VERSION "Version"

NS_ :

BS_:

BU_: ADC FLR FRR Tester

BO_ 791 FRR_Obj_22: 32 FRR
 SG_ SGU22_Msg_CheckSum : 7|8@0+ (1,0) [0|255] ""  ADC
 SG_ SGU22_Msg_AliveCounter : 11|4@0+ (1,0) [0|14] ""  ADC
 SG_ SGU22_BlockCounter : 15|4@0+ (1,0) [0|15] ""  ADC
 SG_ SGU22_Object_ID : 23|8@0+ (1,0) [0|255] ""  ADC
 SG_ SGU22_Object_wExist : 28|5@0+ (0.03125,0) [0|0.96875] ""  ADC
 SG_ SGU22_Object_Type : 31|3@0+ (1,0) [0|7] ""  ADC
 SG_ SGU22_Object_Motion_Pattern : 34|3@0+ (1,0) [0|7] ""  ADC
 SG_ SGU22_Object_wObstacle : 39|5@0+ (0.03125,0) [0|0.96875] ""  ADC
 SG_ SGU22_Object_dx : 43|12@0+ (0.0625,-128) [-128|127.9375] "m"  ADC
 SG_ SGU22_Object_dy : 59|12@0+ (0.125,-128) [-128|127.875] "m"  ADC
 SG_ SGU22_Object_DistLong_rms : 79|16@0+ (0.001953125,0) [0|127.998046875] "m"  ADC
 SG_ SGU22_Obj_DistLat_rms : 95|16@0+ (0.001953125,0) [0|127.998046875] "m"  ADC
 SG_ SGU22_Object_vx : 107|12@0+ (0.0625,-128) [-128|127.9375] "m/s"  ADC
 SG_ SGU22_Object_vy : 123|12@0+ (0.0625,-128) [-128|127.9375] "m/s"  ADC
 SG_ SGU22_Obj_VrelLong_rms : 143|16@0+ (0.001953125,0) [0|127.998046875] "m/s"  ADC
 SG_ SGU22_Obj_Vrelat_rms : 159|16@0+ (0.001953125,0) [0|127.998046875] "m/s"  ADC
 SG_ SGU22_Object_ax : 170|11@0+ (0.03125,-16) [-16|15.96875] "m/s^2"  ADC
 SG_ SGU22_Object_ay : 191|11@0+ (0.03125,-16) [-16|15.96875] "m/s^2"  ADC
 SG_ SGU22_Object_DetStatus : 173|3@0+ (1,0) [0|7] ""  ADC
 SG_ SGU22_LifeCycles_OBJ : 196|8@0+ (1,0) [0|255] ""  ADC
 SG_ SGU22_ObjRCS_22 : 204|10@0+ (0.125,-50) [-50|70] "dBm2"  ADC
 SG_ SGU22_Object_dx_Rear : 209|12@0+ (0.0625,-128) [-128|127.9375] "m"  ADC
 SG_ SGU22_Object_dy_Rear : 229|12@0+ (0.125,-128) [-128|127.875] "m"  ADC

BO_ 792 FRR_Obj_23: 32 FRR
 SG_ SGU23_Msg_CheckSum : 7|8@0+ (1,0) [0|255] ""  ADC
 SG_ SGU23_Msg_AliveCounter : 11|4@0+ (1,0) [0|14] ""  ADC
 SG_ SGU23_BlockCounter : 15|4@0+ (1,0) [0|15] ""  ADC
 SG_ SGU23_Object_ID : 23|8@0+ (1,0) [0|255] ""  ADC
 SG_ SGU23_Object_wExist : 28|5@0+ (0.03125,0) [0|0.96875] ""  ADC
 SG_ SGU23_Object_Type : 31|3@0+ (1,0) [0|7] ""  ADC
 SG_ SGU23_Object_Motion_Pattern : 34|3@0+ (1,0) [0|7] ""  ADC
 SG_ SGU23_Object_wObstacle : 39|5@0+ (0.03125,0) [0|0.96875] ""  ADC
 SG_ SGU23_Object_dx : 43|12@0+ (0.0625,-128) [-128|127.9375] "m"  ADC
 SG_ SGU23_Object_dy : 59|12@0+ (0.125,-128) [-128|127.875] "m"  ADC
 SG_ SGU23_Object_DistLong_rms : 79|16@0+ (0.001953125,0) [0|127.998046875] "m"  ADC
 SG_ SGU23_Obj_DistLat_rms : 95|16@0+ (0.001953125,0) [0|127.998046875] "m"  ADC
 SG_ SGU23_Object_vx : 107|12@0+ (0.0625,-128) [-128|127.9375] "m/s"  ADC
 SG_ SGU23_Object_vy : 123|12@0+ (0.0625,-128) [-128|127.9375] "m/s"  ADC
 SG_ SGU23_Obj_VrelLong_rms : 143|16@0+ (0.001953125,0) [0|127.998046875] "m/s"  ADC
 SG_ SGU23_Obj_Vrelat_rms : 159|16@0+ (0.001953125,0) [0|127.998046875] "m/s"  ADC
 SG_ SGU23_Object_ax : 170|11@0+ (0.03125,-16) [-16|15.96875] "m/s^2"  ADC
 SG_ SGU23_Object_ay : 191|11@0+ (0.03125,-16) [-16|15.96875] "m/s^2"  ADC
 SG_ SGU23_Object_DetStatus : 173|3@0+ (1,0) [0|7] ""  ADC
 SG_ SGU23_LifeCycles_OBJ : 196|8@0+ (1,0) [0|255] ""  ADC
 SG_ SGU23_ObjRCS_23 : 204|10@0+ (0.125,-50) [-50|70] "dBm2"  ADC
 SG_ SGU23_Object_dx_Rear : 209|12@0+ (0.0625,-128) [-128|127.9375] "m"  ADC
 SG_ SGU23_Object_dy_Rear : 229|12@0+ (0.125,-128) [-128|127.875] "m"  ADC

BO_ 793 FRR_Obj_24: 32 FRR
 SG_ SGU24_Msg_CheckSum : 7|8@0+ (1,0) [0|255] ""  ADC
 SG_ SGU24_Msg_AliveCounter : 11|4@0+ (1,0) [0|14] ""  ADC
 SG_ SGU24_BlockCounter : 15|4@0+ (1,0) [0|15] ""  ADC
 SG_ SGU24_Object_ID : 23|8@0+ (1,0) [0|255] ""  ADC
 SG_ SGU24_Object_wExist : 28|5@0+ (0.03125,0) [0|0.96875] ""  ADC
 SG_ SGU24_Object_Type : 31|3@0+ (1,0) [0|7] ""  ADC
 SG_ SGU24_Object_Motion_Pattern : 34|3@0+ (1,0) [0|7] ""  ADC
 SG_ SGU24_Object_wObstacle : 39|5@0+ (0.03125,0) [0|0.96875] ""  ADC
 SG_ SGU24_Object_dx : 43|12@0+ (0.0625,-128) [-128|127.9375] "m"  ADC
 SG_ SGU24_Object_dy : 59|12@0+ (0.125,-128) [-128|127.875] "m"  ADC
 SG_ SGU24_Object_DistLong_rms : 79|16@0+ (0.001953125,0) [0|127.998046875] "m"  ADC
 SG_ SGU24_Obj_DistLat_rms : 95|16@0+ (0.001953125,0) [0|127.998046875] "m"  ADC
 SG_ SGU24_Object_vx : 107|12@0+ (0.0625,-128) [-128|127.9375] "m/s"  ADC
 SG_ SGU24_Object_vy : 123|12@0+ (0.0625,-128) [-128|127.9375] "m/s"  ADC
 SG_ SGU24_Obj_VrelLong_rms : 143|16@0+ (0.001953125,0) [0|127.998046875] "m/s"  ADC
 SG_ SGU24_Obj_Vrelat_rms : 159|16@0+ (0.001953125,0) [0|127.998046875] "m/s"  ADC
 SG_ SGU24_Object_ax : 170|11@0+ (0.03125,-16) [-16|15.96875] "m/s^2"  ADC
 SG_ SGU24_Object_ay : 191|11@0+ (0.03125,-16) [-16|15.96875] "m/s^2"  ADC
 SG_ SGU24_Object_DetStatus : 173|3@0+ (1,0) [0|7] ""  ADC
 SG_ SGU24_LifeCycles_OBJ : 196|8@0+ (1,0) [0|255] ""  ADC
 SG_ SGU24_ObjRCS_24 : 204|10@0+ (0.125,-50) [-50|70] "dBm2"  ADC
 SG_ SGU24_Object_dx_Rear : 209|12@0+ (0.0625,-128) [-128|127.9375] "m"  ADC
 SG_ SGU24_Object_dy_Rear : 229|12@0+ (0.125,-128) [-128|127.875] "m"  ADC

BO_ 794 FRR_Obj_25: 32 FRR
 SG_ SGU25_Msg_CheckSum : 7|8@0+ (1,0) [0|255] ""  ADC
 SG_ SGU25_Msg_AliveCounter : 11|4@0+ (1,0) [0|14] ""  ADC
 SG_ SGU25_BlockCounter : 15|4@0+ (1,0) [0|15] ""  ADC
 SG_ SGU25_Object_ID : 23|8@0+ (1,0) [0|255] ""  ADC
 SG_ SGU25_Object_wExist : 28|5@0+ (0.03125,0) [0|0.96875] ""  ADC
 SG_ SGU25_Object_Type : 31|3@0+ (1,0) [0|7] ""  ADC
 SG_ SGU25_Object_Motion_Pattern : 34|3@0+ (1,0) [0|7] ""  ADC
 SG_ SGU25_Object_wObstacle : 39|5@0+ (0.03125,0) [0|0.96875] ""  ADC
 SG_ SGU25_Object_dx : 43|12@0+ (0.0625,-128) [-128|127.9375] "m"  ADC
 SG_ SGU25_Object_dy : 59|12@0+ (0.125,-128) [-128|127.875] "m"  ADC
 SG_ SGU25_Object_DistLong_rms : 79|16@0+ (0.001953125,0) [0|127.998046875] "m"  ADC
 SG_ SGU25_Obj_DistLat_rms : 95|16@0+ (0.001953125,0) [0|127.998046875] "m"  ADC
 SG_ SGU25_Object_vx : 107|12@0+ (0.0625,-128) [-128|127.9375] "m/s"  ADC
 SG_ SGU25_Object_vy : 123|12@0+ (0.0625,-128) [-128|127.9375] "m/s"  ADC
 SG_ SGU25_Obj_VrelLong_rms : 143|16@0+ (0.001953125,0) [0|127.998046875] "m/s"  ADC
 SG_ SGU25_Obj_Vrelat_rms : 159|16@0+ (0.001953125,0) [0|127.998046875] "m/s"  ADC
 SG_ SGU25_Object_ax : 170|11@0+ (0.03125,-16) [-16|15.96875] "m/s^2"  ADC
 SG_ SGU25_Object_ay : 191|11@0+ (0.03125,-16) [-16|15.96875] "m/s^2"  ADC
 SG_ SGU25_Object_DetStatus : 173|3@0+ (1,0) [0|7] ""  ADC
 SG_ SGU25_LifeCycles_OBJ : 196|8@0+ (1,0) [0|255] ""  ADC
 SG_ SGU25_ObjRCS_25 : 204|10@0+ (0.125,-50) [-50|70] "dBm2"  ADC
 SG_ SGU25_Object_dx_Rear : 209|12@0+ (0.0625,-128) [-128|127.9375] "m"  ADC
 SG_ SGU25_Object_dy_Rear : 229|12@0+ (0.125,-128) [-128|127.875] "m"  ADC

BO_ 795 FRR_Obj_26: 32 FRR
 SG_ SGU26_Msg_CheckSum : 7|8@0+ (1,0) [0|255] ""  ADC
 SG_ SGU26_Msg_AliveCounter : 11|4@0+ (1,0) [0|14] ""  ADC
 SG_ SGU26_BlockCounter : 15|4@0+ (1,0) [0|15] ""  ADC
 SG_ SGU26_Object_ID : 23|8@0+ (1,0) [0|255] ""  ADC
 SG_ SGU26_Object_wExist : 28|5@0+ (0.03125,0) [0|0.96875] ""  ADC
 SG_ SGU26_Object_Type : 31|3@0+ (1,0) [0|7] ""  ADC
 SG_ SGU26_Object_Motion_Pattern : 34|3@0+ (1,0) [0|7] ""  ADC
 SG_ SGU26_Object_wObstacle : 39|5@0+ (0.03125,0) [0|0.96875] ""  ADC
 SG_ SGU26_Object_dx : 43|12@0+ (0.0625,-128) [-128|127.9375] "m"  ADC
 SG_ SGU26_Object_dy : 59|12@0+ (0.125,-128) [-128|127.875] "m"  ADC
 SG_ SGU26_Object_DistLong_rms : 79|16@0+ (0.001953125,0) [0|127.998046875] "m"  ADC
 SG_ SGU26_Obj_DistLat_rms : 95|16@0+ (0.001953125,0) [0|127.998046875] "m"  ADC
 SG_ SGU26_Object_vx : 107|12@0+ (0.0625,-128) [-128|127.9375] "m/s"  ADC
 SG_ SGU26_Object_vy : 123|12@0+ (0.0625,-128) [-128|127.9375] "m/s"  ADC
 SG_ SGU26_Obj_VrelLong_rms : 143|16@0+ (0.001953125,0) [0|127.998046875] "m/s"  ADC
 SG_ SGU26_Obj_Vrelat_rms : 159|16@0+ (0.001953125,0) [0|127.998046875] "m/s"  ADC
 SG_ SGU26_Object_ax : 170|11@0+ (0.03125,-16) [-16|15.96875] "m/s^2"  ADC
 SG_ SGU26_Object_ay : 191|11@0+ (0.03125,-16) [-16|15.96875] "m/s^2"  ADC
 SG_ SGU26_Object_DetStatus : 173|3@0+ (1,0) [0|7] ""  ADC
 SG_ SGU26_LifeCycles_OBJ : 196|8@0+ (1,0) [0|255] ""  ADC
 SG_ SGU26_ObjRCS_26 : 204|10@0+ (0.125,-50) [-50|70] "dBm2"  ADC
 SG_ SGU26_Object_dx_Rear : 209|12@0+ (0.0625,-128) [-128|127.9375] "m"  ADC
 SG_ SGU26_Object_dy_Rear : 229|12@0+ (0.125,-128) [-128|127.875] "m"  ADC

BO_ 796 FRR_Obj_27: 32 FRR
 SG_ SGU27_Msg_CheckSum : 7|8@0+ (1,0) [0|255] ""  ADC
 SG_ SGU27_Msg_AliveCounter : 11|4@0+ (1,0) [0|14] ""  ADC
 SG_ SGU27_BlockCounter : 15|4@0+ (1,0) [0|15] ""  ADC
 SG_ SGU27_Object_ID : 23|8@0+ (1,0) [0|255] ""  ADC
 SG_ SGU27_Object_wExist : 28|5@0+ (0.03125,0) [0|0.96875] ""  ADC
 SG_ SGU27_Object_Type : 31|3@0+ (1,0) [0|7] ""  ADC
 SG_ SGU27_Object_Motion_Pattern : 34|3@0+ (1,0) [0|7] ""  ADC
 SG_ SGU27_Object_wObstacle : 39|5@0+ (0.03125,0) [0|0.96875] ""  ADC
 SG_ SGU27_Object_dx : 43|12@0+ (0.0625,-128) [-128|127.9375] "m"  ADC
 SG_ SGU27_Object_dy : 59|12@0+ (0.125,-128) [-128|127.875] "m"  ADC
 SG_ SGU27_Object_DistLong_rms : 79|16@0+ (0.001953125,0) [0|127.998046875] "m"  ADC
 SG_ SGU27_Obj_DistLat_rms : 95|16@0+ (0.001953125,0) [0|127.998046875] "m"  ADC
 SG_ SGU27_Object_vx : 107|12@0+ (0.0625,-128) [-128|127.9375] "m/s"  ADC
 SG_ SGU27_Object_vy : 123|12@0+ (0.0625,-128) [-128|127.9375] "m/s"  ADC
 SG_ SGU27_Obj_VrelLong_rms : 143|16@0+ (0.001953125,0) [0|127.998046875] "m/s"  ADC
 SG_ SGU27_Obj_Vrelat_rms : 159|16@0+ (0.001953125,0) [0|127.998046875] "m/s"  ADC
 SG_ SGU27_Object_ax : 170|11@0+ (0.03125,-16) [-16|15.96875] "m/s^2"  ADC
 SG_ SGU27_Object_ay : 191|11@0+ (0.03125,-16) [-16|15.96875] "m/s^2"  ADC
 SG_ SGU27_Object_DetStatus : 173|3@0+ (1,0) [0|7] ""  ADC
 SG_ SGU27_LifeCycles_OBJ : 196|8@0+ (1,0) [0|255] ""  ADC
 SG_ SGU27_ObjRCS_27 : 204|10@0+ (0.125,-50) [-50|70] "dBm2"  ADC
 SG_ SGU27_Object_dx_Rear : 209|12@0+ (0.0625,-128) [-128|127.9375] "m"  ADC
 SG_ SGU27_Object_dy_Rear : 229|12@0+ (0.125,-128) [-128|127.875] "m"  ADC

BO_ 797 FRR_Obj_28: 32 FRR
 SG_ SGU28_Msg_CheckSum : 7|8@0+ (1,0) [0|255] ""  ADC
 SG_ SGU28_Msg_AliveCounter : 11|4@0+ (1,0) [0|14] ""  ADC
 SG_ SGU28_BlockCounter : 15|4@0+ (1,0) [0|15] ""  ADC
 SG_ SGU28_Object_ID : 23|8@0+ (1,0) [0|255] ""  ADC
 SG_ SGU28_Object_wExist : 28|5@0+ (0.03125,0) [0|0.96875] ""  ADC
 SG_ SGU28_Object_Type : 31|3@0+ (1,0) [0|7] ""  ADC
 SG_ SGU28_Object_Motion_Pattern : 34|3@0+ (1,0) [0|7] ""  ADC
 SG_ SGU28_Object_wObstacle : 39|5@0+ (0.03125,0) [0|0.96875] ""  ADC
 SG_ SGU28_Object_dx : 43|12@0+ (0.0625,-128) [-128|127.9375] "m"  ADC
 SG_ SGU28_Object_dy : 59|12@0+ (0.125,-128) [-128|127.875] "m"  ADC
 SG_ SGU28_Object_DistLong_rms : 79|16@0+ (0.001953125,0) [0|127.998046875] "m"  ADC
 SG_ SGU28_Obj_DistLat_rms : 95|16@0+ (0.001953125,0) [0|127.998046875] "m"  ADC
 SG_ SGU28_Object_vx : 107|12@0+ (0.0625,-128) [-128|127.9375] "m/s"  ADC
 SG_ SGU28_Object_vy : 123|12@0+ (0.0625,-128) [-128|127.9375] "m/s"  ADC
 SG_ SGU28_Obj_VrelLong_rms : 143|16@0+ (0.001953125,0) [0|127.998046875] "m/s"  ADC
 SG_ SGU28_Obj_Vrelat_rms : 159|16@0+ (0.001953125,0) [0|127.998046875] "m/s"  ADC
 SG_ SGU28_Object_ax : 170|11@0+ (0.03125,-16) [-16|15.96875] "m/s^2"  ADC
 SG_ SGU28_Object_ay : 191|11@0+ (0.03125,-16) [-16|15.96875] "m/s^2"  ADC
 SG_ SGU28_Object_DetStatus : 173|3@0+ (1,0) [0|7] ""  ADC
 SG_ SGU28_LifeCycles_OBJ : 196|8@0+ (1,0) [0|255] ""  ADC
 SG_ SGU28_ObjRCS_28 : 204|10@0+ (0.125,-50) [-50|70] "dBm2"  ADC
 SG_ SGU28_Object_dx_Rear : 209|12@0+ (0.0625,-128) [-128|127.9375] "m"  ADC
 SG_ SGU28_Object_dy_Rear : 229|12@0+ (0.125,-128) [-128|127.875] "m"  ADC

BO_ 798 FRR_Obj_29: 32 FRR
 SG_ SGU29_Msg_CheckSum : 7|8@0+ (1,0) [0|255] ""  ADC
 SG_ SGU29_Msg_AliveCounter : 11|4@0+ (1,0) [0|14] ""  ADC
 SG_ SGU29_BlockCounter : 15|4@0+ (1,0) [0|15] ""  ADC
 SG_ SGU29_Object_ID : 23|8@0+ (1,0) [0|255] ""  ADC
 SG_ SGU29_Object_wExist : 28|5@0+ (0.03125,0) [0|0.96875] ""  ADC
 SG_ SGU29_Object_Type : 31|3@0+ (1,0) [0|7] ""  ADC
 SG_ SGU29_Object_Motion_Pattern : 34|3@0+ (1,0) [0|7] ""  ADC
 SG_ SGU29_Object_wObstacle : 39|5@0+ (0.03125,0) [0|0.96875] ""  ADC
 SG_ SGU29_Object_dx : 43|12@0+ (0.0625,-128) [-128|127.9375] "m"  ADC
 SG_ SGU29_Object_dy : 59|12@0+ (0.125,-128) [-128|127.875] "m"  ADC
 SG_ SGU29_Object_DistLong_rms : 79|16@0+ (0.001953125,0) [0|127.998046875] "m"  ADC
 SG_ SGU29_Obj_DistLat_rms : 95|16@0+ (0.001953125,0) [0|127.998046875] "m"  ADC
 SG_ SGU29_Object_vx : 107|12@0+ (0.0625,-128) [-128|127.9375] "m/s"  ADC
 SG_ SGU29_Object_vy : 123|12@0+ (0.0625,-128) [-128|127.9375] "m/s"  ADC
 SG_ SGU29_Obj_VrelLong_rms : 143|16@0+ (0.001953125,0) [0|127.998046875] "m/s"  ADC
 SG_ SGU29_Obj_Vrelat_rms : 159|16@0+ (0.001953125,0) [0|127.998046875] "m/s"  ADC
 SG_ SGU29_Object_ax : 170|11@0+ (0.03125,-16) [-16|15.96875] "m/s^2"  ADC
 SG_ SGU29_Object_ay : 191|11@0+ (0.03125,-16) [-16|15.96875] "m/s^2"  ADC
 SG_ SGU29_Object_DetStatus : 173|3@0+ (1,0) [0|7] ""  ADC
 SG_ SGU29_LifeCycles_OBJ : 196|8@0+ (1,0) [0|255] ""  ADC
 SG_ SGU29_ObjRCS_29 : 204|10@0+ (0.125,-50) [-50|70] "dBm2"  ADC
 SG_ SGU29_Object_dx_Rear : 209|12@0+ (0.0625,-128) [-128|127.9375] "m"  ADC
 SG_ SGU29_Object_dy_Rear : 229|12@0+ (0.125,-128) [-128|127.875] "m"  ADC

BO_ 799 FRR_Obj_30: 32 FRR
 SG_ SGU30_Msg_CheckSum : 7|8@0+ (1,0) [0|255] ""  ADC
 SG_ SGU30_Msg_AliveCounter : 11|4@0+ (1,0) [0|14] ""  ADC
 SG_ SGU30_BlockCounter : 15|4@0+ (1,0) [0|15] ""  ADC
 SG_ SGU30_Object_ID : 23|8@0+ (1,0) [0|255] ""  ADC
 SG_ SGU30_Object_wExist : 28|5@0+ (0.03125,0) [0|0.96875] ""  ADC
 SG_ SGU30_Object_Type : 31|3@0+ (1,0) [0|7] ""  ADC
 SG_ SGU30_Object_Motion_Pattern : 34|3@0+ (1,0) [0|7] ""  ADC
 SG_ SGU30_Object_wObstacle : 39|5@0+ (0.03125,0) [0|0.96875] ""  ADC
 SG_ SGU30_Object_dx : 43|12@0+ (0.0625,-128) [-128|127.9375] "m"  ADC
 SG_ SGU30_Object_dy : 59|12@0+ (0.125,-128) [-128|127.875] "m"  ADC
 SG_ SGU30_Object_DistLong_rms : 79|16@0+ (0.001953125,0) [0|127.998046875] "m"  ADC
 SG_ SGU30_Obj_DistLat_rms : 95|16@0+ (0.001953125,0) [0|127.998046875] "m"  ADC
 SG_ SGU30_Object_vx : 107|12@0+ (0.0625,-128) [-128|127.9375] "m/s"  ADC
 SG_ SGU30_Object_vy : 123|12@0+ (0.0625,-128) [-128|127.9375] "m/s"  ADC
 SG_ SGU30_Obj_VrelLong_rms : 143|16@0+ (0.001953125,0) [0|127.998046875] "m/s"  ADC
 SG_ SGU30_Obj_Vrelat_rms : 159|16@0+ (0.001953125,0) [0|127.998046875] "m/s"  ADC
 SG_ SGU30_Object_ax : 170|11@0+ (0.03125,-16) [-16|15.96875] "m/s^2"  ADC
 SG_ SGU30_Object_ay : 191|11@0+ (0.03125,-16) [-16|15.96875] "m/s^2"  ADC
 SG_ SGU30_Object_DetStatus : 173|3@0+ (1,0) [0|7] ""  ADC
 SG_ SGU30_LifeCycles_OBJ : 196|8@0+ (1,0) [0|255] ""  ADC
 SG_ SGU30_ObjRCS_30 : 204|10@0+ (0.125,-50) [-50|70] "dBm2"  ADC
 SG_ SGU30_Object_dx_Rear : 209|12@0+ (0.0625,-128) [-128|127.9375] "m"  ADC
 SG_ SGU30_Object_dy_Rear : 229|12@0+ (0.125,-128) [-128|127.875] "m"  ADC

BO_ 800 FRR_Obj_31: 32 FRR
 SG_ SGU31_Msg_CheckSum : 7|8@0+ (1,0) [0|255] ""  ADC
 SG_ SGU31_Msg_AliveCounter : 11|4@0+ (1,0) [0|14] ""  ADC
 SG_ SGU31_BlockCounter : 15|4@0+ (1,0) [0|15] ""  ADC
 SG_ SGU31_Object_ID : 23|8@0+ (1,0) [0|255] ""  ADC
 SG_ SGU31_Object_wExist : 28|5@0+ (0.03125,0) [0|0.96875] ""  ADC
 SG_ SGU31_Object_Type : 31|3@0+ (1,0) [0|7] ""  ADC
 SG_ SGU31_Object_Motion_Pattern : 34|3@0+ (1,0) [0|7] ""  ADC
 SG_ SGU31_Object_wObstacle : 39|5@0+ (0.03125,0) [0|0.96875] ""  ADC
 SG_ SGU31_Object_dx : 43|12@0+ (0.0625,-128) [-128|127.9375] "m"  ADC
 SG_ SGU31_Object_dy : 59|12@0+ (0.125,-128) [-128|127.875] "m"  ADC
 SG_ SGU31_Object_DistLong_rms : 79|16@0+ (0.001953125,0) [0|127.998046875] "m"  ADC
 SG_ SGU31_Obj_DistLat_rms : 95|16@0+ (0.001953125,0) [0|127.998046875] "m"  ADC
 SG_ SGU31_Object_vx : 107|12@0+ (0.0625,-128) [-128|127.9375] "m/s"  ADC
 SG_ SGU31_Object_vy : 123|12@0+ (0.0625,-128) [-128|127.9375] "m/s"  ADC
 SG_ SGU31_Obj_VrelLong_rms : 143|16@0+ (0.001953125,0) [0|127.998046875] "m/s"  ADC
 SG_ SGU31_Obj_Vrelat_rms : 159|16@0+ (0.001953125,0) [0|127.998046875] "m/s"  ADC
 SG_ SGU31_Object_ax : 170|11@0+ (0.03125,-16) [-16|15.96875] "m/s^2"  ADC
 SG_ SGU31_Object_ay : 191|11@0+ (0.03125,-16) [-16|15.96875] "m/s^2"  ADC
 SG_ SGU31_Object_DetStatus : 173|3@0+ (1,0) [0|7] ""  ADC
 SG_ SGU31_LifeCycles_OBJ : 196|8@0+ (1,0) [0|255] ""  ADC
 SG_ SGU31_ObjRCS_31 : 204|10@0+ (0.125,-50) [-50|70] "dBm2"  ADC
 SG_ SGU31_Object_dx_Rear : 209|12@0+ (0.0625,-128) [-128|127.9375] "m"  ADC
 SG_ SGU31_Object_dy_Rear : 229|12@0+ (0.125,-128) [-128|127.875] "m"  ADC

BO_ 801 FRR_Obj_32: 32 FRR
 SG_ SGU32_Msg_CheckSum : 7|8@0+ (1,0) [0|255] ""  ADC
 SG_ SGU32_Msg_AliveCounter : 11|4@0+ (1,0) [0|14] ""  ADC
 SG_ SGU32_BlockCounter : 15|4@0+ (1,0) [0|15] ""  ADC
 SG_ SGU32_Object_ID : 23|8@0+ (1,0) [0|255] ""  ADC
 SG_ SGU32_Object_wExist : 28|5@0+ (0.03125,0) [0|0.96875] ""  ADC
 SG_ SGU32_Object_Type : 31|3@0+ (1,0) [0|7] ""  ADC
 SG_ SGU32_Object_Motion_Pattern : 34|3@0+ (1,0) [0|7] ""  ADC
 SG_ SGU32_Object_wObstacle : 39|5@0+ (0.03125,0) [0|0.96875] ""  ADC
 SG_ SGU32_Object_dx : 43|12@0+ (0.0625,-128) [-128|127.9375] "m"  ADC
 SG_ SGU32_Object_dy : 59|12@0+ (0.125,-128) [-128|127.875] "m"  ADC
 SG_ SGU32_Object_DistLong_rms : 79|16@0+ (0.001953125,0) [0|127.998046875] "m"  ADC
 SG_ SGU32_Obj_DistLat_rms : 95|16@0+ (0.001953125,0) [0|127.998046875] "m"  ADC
 SG_ SGU32_Object_vx : 107|12@0+ (0.0625,-128) [-128|127.9375] "m/s"  ADC
 SG_ SGU32_Object_vy : 123|12@0+ (0.0625,-128) [-128|127.9375] "m/s"  ADC
 SG_ SGU32_Obj_VrelLong_rms : 143|16@0+ (0.001953125,0) [0|127.998046875] "m/s"  ADC
 SG_ SGU32_Obj_Vrelat_rms : 159|16@0+ (0.001953125,0) [0|127.998046875] "m/s"  ADC
 SG_ SGU32_Object_ax : 170|11@0+ (0.03125,-16) [-16|15.96875] "m/s^2"  ADC
 SG_ SGU32_Object_ay : 191|11@0+ (0.03125,-16) [-16|15.96875] "m/s^2"  ADC
 SG_ SGU32_Object_DetStatus : 173|3@0+ (1,0) [0|7] ""  ADC
 SG_ SGU32_LifeCycles_OBJ : 196|8@0+ (1,0) [0|255] ""  ADC
 SG_ SGU32_ObjRCS_32 : 204|10@0+ (0.125,-50) [-50|70] "dBm2"  ADC
 SG_ SGU32_Object_dx_Rear : 209|12@0+ (0.0625,-128) [-128|127.9375] "m"  ADC
 SG_ SGU32_Object_dy_Rear : 229|12@0+ (0.125,-128) [-128|127.875] "m"  ADC

BO_ 802 FRR_RadarInfo: 32 FRR
 SG_ FRR_RadarInfor_Checksum : 7|8@0+ (1,0) [0|255] ""  ADC
 SG_ FRR_RadarInfor_AliveCounter : 11|4@0+ (1,0) [0|14] ""  ADC
 SG_ mountAngleIndicator_az : 31|9@0+ (0.05,-12.8) [-12.8|12.75] "degree"  ADC
 SG_ mountAngleCurrent_az : 38|9@0+ (0.05,-12.8) [-12.8|12.75] "degree"  ADC
 SG_ mountAngleIndicator_el : 45|9@0+ (0.05,-12.8) [-12.8|12.75] "degree"  ADC
 SG_ mountAngleCurrent_el : 52|9@0+ (0.05,-12.8) [-12.8|12.75] "degree"  ADC
 SG_ malStablePosAz : 59|9@0+ (0.05,-12.8) [-12.8|12.75] "degree"  ADC
 SG_ malStablePosEl : 66|9@0+ (0.05,-12.8) [-12.8|12.75] "degree"  ADC
 SG_ AngleEMEIndicatorAz : 73|9@0+ (0.05,-12.8) [-12.8|12.75] "degree"  ADC
 SG_ AngleEMEIndicatorEl : 95|9@0+ (0.05,-12.8) [-12.8|12.75] "degree"  ADC
 SG_ FilteredPhiSpread : 102|11@0+ (0.1,-102.4) [-102.4|102.3] "m"  ADC
 SG_ highSpreadIndicator_el : 107|9@0+ (0.05,-12.8) [-12.8|12.75] "degree"  ADC
 SG_ highSpreadIndicator_az : 114|9@0+ (0.05,-12.8) [-12.8|12.75] "degree"  ADC
 SG_ elOutOfSpecCause : 129|2@0+ (1,0) [0|3] ""  ADC
 SG_ azOutOfSpecCause : 131|2@0+ (1,0) [0|3] ""  ADC
 SG_ Fault_MAL_HOR_ABS_EVENT : 132|1@0+ (1,0) [0|1] ""  ADC
 SG_ Fault_MAL_HOR_REL_EVENT : 133|1@0+ (1,0) [0|1] ""  ADC
 SG_ Fault_MAL_VER_ABS_EVENT : 134|1@0+ (1,0) [0|1] ""  ADC
 SG_ Fault_MAL_VER_REL_EVENT : 135|1@0+ (1,0) [0|1] ""  ADC
 SG_ azOutOfProfileCause : 143|8@0+ (1,0) [0|255] ""  ADC
 SG_ elOutOfProfileCause : 151|8@0+ (1,0) [0|255] ""  ADC
 SG_ FRR_SW_Baseline : 155|4@0+ (1,0) [0|15] ""  ADC
 SG_ FRR_SW_ReleaseType : 159|4@0+ (1,0) [0|15] ""  ADC
 SG_ FRR_SW_MajorVersion : 163|4@0+ (1,0) [0|15] ""  ADC
 SG_ FRR_SW_MinorVersion : 167|4@0+ (1,0) [0|15] ""  ADC
 SG_ FRR_SDA_CalibrationSts : 175|8@0+ (1,0) [0|255] ""  ADC
 SG_ FRR_EOL_CalibrationSts : 183|8@0+ (1,0) [0|255] ""  ADC
 SG_ FRR_Blindness_FaultSts : 192|1@0+ (1,0) [0|1] ""  ADC
 SG_ FRR_ModulationSts : 193|1@0+ (1,0) [0|1] ""  ADC
 SG_ FRR_Misalignment_FaultSts : 194|1@0+ (1,0) [0|1] ""  ADC
 SG_ FRR_Radar_FaultSts : 207|8@0+ (1,0) [0|31] ""  ADC
 SG_ FRR_DTC_VBAT_HIGH : 208|1@0+ (1,0) [0|1] ""  ADC
 SG_ FRR_DTC_VBAT_LOW : 209|1@0+ (1,0) [0|1] ""  ADC
 SG_ FRR_DTC_HARDWARE_FAILURE : 210|1@0+ (1,0) [0|1] ""  ADC
 SG_ FRR_DTC_RADAR_OVER_TEMPERATURE : 211|1@0+ (1,0) [0|1] ""  ADC
 SG_ FRR_DTC_CORNER_RADAR_BLIND : 212|1@0+ (1,0) [0|1] ""  ADC
 SG_ FRR_DTC_CORNER_RADAR_MISALIGNED : 213|1@0+ (1,0) [0|1] ""  ADC
 SG_ FRR_DTC_DACORE_OOS : 214|1@0+ (1,0) [0|1] ""  ADC
 SG_ FRR_DTC_DSP_FAILURE : 215|1@0+ (1,0) [0|1] ""  ADC
 SG_ FRR_DTC_VARIANT_SELECTION_NOT_DONE : 216|1@0+ (1,0) [0|1] ""  ADC
 SG_ FRR_DTC_RADAR_SIDE_MISMATCH : 217|1@0+ (1,0) [0|1] ""  ADC
 SG_ FRR_DTC_ALIGNMENT_NOT_DONE : 218|1@0+ (1,0) [0|1] ""  ADC
 SG_ FRR_DTC_PUBLIC_CAN_BUSOFF : 219|1@0+ (1,0) [0|1] ""  ADC
 SG_ FRR_DTC_LOST_COMM_EPS : 222|1@0+ (1,0) [0|1] ""  ADC
 SG_ FRR_DTC_INVALID_DATA_EPS : 223|1@0+ (1,0) [0|1] ""  ADC
 SG_ FRR_DTC_LOST_COMM_BCS : 224|1@0+ (1,0) [0|1] ""  ADC
 SG_ FRR_DTC_INVALID_DATA_BCS : 225|1@0+ (1,0) [0|1] ""  ADC
 SG_ FRR_DTC_LOST_COMM_SOC : 230|1@0+ (1,0) [0|1] ""  ADC
 SG_ FRR_DTC_INVALID_DATA_SOC : 231|1@0+ (1,0) [0|1] ""  ADC
 SG_ FRR_DTC_SOC_Time_SYNC_FAIL : 232|1@0+ (1,0) [0|1] ""  ADC

BO_ 1147 FLR_DiagCode: 64 FLR
 SG_ FLR_Diag_Response : 7|512@0+ (1,0) [0|0] "" ADC

BO_ 1148 FRR_DiagCode: 64 FRR
 SG_ FRR_Diag_Response : 7|512@0+ (1,0) [0|0] "" ADC

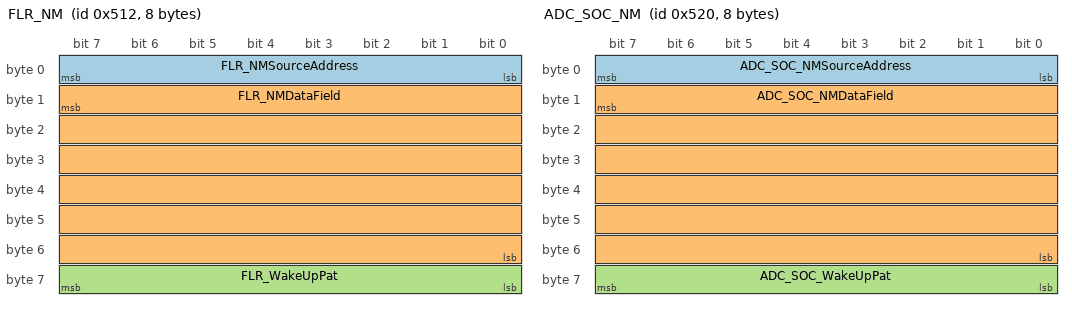
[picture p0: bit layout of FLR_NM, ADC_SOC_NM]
BO_ 1298 FLR_NM: 8 FLR
 SG_ FLR_NMSourceAddress : 7|8@0+ (1,0) [0|255] ""  ADC
 SG_ FLR_NMDataField : 15|48@0+ (1,0) [0|65535] ""  ADC
 SG_ FLR_WakeUpPat : 63|8@0+ (1,0) [0|255] ""  ADC

BO_ 1312 ADC_SOC_NM: 8 ADC
 SG_ ADC_SOC_NMSourceAddress : 7|8@0+ (1,0) [0|255] ""  FLR,FRR
 SG_ ADC_SOC_NMDataField : 15|48@0+ (1,0) [0|65535] ""  FLR,FRR
 SG_ ADC_SOC_WakeUpPat : 63|8@0+ (1,0) [0|255] ""  FLR,FRR

BO_ 1810 FLR_Phys_Diag_Rx: 64 ADC
 SG_ FLR_Diag_Request : 7|512@0+ (1,0) [0|0] "" Vector__XXX

BO_ 1811 FRR_Phys_Diag_Rx: 64 ADC
 SG_ FRR_Diag_Request : 7|512@0+ (1,0) [0|0] "" Vector__XXX

BO_ 1938 FLR_Diag_Tx: 64 FLR
 SG_ FLR_Diag_Response : 7|512@0+ (1,0) [0|18446744073709551615] "" ADC

BO_ 1939 FRR_Diag_Tx: 64 FRR
 SG_ FRR_Diag_Response : 7|512@0+ (1,0) [0|18446744073709551615] "" ADC

BO_ 2015 Func_Diag_Rx: 64 ADC
 SG_ Func_Diag_Request : 7|512@0+ (1,0) [0|0] "" Vector__XXX

BA_DEF_ BO_  "CANFD_BRS" ENUM  "0","1";
BA_DEF_ BO_  "GenMsgCycleTime" INT 0 0;
BA_DEF_ BO_  "GenMsgCycleTimeFast" INT 0 0;
BA_DEF_ BO_  "GenMsgSendType" ENUM  "Periodic","Event","IfActive","POE","PA","FixedPeriodic","Event","EnabledPeriodic","NotUsed","NotUsed","EventPeriodic","NotUsed","NotUsed","NoMsgSendType";
BA_DEF_ BO_  "VFrameFormat" ENUM  "StandardCAN","ExtendedCAN","reserved","reserved","reserved","reserved","reserved","reserved","reserved","reserved","reserved","reserved","reserved","reserved","StandardCAN_FD","ExtendedCAN_FD";
BA_DEF_ SG_  "EventCommandSignal" ENUM  "No","Yes";
BA_DEF_ SG_  "GatewayedSignals" ENUM  "No","Yes";
BA_DEF_ SG_  "GenSigInactiveValue" HEX 0 0;
BA_DEF_ SG_  "GenSigInvalidValue" HEX 0 0;
BA_DEF_ SG_  "GenSigSendType" ENUM  "Trigger","Passive","Cyclic","OnWrite","OnWriteWithRepetition","OnChange","OnChangeWithRepetition","IfActive","IfActiveWithRepetition","NoSigSendType";
BA_DEF_ SG_  "GenSigStartValue" HEX 0 0;
BA_DEF_ SG_  "GenSigTimeoutValue" HEX 0 0;
BA_DEF_ SG_  "Remark" STRING ;
BA_DEF_ BO_  "GenMsgILSupport" ENUM  "No","Yes";
BA_DEF_ BO_  "MsgType" ENUM  "Normal","NM","Diag","vector_leerstring";
BA_DEF_ BO_  "NmAsrMessage" ENUM  "No","Yes";
BA_DEF_ SG_  "IsCrcSignal" ENUM  "No","Yes";
BA_DEF_ SG_  "SystemSignalLongSymbol" STRING ;

BA_DEF_DEF_  "GenMsgILSupport" "Yes";
BA_DEF_DEF_  "IsCrcSignal" "No";
BA_DEF_DEF_  "MsgType" "";
BA_DEF_DEF_  "NmAsrMessage" "No";
BA_DEF_DEF_  "SystemSignalLongSymbol" "";
BA_ "CANFD_BRS" BO_ 791 1;
BA_ "CANFD_BRS" BO_ 792 1;
BA_ "CANFD_BRS" BO_ 793 1;
BA_ "CANFD_BRS" BO_ 794 1;
BA_ "CANFD_BRS" BO_ 795 1;
BA_ "CANFD_BRS" BO_ 796 1;
BA_ "CANFD_BRS" BO_ 797 1;
BA_ "CANFD_BRS" BO_ 798 1;
BA_ "CANFD_BRS" BO_ 799 1;
BA_ "CANFD_BRS" BO_ 800 1;
BA_ "CANFD_BRS" BO_ 801 1;
BA_ "CANFD_BRS" BO_ 802 1;
BA_ "CANFD_BRS" BO_ 1147 1;
BA_ "CANFD_BRS" BO_ 1148 1;
BA_ "CANFD_BRS" BO_ 1298 1;
BA_ "CANFD_BRS" BO_ 1312 1;
BA_ "CANFD_BRS" BO_ 1810 1;
BA_ "CANFD_BRS" BO_ 1811 1;
BA_ "CANFD_BRS" BO_ 1938 1;
BA_ "CANFD_BRS" BO_ 1939 1;
BA_ "CANFD_BRS" BO_ 2015 1;
BA_ "GenMsgCycleTime" BO_ 791 0;
BA_ "GenMsgCycleTime" BO_ 792 0;
BA_ "GenMsgCycleTime" BO_ 793 0;
BA_ "GenMsgCycleTime" BO_ 794 0;
BA_ "GenMsgCycleTime" BO_ 795 0;
BA_ "GenMsgCycleTime" BO_ 796 0;
BA_ "GenMsgCycleTime" BO_ 797 0;
BA_ "GenMsgCycleTime" BO_ 798 0;
BA_ "GenMsgCycleTime" BO_ 799 0;
BA_ "GenMsgCycleTime" BO_ 800 0;
BA_ "GenMsgCycleTime" BO_ 801 0;
BA_ "GenMsgCycleTime" BO_ 802 50;
BA_ "GenMsgCycleTime" BO_ 1147 0;
BA_ "GenMsgCycleTime" BO_ 1148 0;
BA_ "GenMsgCycleTime" BO_ 1298 200;
BA_ "GenMsgCycleTime" BO_ 1312 200;
BA_ "GenMsgCycleTime" BO_ 1810 0;
BA_ "GenMsgCycleTime" BO_ 1811 0;
BA_ "GenMsgCycleTime" BO_ 1938 0;
BA_ "GenMsgCycleTime" BO_ 1939 0;
BA_ "GenMsgCycleTime" BO_ 2015 0;
BA_ "GenMsgCycleTimeFast" BO_ 791 0;
BA_ "GenMsgCycleTimeFast" BO_ 792 0;
BA_ "GenMsgCycleTimeFast" BO_ 793 0;
BA_ "GenMsgCycleTimeFast" BO_ 794 0;
BA_ "GenMsgCycleTimeFast" BO_ 795 0;
BA_ "GenMsgCycleTimeFast" BO_ 796 0;
BA_ "GenMsgCycleTimeFast" BO_ 797 0;
BA_ "GenMsgCycleTimeFast" BO_ 798 0;
BA_ "GenMsgCycleTimeFast" BO_ 799 0;
BA_ "GenMsgCycleTimeFast" BO_ 800 0;
BA_ "GenMsgCycleTimeFast" BO_ 801 0;
BA_ "GenMsgCycleTimeFast" BO_ 802 0;
BA_ "GenMsgCycleTimeFast" BO_ 1147 0;
BA_ "GenMsgCycleTimeFast" BO_ 1148 0;
BA_ "GenMsgCycleTimeFast" BO_ 1298 0;
BA_ "GenMsgCycleTimeFast" BO_ 1312 0;
BA_ "GenMsgCycleTimeFast" BO_ 1810 0;
BA_ "GenMsgCycleTimeFast" BO_ 1811 0;
BA_ "GenMsgCycleTimeFast" BO_ 1938 0;
BA_ "GenMsgCycleTimeFast" BO_ 1939 0;
BA_ "GenMsgCycleTimeFast" BO_ 2015 0;
BA_ "GenMsgSendType" BO_ 791 1;
BA_ "GenMsgSendType" BO_ 792 1;
BA_ "GenMsgSendType" BO_ 793 1;
BA_ "GenMsgSendType" BO_ 794 1;
BA_ "GenMsgSendType" BO_ 795 1;
BA_ "GenMsgSendType" BO_ 796 1;
BA_ "GenMsgSendType" BO_ 797 1;
BA_ "GenMsgSendType" BO_ 798 1;
BA_ "GenMsgSendType" BO_ 799 1;
BA_ "GenMsgSendType" BO_ 800 1;
BA_ "GenMsgSendType" BO_ 801 1;
BA_ "GenMsgSendType" BO_ 802 0;
BA_ "GenMsgSendType" BO_ 1147 1;
BA_ "GenMsgSendType" BO_ 1148 1;
BA_ "GenMsgSendType" BO_ 1298 0;
BA_ "GenMsgSendType" BO_ 1312 0;
BA_ "GenMsgSendType" BO_ 1810 0;
BA_ "GenMsgSendType" BO_ 1811 0;
BA_ "GenMsgSendType" BO_ 1938 0;
BA_ "GenMsgSendType" BO_ 1939 0;
BA_ "GenMsgSendType" BO_ 2015 0;
BA_ "VFrameFormat" BO_ 791 14;
BA_ "VFrameFormat" BO_ 792 14;
BA_ "VFrameFormat" BO_ 793 14;
BA_ "VFrameFormat" BO_ 794 14;
BA_ "VFrameFormat" BO_ 795 14;
BA_ "VFrameFormat" BO_ 796 14;
BA_ "VFrameFormat" BO_ 797 14;
BA_ "VFrameFormat" BO_ 798 14;
BA_ "VFrameFormat" BO_ 799 14;
BA_ "VFrameFormat" BO_ 800 14;
BA_ "VFrameFormat" BO_ 801 14;
BA_ "VFrameFormat" BO_ 802 14;
BA_ "VFrameFormat" BO_ 1147 14;
BA_ "VFrameFormat" BO_ 1148 14;
BA_ "VFrameFormat" BO_ 1298 14;
BA_ "VFrameFormat" BO_ 1312 14;
BA_ "VFrameFormat" BO_ 1810 14;
BA_ "VFrameFormat" BO_ 1811 14;
BA_ "VFrameFormat" BO_ 1938 14;
BA_ "VFrameFormat" BO_ 1939 14;
BA_ "VFrameFormat" BO_ 2015 14;
BA_ "EventCommandSignal" SG_ 791 SGU22_BlockCounter 0;
BA_ "GatewayedSignals" SG_ 791 SGU22_BlockCounter 0;
BA_ "GenSigInactiveValue" SG_ 791 SGU22_BlockCounter 0;
BA_ "GenSigInvalidValue" SG_ 791 SGU22_BlockCounter 0;
BA_ "GenSigSendType" SG_ 791 SGU22_BlockCounter 1;
BA_ "GenSigStartValue" SG_ 791 SGU22_BlockCounter 0;
BA_ "GenSigTimeoutValue" SG_ 791 SGU22_BlockCounter 0;
BA_ "Remark" SG_ 791 SGU22_BlockCounter "";
BA_ "EventCommandSignal" SG_ 791 SGU22_LifeCycles_OBJ 0;
BA_ "GatewayedSignals" SG_ 791 SGU22_LifeCycles_OBJ 0;
BA_ "GenSigInactiveValue" SG_ 791 SGU22_LifeCycles_OBJ 0;
BA_ "GenSigInvalidValue" SG_ 791 SGU22_LifeCycles_OBJ 0;
BA_ "GenSigSendType" SG_ 791 SGU22_LifeCycles_OBJ 1;
BA_ "GenSigStartValue" SG_ 791 SGU22_LifeCycles_OBJ 0;
BA_ "GenSigTimeoutValue" SG_ 791 SGU22_LifeCycles_OBJ 0;
BA_ "Remark" SG_ 791 SGU22_LifeCycles_OBJ "";
BA_ "EventCommandSignal" SG_ 791 SGU22_Msg_AliveCounter 0;
BA_ "GatewayedSignals" SG_ 791 SGU22_Msg_AliveCounter 0;
BA_ "GenSigInactiveValue" SG_ 791 SGU22_Msg_AliveCounter 0;
BA_ "GenSigInvalidValue" SG_ 791 SGU22_Msg_AliveCounter 0;
BA_ "GenSigSendType" SG_ 791 SGU22_Msg_AliveCounter 1;
BA_ "GenSigStartValue" SG_ 791 SGU22_Msg_AliveCounter 0;
BA_ "GenSigTimeoutValue" SG_ 791 SGU22_Msg_AliveCounter 0;
BA_ "Remark" SG_ 791 SGU22_Msg_AliveCounter "";
BA_ "EventCommandSignal" SG_ 791 SGU22_Msg_CheckSum 0;
BA_ "GatewayedSignals" SG_ 791 SGU22_Msg_CheckSum 0;
BA_ "GenSigInactiveValue" SG_ 791 SGU22_Msg_CheckSum 0;
BA_ "GenSigInvalidValue" SG_ 791 SGU22_Msg_CheckSum 0;
BA_ "GenSigSendType" SG_ 791 SGU22_Msg_CheckSum 1;
BA_ "GenSigStartValue" SG_ 791 SGU22_Msg_CheckSum 0;
BA_ "GenSigTimeoutValue" SG_ 791 SGU22_Msg_CheckSum 0;
BA_ "Remark" SG_ 791 SGU22_Msg_CheckSum "";
BA_ "EventCommandSignal" SG_ 791 SGU22_ObjRCS_22 0;
BA_ "GatewayedSignals" SG_ 791 SGU22_ObjRCS_22 0;
BA_ "GenSigInactiveValue" SG_ 791 SGU22_ObjRCS_22 0;
BA_ "GenSigInvalidValue" SG_ 791 SGU22_ObjRCS_22 0;
BA_ "GenSigSendType" SG_ 791 SGU22_ObjRCS_22 1;
BA_ "GenSigStartValue" SG_ 791 SGU22_ObjRCS_22 0;
BA_ "GenSigTimeoutValue" SG_ 791 SGU22_ObjRCS_22 0;
BA_ "Remark" SG_ 791 SGU22_ObjRCS_22 "";
BA_ "EventCommandSignal" SG_ 791 SGU22_Obj_DistLat_rms 0;
BA_ "GatewayedSignals" SG_ 791 SGU22_Obj_DistLat_rms 0;
BA_ "GenSigInactiveValue" SG_ 791 SGU22_Obj_DistLat_rms 0;
BA_ "GenSigInvalidValue" SG_ 791 SGU22_Obj_DistLat_rms 0;
BA_ "GenSigSendType" SG_ 791 SGU22_Obj_DistLat_rms 1;
BA_ "GenSigStartValue" SG_ 791 SGU22_Obj_DistLat_rms 0;
BA_ "GenSigTimeoutValue" SG_ 791 SGU22_Obj_DistLat_rms 0;
BA_ "Remark" SG_ 791 SGU22_Obj_DistLat_rms "";
BA_ "EventCommandSignal" SG_ 791 SGU22_Obj_VrelLong_rms 0;
BA_ "GatewayedSignals" SG_ 791 SGU22_Obj_VrelLong_rms 0;
BA_ "GenSigInactiveValue" SG_ 791 SGU22_Obj_VrelLong_rms 0;
BA_ "GenSigInvalidValue" SG_ 791 SGU22_Obj_VrelLong_rms 0;
BA_ "GenSigSendType" SG_ 791 SGU22_Obj_VrelLong_rms 1;
BA_ "GenSigStartValue" SG_ 791 SGU22_Obj_VrelLong_rms 0;
BA_ "GenSigTimeoutValue" SG_ 791 SGU22_Obj_VrelLong_rms 0;
BA_ "Remark" SG_ 791 SGU22_Obj_VrelLong_rms "";
BA_ "EventCommandSignal" SG_ 791 SGU22_Obj_Vrelat_rms 0;
BA_ "GatewayedSignals" SG_ 791 SGU22_Obj_Vrelat_rms 0;
BA_ "GenSigInactiveValue" SG_ 791 SGU22_Obj_Vrelat_rms 0;
BA_ "GenSigInvalidValue" SG_ 791 SGU22_Obj_Vrelat_rms 0;
BA_ "GenSigSendType" SG_ 791 SGU22_Obj_Vrelat_rms 1;
BA_ "GenSigStartValue" SG_ 791 SGU22_Obj_Vrelat_rms 0;
BA_ "GenSigTimeoutValue" SG_ 791 SGU22_Obj_Vrelat_rms 0;
BA_ "Remark" SG_ 791 SGU22_Obj_Vrelat_rms "";
BA_ "EventCommandSignal" SG_ 791 SGU22_Object_DetStatus 0;
BA_ "GatewayedSignals" SG_ 791 SGU22_Object_DetStatus 0;
BA_ "GenSigInactiveValue" SG_ 791 SGU22_Object_DetStatus 0;
BA_ "GenSigInvalidValue" SG_ 791 SGU22_Object_DetStatus 0;
BA_ "GenSigSendType" SG_ 791 SGU22_Object_DetStatus 1;
BA_ "GenSigStartValue" SG_ 791 SGU22_Object_DetStatus 0;
BA_ "GenSigTimeoutValue" SG_ 791 SGU22_Object_DetStatus 0;
BA_ "Remark" SG_ 791 SGU22_Object_DetStatus "";
BA_ "EventCommandSignal" SG_ 791 SGU22_Object_DistLong_rms 0;
BA_ "GatewayedSignals" SG_ 791 SGU22_Object_DistLong_rms 0;
BA_ "GenSigInactiveValue" SG_ 791 SGU22_Object_DistLong_rms 0;
BA_ "GenSigInvalidValue" SG_ 791 SGU22_Object_DistLong_rms 0;
BA_ "GenSigSendType" SG_ 791 SGU22_Object_DistLong_rms 1;
BA_ "GenSigStartValue" SG_ 791 SGU22_Object_DistLong_rms 0;
BA_ "GenSigTimeoutValue" SG_ 791 SGU22_Object_DistLong_rms 0;
BA_ "Remark" SG_ 791 SGU22_Object_DistLong_rms "";
BA_ "EventCommandSignal" SG_ 791 SGU22_Object_ID 0;
BA_ "GatewayedSignals" SG_ 791 SGU22_Object_ID 0;
BA_ "GenSigInactiveValue" SG_ 791 SGU22_Object_ID 0;
BA_ "GenSigInvalidValue" SG_ 791 SGU22_Object_ID 0;
BA_ "GenSigSendType" SG_ 791 SGU22_Object_ID 1;
BA_ "GenSigStartValue" SG_ 791 SGU22_Object_ID 0;
BA_ "GenSigTimeoutValue" SG_ 791 SGU22_Object_ID 0;
BA_ "Remark" SG_ 791 SGU22_Object_ID "";
BA_ "EventCommandSignal" SG_ 791 SGU22_Object_Motion_Pattern 0;
BA_ "GatewayedSignals" SG_ 791 SGU22_Object_Motion_Pattern 0;
BA_ "GenSigInactiveValue" SG_ 791 SGU22_Object_Motion_Pattern 0;
BA_ "GenSigInvalidValue" SG_ 791 SGU22_Object_Motion_Pattern 0;
BA_ "GenSigSendType" SG_ 791 SGU22_Object_Motion_Pattern 1;
BA_ "GenSigStartValue" SG_ 791 SGU22_Object_Motion_Pattern 0;
BA_ "GenSigTimeoutValue" SG_ 791 SGU22_Object_Motion_Pattern 0;
BA_ "Remark" SG_ 791 SGU22_Object_Motion_Pattern "";
BA_ "EventCommandSignal" SG_ 791 SGU22_Object_Type 0;
BA_ "GatewayedSignals" SG_ 791 SGU22_Object_Type 0;
BA_ "GenSigInactiveValue" SG_ 791 SGU22_Object_Type 0;
BA_ "GenSigInvalidValue" SG_ 791 SGU22_Object_Type 0;
BA_ "GenSigSendType" SG_ 791 SGU22_Object_Type 1;
BA_ "GenSigStartValue" SG_ 791 SGU22_Object_Type 0;
BA_ "GenSigTimeoutValue" SG_ 791 SGU22_Object_Type 0;
BA_ "Remark" SG_ 791 SGU22_Object_Type "";
BA_ "EventCommandSignal" SG_ 791 SGU22_Object_ax 0;
BA_ "GatewayedSignals" SG_ 791 SGU22_Object_ax 0;
BA_ "GenSigInactiveValue" SG_ 791 SGU22_Object_ax 0;
BA_ "GenSigInvalidValue" SG_ 791 SGU22_Object_ax 0;
BA_ "GenSigSendType" SG_ 791 SGU22_Object_ax 1;
BA_ "GenSigStartValue" SG_ 791 SGU22_Object_ax 0;
BA_ "GenSigTimeoutValue" SG_ 791 SGU22_Object_ax 0;
BA_ "Remark" SG_ 791 SGU22_Object_ax "";
BA_ "EventCommandSignal" SG_ 791 SGU22_Object_ay 0;
BA_ "GatewayedSignals" SG_ 791 SGU22_Object_ay 0;
BA_ "GenSigInactiveValue" SG_ 791 SGU22_Object_ay 0;
BA_ "GenSigInvalidValue" SG_ 791 SGU22_Object_ay 0;
BA_ "GenSigSendType" SG_ 791 SGU22_Object_ay 1;
BA_ "GenSigStartValue" SG_ 791 SGU22_Object_ay 0;
BA_ "GenSigTimeoutValue" SG_ 791 SGU22_Object_ay 0;
BA_ "Remark" SG_ 791 SGU22_Object_ay "";
BA_ "EventCommandSignal" SG_ 791 SGU22_Object_dx 0;
BA_ "GatewayedSignals" SG_ 791 SGU22_Object_dx 0;
BA_ "GenSigInactiveValue" SG_ 791 SGU22_Object_dx 0;
BA_ "GenSigInvalidValue" SG_ 791 SGU22_Object_dx 0;
BA_ "GenSigSendType" SG_ 791 SGU22_Object_dx 1;
BA_ "GenSigStartValue" SG_ 791 SGU22_Object_dx 0;
BA_ "GenSigTimeoutValue" SG_ 791 SGU22_Object_dx 0;
BA_ "Remark" SG_ 791 SGU22_Object_dx "";
BA_ "EventCommandSignal" SG_ 791 SGU22_Object_dx_Rear 0;
BA_ "GatewayedSignals" SG_ 791 SGU22_Object_dx_Rear 0;
BA_ "GenSigInactiveValue" SG_ 791 SGU22_Object_dx_Rear 0;
BA_ "GenSigInvalidValue" SG_ 791 SGU22_Object_dx_Rear 0;
BA_ "GenSigSendType" SG_ 791 SGU22_Object_dx_Rear 1;
BA_ "GenSigStartValue" SG_ 791 SGU22_Object_dx_Rear 0;
BA_ "GenSigTimeoutValue" SG_ 791 SGU22_Object_dx_Rear 0;
BA_ "Remark" SG_ 791 SGU22_Object_dx_Rear "";
BA_ "EventCommandSignal" SG_ 791 SGU22_Object_dy 0;
BA_ "GatewayedSignals" SG_ 791 SGU22_Object_dy 0;
BA_ "GenSigInactiveValue" SG_ 791 SGU22_Object_dy 0;
BA_ "GenSigInvalidValue" SG_ 791 SGU22_Object_dy 0;
BA_ "GenSigSendType" SG_ 791 SGU22_Object_dy 1;
BA_ "GenSigStartValue" SG_ 791 SGU22_Object_dy 0;
BA_ "GenSigTimeoutValue" SG_ 791 SGU22_Object_dy 0;
BA_ "Remark" SG_ 791 SGU22_Object_dy "";
BA_ "EventCommandSignal" SG_ 791 SGU22_Object_dy_Rear 0;
BA_ "GatewayedSignals" SG_ 791 SGU22_Object_dy_Rear 0;
BA_ "GenSigInactiveValue" SG_ 791 SGU22_Object_dy_Rear 0;
BA_ "GenSigInvalidValue" SG_ 791 SGU22_Object_dy_Rear 0;
BA_ "GenSigSendType" SG_ 791 SGU22_Object_dy_Rear 1;
BA_ "GenSigStartValue" SG_ 791 SGU22_Object_dy_Rear 0;
BA_ "GenSigTimeoutValue" SG_ 791 SGU22_Object_dy_Rear 0;
BA_ "Remark" SG_ 791 SGU22_Object_dy_Rear "";
BA_ "EventCommandSignal" SG_ 791 SGU22_Object_vx 0;
BA_ "GatewayedSignals" SG_ 791 SGU22_Object_vx 0;
BA_ "GenSigInactiveValue" SG_ 791 SGU22_Object_vx 0;
BA_ "GenSigInvalidValue" SG_ 791 SGU22_Object_vx 0;
BA_ "GenSigSendType" SG_ 791 SGU22_Object_vx 1;
BA_ "GenSigStartValue" SG_ 791 SGU22_Object_vx 0;
BA_ "GenSigTimeoutValue" SG_ 791 SGU22_Object_vx 0;
BA_ "Remark" SG_ 791 SGU22_Object_vx "";
BA_ "EventCommandSignal" SG_ 791 SGU22_Object_vy 0;
BA_ "GatewayedSignals" SG_ 791 SGU22_Object_vy 0;
BA_ "GenSigInactiveValue" SG_ 791 SGU22_Object_vy 0;
BA_ "GenSigInvalidValue" SG_ 791 SGU22_Object_vy 0;
BA_ "GenSigSendType" SG_ 791 SGU22_Object_vy 1;
BA_ "GenSigStartValue" SG_ 791 SGU22_Object_vy 0;
BA_ "GenSigTimeoutValue" SG_ 791 SGU22_Object_vy 0;
BA_ "Remark" SG_ 791 SGU22_Object_vy "";
BA_ "EventCommandSignal" SG_ 791 SGU22_Object_wExist 0;
BA_ "GatewayedSignals" SG_ 791 SGU22_Object_wExist 0;
BA_ "GenSigInactiveValue" SG_ 791 SGU22_Object_wExist 0;
BA_ "GenSigInvalidValue" SG_ 791 SGU22_Object_wExist 0;
BA_ "GenSigSendType" SG_ 791 SGU22_Object_wExist 1;
BA_ "GenSigStartValue" SG_ 791 SGU22_Object_wExist 0;
BA_ "GenSigTimeoutValue" SG_ 791 SGU22_Object_wExist 0;
BA_ "Remark" SG_ 791 SGU22_Object_wExist "";
BA_ "EventCommandSignal" SG_ 791 SGU22_Object_wObstacle 0;
BA_ "GatewayedSignals" SG_ 791 SGU22_Object_wObstacle 0;
BA_ "GenSigInactiveValue" SG_ 791 SGU22_Object_wObstacle 0;
BA_ "GenSigInvalidValue" SG_ 791 SGU22_Object_wObstacle 0;
BA_ "GenSigSendType" SG_ 791 SGU22_Object_wObstacle 1;
BA_ "GenSigStartValue" SG_ 791 SGU22_Object_wObstacle 0;
BA_ "GenSigTimeoutValue" SG_ 791 SGU22_Object_wObstacle 0;
BA_ "Remark" SG_ 791 SGU22_Object_wObstacle "";
BA_ "EventCommandSignal" SG_ 792 SGU23_BlockCounter 0;
BA_ "GatewayedSignals" SG_ 792 SGU23_BlockCounter 0;
BA_ "GenSigInactiveValue" SG_ 792 SGU23_BlockCounter 0;
BA_ "GenSigInvalidValue" SG_ 792 SGU23_BlockCounter 0;
BA_ "GenSigSendType" SG_ 792 SGU23_BlockCounter 1;
BA_ "GenSigStartValue" SG_ 792 SGU23_BlockCounter 0;
BA_ "GenSigTimeoutValue" SG_ 792 SGU23_BlockCounter 0;
BA_ "Remark" SG_ 792 SGU23_BlockCounter "";
BA_ "EventCommandSignal" SG_ 792 SGU23_LifeCycles_OBJ 0;
BA_ "GatewayedSignals" SG_ 792 SGU23_LifeCycles_OBJ 0;
BA_ "GenSigInactiveValue" SG_ 792 SGU23_LifeCycles_OBJ 0;
BA_ "GenSigInvalidValue" SG_ 792 SGU23_LifeCycles_OBJ 0;
BA_ "GenSigSendType" SG_ 792 SGU23_LifeCycles_OBJ 1;
BA_ "GenSigStartValue" SG_ 792 SGU23_LifeCycles_OBJ 0;
BA_ "GenSigTimeoutValue" SG_ 792 SGU23_LifeCycles_OBJ 0;
BA_ "Remark" SG_ 792 SGU23_LifeCycles_OBJ "";
BA_ "EventCommandSignal" SG_ 792 SGU23_Msg_AliveCounter 0;
BA_ "GatewayedSignals" SG_ 792 SGU23_Msg_AliveCounter 0;
BA_ "GenSigInactiveValue" SG_ 792 SGU23_Msg_AliveCounter 0;
BA_ "GenSigInvalidValue" SG_ 792 SGU23_Msg_AliveCounter 0;
BA_ "GenSigSendType" SG_ 792 SGU23_Msg_AliveCounter 1;
BA_ "GenSigStartValue" SG_ 792 SGU23_Msg_AliveCounter 0;
BA_ "GenSigTimeoutValue" SG_ 792 SGU23_Msg_AliveCounter 0;
BA_ "Remark" SG_ 792 SGU23_Msg_AliveCounter "";
BA_ "EventCommandSignal" SG_ 792 SGU23_Msg_CheckSum 0;
BA_ "GatewayedSignals" SG_ 792 SGU23_Msg_CheckSum 0;
BA_ "GenSigInactiveValue" SG_ 792 SGU23_Msg_CheckSum 0;
BA_ "GenSigInvalidValue" SG_ 792 SGU23_Msg_CheckSum 0;
BA_ "GenSigSendType" SG_ 792 SGU23_Msg_CheckSum 1;
BA_ "GenSigStartValue" SG_ 792 SGU23_Msg_CheckSum 0;
BA_ "GenSigTimeoutValue" SG_ 792 SGU23_Msg_CheckSum 0;
BA_ "Remark" SG_ 792 SGU23_Msg_CheckSum "";
BA_ "EventCommandSignal" SG_ 792 SGU23_ObjRCS_23 0;
BA_ "GatewayedSignals" SG_ 792 SGU23_ObjRCS_23 0;
BA_ "GenSigInactiveValue" SG_ 792 SGU23_ObjRCS_23 0;
BA_ "GenSigInvalidValue" SG_ 792 SGU23_ObjRCS_23 0;
BA_ "GenSigSendType" SG_ 792 SGU23_ObjRCS_23 1;
BA_ "GenSigStartValue" SG_ 792 SGU23_ObjRCS_23 0;
BA_ "GenSigTimeoutValue" SG_ 792 SGU23_ObjRCS_23 0;
BA_ "Remark" SG_ 792 SGU23_ObjRCS_23 "";
BA_ "EventCommandSignal" SG_ 792 SGU23_Obj_DistLat_rms 0;
BA_ "GatewayedSignals" SG_ 792 SGU23_Obj_DistLat_rms 0;
BA_ "GenSigInactiveValue" SG_ 792 SGU23_Obj_DistLat_rms 0;
BA_ "GenSigInvalidValue" SG_ 792 SGU23_Obj_DistLat_rms 0;
BA_ "GenSigSendType" SG_ 792 SGU23_Obj_DistLat_rms 1;
BA_ "GenSigStartValue" SG_ 792 SGU23_Obj_DistLat_rms 0;
BA_ "GenSigTimeoutValue" SG_ 792 SGU23_Obj_DistLat_rms 0;
BA_ "Remark" SG_ 792 SGU23_Obj_DistLat_rms "";
BA_ "EventCommandSignal" SG_ 792 SGU23_Obj_VrelLong_rms 0;
BA_ "GatewayedSignals" SG_ 792 SGU23_Obj_VrelLong_rms 0;
BA_ "GenSigInactiveValue" SG_ 792 SGU23_Obj_VrelLong_rms 0;
BA_ "GenSigInvalidValue" SG_ 792 SGU23_Obj_VrelLong_rms 0;
BA_ "GenSigSendType" SG_ 792 SGU23_Obj_VrelLong_rms 1;
BA_ "GenSigStartValue" SG_ 792 SGU23_Obj_VrelLong_rms 0;
BA_ "GenSigTimeoutValue" SG_ 792 SGU23_Obj_VrelLong_rms 0;
BA_ "Remark" SG_ 792 SGU23_Obj_VrelLong_rms "";
BA_ "EventCommandSignal" SG_ 792 SGU23_Obj_Vrelat_rms 0;
BA_ "GatewayedSignals" SG_ 792 SGU23_Obj_Vrelat_rms 0;
BA_ "GenSigInactiveValue" SG_ 792 SGU23_Obj_Vrelat_rms 0;
BA_ "GenSigInvalidValue" SG_ 792 SGU23_Obj_Vrelat_rms 0;
BA_ "GenSigSendType" SG_ 792 SGU23_Obj_Vrelat_rms 1;
BA_ "GenSigStartValue" SG_ 792 SGU23_Obj_Vrelat_rms 0;
BA_ "GenSigTimeoutValue" SG_ 792 SGU23_Obj_Vrelat_rms 0;
BA_ "Remark" SG_ 792 SGU23_Obj_Vrelat_rms "";
BA_ "EventCommandSignal" SG_ 792 SGU23_Object_DetStatus 0;
BA_ "GatewayedSignals" SG_ 792 SGU23_Object_DetStatus 0;
BA_ "GenSigInactiveValue" SG_ 792 SGU23_Object_DetStatus 0;
BA_ "GenSigInvalidValue" SG_ 792 SGU23_Object_DetStatus 0;
BA_ "GenSigSendType" SG_ 792 SGU23_Object_DetStatus 1;
BA_ "GenSigStartValue" SG_ 792 SGU23_Object_DetStatus 0;
BA_ "GenSigTimeoutValue" SG_ 792 SGU23_Object_DetStatus 0;
BA_ "Remark" SG_ 792 SGU23_Object_DetStatus "";
BA_ "EventCommandSignal" SG_ 792 SGU23_Object_DistLong_rms 0;
BA_ "GatewayedSignals" SG_ 792 SGU23_Object_DistLong_rms 0;
BA_ "GenSigInactiveValue" SG_ 792 SGU23_Object_DistLong_rms 0;
BA_ "GenSigInvalidValue" SG_ 792 SGU23_Object_DistLong_rms 0;
BA_ "GenSigSendType" SG_ 792 SGU23_Object_DistLong_rms 1;
BA_ "GenSigStartValue" SG_ 792 SGU23_Object_DistLong_rms 0;
BA_ "GenSigTimeoutValue" SG_ 792 SGU23_Object_DistLong_rms 0;
BA_ "Remark" SG_ 792 SGU23_Object_DistLong_rms "";
BA_ "EventCommandSignal" SG_ 792 SGU23_Object_ID 0;
BA_ "GatewayedSignals" SG_ 792 SGU23_Object_ID 0;
BA_ "GenSigInactiveValue" SG_ 792 SGU23_Object_ID 0;
BA_ "GenSigInvalidValue" SG_ 792 SGU23_Object_ID 0;
BA_ "GenSigSendType" SG_ 792 SGU23_Object_ID 1;
BA_ "GenSigStartValue" SG_ 792 SGU23_Object_ID 0;
BA_ "GenSigTimeoutValue" SG_ 792 SGU23_Object_ID 0;
BA_ "Remark" SG_ 792 SGU23_Object_ID "";
BA_ "EventCommandSignal" SG_ 792 SGU23_Object_Motion_Pattern 0;
BA_ "GatewayedSignals" SG_ 792 SGU23_Object_Motion_Pattern 0;
BA_ "GenSigInactiveValue" SG_ 792 SGU23_Object_Motion_Pattern 0;
BA_ "GenSigInvalidValue" SG_ 792 SGU23_Object_Motion_Pattern 0;
BA_ "GenSigSendType" SG_ 792 SGU23_Object_Motion_Pattern 1;
BA_ "GenSigStartValue" SG_ 792 SGU23_Object_Motion_Pattern 0;
BA_ "GenSigTimeoutValue" SG_ 792 SGU23_Object_Motion_Pattern 0;
BA_ "Remark" SG_ 792 SGU23_Object_Motion_Pattern "";
BA_ "EventCommandSignal" SG_ 792 SGU23_Object_Type 0;
BA_ "GatewayedSignals" SG_ 792 SGU23_Object_Type 0;
BA_ "GenSigInactiveValue" SG_ 792 SGU23_Object_Type 0;
BA_ "GenSigInvalidValue" SG_ 792 SGU23_Object_Type 0;
BA_ "GenSigSendType" SG_ 792 SGU23_Object_Type 1;
BA_ "GenSigStartValue" SG_ 792 SGU23_Object_Type 0;
BA_ "GenSigTimeoutValue" SG_ 792 SGU23_Object_Type 0;
BA_ "Remark" SG_ 792 SGU23_Object_Type "";
BA_ "EventCommandSignal" SG_ 792 SGU23_Object_ax 0;
BA_ "GatewayedSignals" SG_ 792 SGU23_Object_ax 0;
BA_ "GenSigInactiveValue" SG_ 792 SGU23_Object_ax 0;
BA_ "GenSigInvalidValue" SG_ 792 SGU23_Object_ax 0;
BA_ "GenSigSendType" SG_ 792 SGU23_Object_ax 1;
BA_ "GenSigStartValue" SG_ 792 SGU23_Object_ax 0;
BA_ "GenSigTimeoutValue" SG_ 792 SGU23_Object_ax 0;
BA_ "Remark" SG_ 792 SGU23_Object_ax "";
BA_ "EventCommandSignal" SG_ 792 SGU23_Object_ay 0;
BA_ "GatewayedSignals" SG_ 792 SGU23_Object_ay 0;
BA_ "GenSigInactiveValue" SG_ 792 SGU23_Object_ay 0;
BA_ "GenSigInvalidValue" SG_ 792 SGU23_Object_ay 0;
BA_ "GenSigSendType" SG_ 792 SGU23_Object_ay 1;
BA_ "GenSigStartValue" SG_ 792 SGU23_Object_ay 0;
BA_ "GenSigTimeoutValue" SG_ 792 SGU23_Object_ay 0;
BA_ "Remark" SG_ 792 SGU23_Object_ay "";
BA_ "EventCommandSignal" SG_ 792 SGU23_Object_dx 0;
BA_ "GatewayedSignals" SG_ 792 SGU23_Object_dx 0;
BA_ "GenSigInactiveValue" SG_ 792 SGU23_Object_dx 0;
BA_ "GenSigInvalidValue" SG_ 792 SGU23_Object_dx 0;
BA_ "GenSigSendType" SG_ 792 SGU23_Object_dx 1;
BA_ "GenSigStartValue" SG_ 792 SGU23_Object_dx 0;
BA_ "GenSigTimeoutValue" SG_ 792 SGU23_Object_dx 0;
BA_ "Remark" SG_ 792 SGU23_Object_dx "";
BA_ "EventCommandSignal" SG_ 792 SGU23_Object_dx_Rear 0;
BA_ "GatewayedSignals" SG_ 792 SGU23_Object_dx_Rear 0;
BA_ "GenSigInactiveValue" SG_ 792 SGU23_Object_dx_Rear 0;
BA_ "GenSigInvalidValue" SG_ 792 SGU23_Object_dx_Rear 0;
BA_ "GenSigSendType" SG_ 792 SGU23_Object_dx_Rear 1;
BA_ "GenSigStartValue" SG_ 792 SGU23_Object_dx_Rear 0;
BA_ "GenSigTimeoutValue" SG_ 792 SGU23_Object_dx_Rear 0;
BA_ "Remark" SG_ 792 SGU23_Object_dx_Rear "";
BA_ "EventCommandSignal" SG_ 792 SGU23_Object_dy 0;
BA_ "GatewayedSignals" SG_ 792 SGU23_Object_dy 0;
BA_ "GenSigInactiveValue" SG_ 792 SGU23_Object_dy 0;
BA_ "GenSigInvalidValue" SG_ 792 SGU23_Object_dy 0;
BA_ "GenSigSendType" SG_ 792 SGU23_Object_dy 1;
BA_ "GenSigStartValue" SG_ 792 SGU23_Object_dy 0;
BA_ "GenSigTimeoutValue" SG_ 792 SGU23_Object_dy 0;
BA_ "Remark" SG_ 792 SGU23_Object_dy "";
BA_ "EventCommandSignal" SG_ 792 SGU23_Object_dy_Rear 0;
BA_ "GatewayedSignals" SG_ 792 SGU23_Object_dy_Rear 0;
BA_ "GenSigInactiveValue" SG_ 792 SGU23_Object_dy_Rear 0;
BA_ "GenSigInvalidValue" SG_ 792 SGU23_Object_dy_Rear 0;
BA_ "GenSigSendType" SG_ 792 SGU23_Object_dy_Rear 1;
BA_ "GenSigStartValue" SG_ 792 SGU23_Object_dy_Rear 0;
BA_ "GenSigTimeoutValue" SG_ 792 SGU23_Object_dy_Rear 0;
BA_ "Remark" SG_ 792 SGU23_Object_dy_Rear "";
BA_ "EventCommandSignal" SG_ 792 SGU23_Object_vx 0;
BA_ "GatewayedSignals" SG_ 792 SGU23_Object_vx 0;
BA_ "GenSigInactiveValue" SG_ 792 SGU23_Object_vx 0;
BA_ "GenSigInvalidValue" SG_ 792 SGU23_Object_vx 0;
BA_ "GenSigSendType" SG_ 792 SGU23_Object_vx 1;
BA_ "GenSigStartValue" SG_ 792 SGU23_Object_vx 0;
BA_ "GenSigTimeoutValue" SG_ 792 SGU23_Object_vx 0;
BA_ "Remark" SG_ 792 SGU23_Object_vx "";
BA_ "EventCommandSignal" SG_ 792 SGU23_Object_vy 0;
BA_ "GatewayedSignals" SG_ 792 SGU23_Object_vy 0;
BA_ "GenSigInactiveValue" SG_ 792 SGU23_Object_vy 0;
BA_ "GenSigInvalidValue" SG_ 792 SGU23_Object_vy 0;
BA_ "GenSigSendType" SG_ 792 SGU23_Object_vy 1;
BA_ "GenSigStartValue" SG_ 792 SGU23_Object_vy 0;
BA_ "GenSigTimeoutValue" SG_ 792 SGU23_Object_vy 0;
BA_ "Remark" SG_ 792 SGU23_Object_vy "";
BA_ "EventCommandSignal" SG_ 792 SGU23_Object_wExist 0;
BA_ "GatewayedSignals" SG_ 792 SGU23_Object_wExist 0;
BA_ "GenSigInactiveValue" SG_ 792 SGU23_Object_wExist 0;
BA_ "GenSigInvalidValue" SG_ 792 SGU23_Object_wExist 0;
BA_ "GenSigSendType" SG_ 792 SGU23_Object_wExist 1;
BA_ "GenSigStartValue" SG_ 792 SGU23_Object_wExist 0;
BA_ "GenSigTimeoutValue" SG_ 792 SGU23_Object_wExist 0;
BA_ "Remark" SG_ 792 SGU23_Object_wExist "";
BA_ "EventCommandSignal" SG_ 792 SGU23_Object_wObstacle 0;
BA_ "GatewayedSignals" SG_ 792 SGU23_Object_wObstacle 0;
BA_ "GenSigInactiveValue" SG_ 792 SGU23_Object_wObstacle 0;
BA_ "GenSigInvalidValue" SG_ 792 SGU23_Object_wObstacle 0;
BA_ "GenSigSendType" SG_ 792 SGU23_Object_wObstacle 1;
BA_ "GenSigStartValue" SG_ 792 SGU23_Object_wObstacle 0;
BA_ "GenSigTimeoutValue" SG_ 792 SGU23_Object_wObstacle 0;
BA_ "Remark" SG_ 792 SGU23_Object_wObstacle "";
BA_ "EventCommandSignal" SG_ 793 SGU24_BlockCounter 0;
BA_ "GatewayedSignals" SG_ 793 SGU24_BlockCounter 0;
BA_ "GenSigInactiveValue" SG_ 793 SGU24_BlockCounter 0;
BA_ "GenSigInvalidValue" SG_ 793 SGU24_BlockCounter 0;
BA_ "GenSigSendType" SG_ 793 SGU24_BlockCounter 1;
BA_ "GenSigStartValue" SG_ 793 SGU24_BlockCounter 0;
BA_ "GenSigTimeoutValue" SG_ 793 SGU24_BlockCounter 0;
BA_ "Remark" SG_ 793 SGU24_BlockCounter "";
BA_ "EventCommandSignal" SG_ 793 SGU24_LifeCycles_OBJ 0;
BA_ "GatewayedSignals" SG_ 793 SGU24_LifeCycles_OBJ 0;
BA_ "GenSigInactiveValue" SG_ 793 SGU24_LifeCycles_OBJ 0;
BA_ "GenSigInvalidValue" SG_ 793 SGU24_LifeCycles_OBJ 0;
BA_ "GenSigSendType" SG_ 793 SGU24_LifeCycles_OBJ 1;
BA_ "GenSigStartValue" SG_ 793 SGU24_LifeCycles_OBJ 0;
BA_ "GenSigTimeoutValue" SG_ 793 SGU24_LifeCycles_OBJ 0;
BA_ "Remark" SG_ 793 SGU24_LifeCycles_OBJ "";
BA_ "EventCommandSignal" SG_ 793 SGU24_Msg_AliveCounter 0;
BA_ "GatewayedSignals" SG_ 793 SGU24_Msg_AliveCounter 0;
BA_ "GenSigInactiveValue" SG_ 793 SGU24_Msg_AliveCounter 0;
BA_ "GenSigInvalidValue" SG_ 793 SGU24_Msg_AliveCounter 0;
BA_ "GenSigSendType" SG_ 793 SGU24_Msg_AliveCounter 1;
BA_ "GenSigStartValue" SG_ 793 SGU24_Msg_AliveCounter 0;
BA_ "GenSigTimeoutValue" SG_ 793 SGU24_Msg_AliveCounter 0;
BA_ "Remark" SG_ 793 SGU24_Msg_AliveCounter "";
BA_ "EventCommandSignal" SG_ 793 SGU24_Msg_CheckSum 0;
BA_ "GatewayedSignals" SG_ 793 SGU24_Msg_CheckSum 0;
BA_ "GenSigInactiveValue" SG_ 793 SGU24_Msg_CheckSum 0;
BA_ "GenSigInvalidValue" SG_ 793 SGU24_Msg_CheckSum 0;
BA_ "GenSigSendType" SG_ 793 SGU24_Msg_CheckSum 1;
BA_ "GenSigStartValue" SG_ 793 SGU24_Msg_CheckSum 0;
BA_ "GenSigTimeoutValue" SG_ 793 SGU24_Msg_CheckSum 0;
BA_ "Remark" SG_ 793 SGU24_Msg_CheckSum "";
BA_ "EventCommandSignal" SG_ 793 SGU24_ObjRCS_24 0;
BA_ "GatewayedSignals" SG_ 793 SGU24_ObjRCS_24 0;
BA_ "GenSigInactiveValue" SG_ 793 SGU24_ObjRCS_24 0;
BA_ "GenSigInvalidValue" SG_ 793 SGU24_ObjRCS_24 0;
BA_ "GenSigSendType" SG_ 793 SGU24_ObjRCS_24 1;
BA_ "GenSigStartValue" SG_ 793 SGU24_ObjRCS_24 0;
BA_ "GenSigTimeoutValue" SG_ 793 SGU24_ObjRCS_24 0;
BA_ "Remark" SG_ 793 SGU24_ObjRCS_24 "";
BA_ "EventCommandSignal" SG_ 793 SGU24_Obj_DistLat_rms 0;
BA_ "GatewayedSignals" SG_ 793 SGU24_Obj_DistLat_rms 0;
BA_ "GenSigInactiveValue" SG_ 793 SGU24_Obj_DistLat_rms 0;
BA_ "GenSigInvalidValue" SG_ 793 SGU24_Obj_DistLat_rms 0;
BA_ "GenSigSendType" SG_ 793 SGU24_Obj_DistLat_rms 1;
BA_ "GenSigStartValue" SG_ 793 SGU24_Obj_DistLat_rms 0;
BA_ "GenSigTimeoutValue" SG_ 793 SGU24_Obj_DistLat_rms 0;
BA_ "Remark" SG_ 793 SGU24_Obj_DistLat_rms "";
BA_ "EventCommandSignal" SG_ 793 SGU24_Obj_VrelLong_rms 0;
BA_ "GatewayedSignals" SG_ 793 SGU24_Obj_VrelLong_rms 0;
BA_ "GenSigInactiveValue" SG_ 793 SGU24_Obj_VrelLong_rms 0;
BA_ "GenSigInvalidValue" SG_ 793 SGU24_Obj_VrelLong_rms 0;
BA_ "GenSigSendType" SG_ 793 SGU24_Obj_VrelLong_rms 1;
BA_ "GenSigStartValue" SG_ 793 SGU24_Obj_VrelLong_rms 0;
BA_ "GenSigTimeoutValue" SG_ 793 SGU24_Obj_VrelLong_rms 0;
BA_ "Remark" SG_ 793 SGU24_Obj_VrelLong_rms "";
BA_ "EventCommandSignal" SG_ 793 SGU24_Obj_Vrelat_rms 0;
BA_ "GatewayedSignals" SG_ 793 SGU24_Obj_Vrelat_rms 0;
BA_ "GenSigInactiveValue" SG_ 793 SGU24_Obj_Vrelat_rms 0;
BA_ "GenSigInvalidValue" SG_ 793 SGU24_Obj_Vrelat_rms 0;
BA_ "GenSigSendType" SG_ 793 SGU24_Obj_Vrelat_rms 1;
BA_ "GenSigStartValue" SG_ 793 SGU24_Obj_Vrelat_rms 0;
BA_ "GenSigTimeoutValue" SG_ 793 SGU24_Obj_Vrelat_rms 0;
BA_ "Remark" SG_ 793 SGU24_Obj_Vrelat_rms "";
BA_ "EventCommandSignal" SG_ 793 SGU24_Object_DetStatus 0;
BA_ "GatewayedSignals" SG_ 793 SGU24_Object_DetStatus 0;
BA_ "GenSigInactiveValue" SG_ 793 SGU24_Object_DetStatus 0;
BA_ "GenSigInvalidValue" SG_ 793 SGU24_Object_DetStatus 0;
BA_ "GenSigSendType" SG_ 793 SGU24_Object_DetStatus 1;
BA_ "GenSigStartValue" SG_ 793 SGU24_Object_DetStatus 0;
BA_ "GenSigTimeoutValue" SG_ 793 SGU24_Object_DetStatus 0;
BA_ "Remark" SG_ 793 SGU24_Object_DetStatus "";
BA_ "EventCommandSignal" SG_ 793 SGU24_Object_DistLong_rms 0;
BA_ "GatewayedSignals" SG_ 793 SGU24_Object_DistLong_rms 0;
BA_ "GenSigInactiveValue" SG_ 793 SGU24_Object_DistLong_rms 0;
BA_ "GenSigInvalidValue" SG_ 793 SGU24_Object_DistLong_rms 0;
BA_ "GenSigSendType" SG_ 793 SGU24_Object_DistLong_rms 1;
BA_ "GenSigStartValue" SG_ 793 SGU24_Object_DistLong_rms 0;
BA_ "GenSigTimeoutValue" SG_ 793 SGU24_Object_DistLong_rms 0;
BA_ "Remark" SG_ 793 SGU24_Object_DistLong_rms "";
BA_ "EventCommandSignal" SG_ 793 SGU24_Object_ID 0;
BA_ "GatewayedSignals" SG_ 793 SGU24_Object_ID 0;
BA_ "GenSigInactiveValue" SG_ 793 SGU24_Object_ID 0;
BA_ "GenSigInvalidValue" SG_ 793 SGU24_Object_ID 0;
BA_ "GenSigSendType" SG_ 793 SGU24_Object_ID 1;
BA_ "GenSigStartValue" SG_ 793 SGU24_Object_ID 0;
BA_ "GenSigTimeoutValue" SG_ 793 SGU24_Object_ID 0;
BA_ "Remark" SG_ 793 SGU24_Object_ID "";
BA_ "EventCommandSignal" SG_ 793 SGU24_Object_Motion_Pattern 0;
BA_ "GatewayedSignals" SG_ 793 SGU24_Object_Motion_Pattern 0;
BA_ "GenSigInactiveValue" SG_ 793 SGU24_Object_Motion_Pattern 0;
BA_ "GenSigInvalidValue" SG_ 793 SGU24_Object_Motion_Pattern 0;
BA_ "GenSigSendType" SG_ 793 SGU24_Object_Motion_Pattern 1;
BA_ "GenSigStartValue" SG_ 793 SGU24_Object_Motion_Pattern 0;
BA_ "GenSigTimeoutValue" SG_ 793 SGU24_Object_Motion_Pattern 0;
BA_ "Remark" SG_ 793 SGU24_Object_Motion_Pattern "";
BA_ "EventCommandSignal" SG_ 793 SGU24_Object_Type 0;
BA_ "GatewayedSignals" SG_ 793 SGU24_Object_Type 0;
BA_ "GenSigInactiveValue" SG_ 793 SGU24_Object_Type 0;
BA_ "GenSigInvalidValue" SG_ 793 SGU24_Object_Type 0;
BA_ "GenSigSendType" SG_ 793 SGU24_Object_Type 1;
BA_ "GenSigStartValue" SG_ 793 SGU24_Object_Type 0;
BA_ "GenSigTimeoutValue" SG_ 793 SGU24_Object_Type 0;
BA_ "Remark" SG_ 793 SGU24_Object_Type "";
BA_ "EventCommandSignal" SG_ 793 SGU24_Object_ax 0;
BA_ "GatewayedSignals" SG_ 793 SGU24_Object_ax 0;
BA_ "GenSigInactiveValue" SG_ 793 SGU24_Object_ax 0;
BA_ "GenSigInvalidValue" SG_ 793 SGU24_Object_ax 0;
BA_ "GenSigSendType" SG_ 793 SGU24_Object_ax 1;
BA_ "GenSigStartValue" SG_ 793 SGU24_Object_ax 0;
BA_ "GenSigTimeoutValue" SG_ 793 SGU24_Object_ax 0;
BA_ "Remark" SG_ 793 SGU24_Object_ax "";
BA_ "EventCommandSignal" SG_ 793 SGU24_Object_ay 0;
BA_ "GatewayedSignals" SG_ 793 SGU24_Object_ay 0;
BA_ "GenSigInactiveValue" SG_ 793 SGU24_Object_ay 0;
BA_ "GenSigInvalidValue" SG_ 793 SGU24_Object_ay 0;
BA_ "GenSigSendType" SG_ 793 SGU24_Object_ay 1;
BA_ "GenSigStartValue" SG_ 793 SGU24_Object_ay 0;
BA_ "GenSigTimeoutValue" SG_ 793 SGU24_Object_ay 0;
BA_ "Remark" SG_ 793 SGU24_Object_ay "";
BA_ "EventCommandSignal" SG_ 793 SGU24_Object_dx 0;
BA_ "GatewayedSignals" SG_ 793 SGU24_Object_dx 0;
BA_ "GenSigInactiveValue" SG_ 793 SGU24_Object_dx 0;
BA_ "GenSigInvalidValue" SG_ 793 SGU24_Object_dx 0;
BA_ "GenSigSendType" SG_ 793 SGU24_Object_dx 1;
BA_ "GenSigStartValue" SG_ 793 SGU24_Object_dx 0;
BA_ "GenSigTimeoutValue" SG_ 793 SGU24_Object_dx 0;
BA_ "Remark" SG_ 793 SGU24_Object_dx "";
BA_ "EventCommandSignal" SG_ 793 SGU24_Object_dx_Rear 0;
BA_ "GatewayedSignals" SG_ 793 SGU24_Object_dx_Rear 0;
BA_ "GenSigInactiveValue" SG_ 793 SGU24_Object_dx_Rear 0;
BA_ "GenSigInvalidValue" SG_ 793 SGU24_Object_dx_Rear 0;
BA_ "GenSigSendType" SG_ 793 SGU24_Object_dx_Rear 1;
BA_ "GenSigStartValue" SG_ 793 SGU24_Object_dx_Rear 0;
BA_ "GenSigTimeoutValue" SG_ 793 SGU24_Object_dx_Rear 0;
BA_ "Remark" SG_ 793 SGU24_Object_dx_Rear "";
BA_ "EventCommandSignal" SG_ 793 SGU24_Object_dy 0;
BA_ "GatewayedSignals" SG_ 793 SGU24_Object_dy 0;
BA_ "GenSigInactiveValue" SG_ 793 SGU24_Object_dy 0;
BA_ "GenSigInvalidValue" SG_ 793 SGU24_Object_dy 0;
BA_ "GenSigSendType" SG_ 793 SGU24_Object_dy 1;
BA_ "GenSigStartValue" SG_ 793 SGU24_Object_dy 0;
BA_ "GenSigTimeoutValue" SG_ 793 SGU24_Object_dy 0;
BA_ "Remark" SG_ 793 SGU24_Object_dy "";
BA_ "EventCommandSignal" SG_ 793 SGU24_Object_dy_Rear 0;
BA_ "GatewayedSignals" SG_ 793 SGU24_Object_dy_Rear 0;
BA_ "GenSigInactiveValue" SG_ 793 SGU24_Object_dy_Rear 0;
BA_ "GenSigInvalidValue" SG_ 793 SGU24_Object_dy_Rear 0;
BA_ "GenSigSendType" SG_ 793 SGU24_Object_dy_Rear 1;
BA_ "GenSigStartValue" SG_ 793 SGU24_Object_dy_Rear 0;
BA_ "GenSigTimeoutValue" SG_ 793 SGU24_Object_dy_Rear 0;
BA_ "Remark" SG_ 793 SGU24_Object_dy_Rear "";
BA_ "EventCommandSignal" SG_ 793 SGU24_Object_vx 0;
BA_ "GatewayedSignals" SG_ 793 SGU24_Object_vx 0;
BA_ "GenSigInactiveValue" SG_ 793 SGU24_Object_vx 0;
BA_ "GenSigInvalidValue" SG_ 793 SGU24_Object_vx 0;
BA_ "GenSigSendType" SG_ 793 SGU24_Object_vx 1;
BA_ "GenSigStartValue" SG_ 793 SGU24_Object_vx 0;
BA_ "GenSigTimeoutValue" SG_ 793 SGU24_Object_vx 0;
BA_ "Remark" SG_ 793 SGU24_Object_vx "";
BA_ "EventCommandSignal" SG_ 793 SGU24_Object_vy 0;
BA_ "GatewayedSignals" SG_ 793 SGU24_Object_vy 0;
BA_ "GenSigInactiveValue" SG_ 793 SGU24_Object_vy 0;
BA_ "GenSigInvalidValue" SG_ 793 SGU24_Object_vy 0;
BA_ "GenSigSendType" SG_ 793 SGU24_Object_vy 1;
BA_ "GenSigStartValue" SG_ 793 SGU24_Object_vy 0;
BA_ "GenSigTimeoutValue" SG_ 793 SGU24_Object_vy 0;
BA_ "Remark" SG_ 793 SGU24_Object_vy "";
BA_ "EventCommandSignal" SG_ 793 SGU24_Object_wExist 0;
BA_ "GatewayedSignals" SG_ 793 SGU24_Object_wExist 0;
BA_ "GenSigInactiveValue" SG_ 793 SGU24_Object_wExist 0;
BA_ "GenSigInvalidValue" SG_ 793 SGU24_Object_wExist 0;
BA_ "GenSigSendType" SG_ 793 SGU24_Object_wExist 1;
BA_ "GenSigStartValue" SG_ 793 SGU24_Object_wExist 0;
BA_ "GenSigTimeoutValue" SG_ 793 SGU24_Object_wExist 0;
BA_ "Remark" SG_ 793 SGU24_Object_wExist "";
BA_ "EventCommandSignal" SG_ 793 SGU24_Object_wObstacle 0;
BA_ "GatewayedSignals" SG_ 793 SGU24_Object_wObstacle 0;
BA_ "GenSigInactiveValue" SG_ 793 SGU24_Object_wObstacle 0;
BA_ "GenSigInvalidValue" SG_ 793 SGU24_Object_wObstacle 0;
BA_ "GenSigSendType" SG_ 793 SGU24_Object_wObstacle 1;
BA_ "GenSigStartValue" SG_ 793 SGU24_Object_wObstacle 0;
BA_ "GenSigTimeoutValue" SG_ 793 SGU24_Object_wObstacle 0;
BA_ "Remark" SG_ 793 SGU24_Object_wObstacle "";
BA_ "EventCommandSignal" SG_ 794 SGU25_BlockCounter 0;
BA_ "GatewayedSignals" SG_ 794 SGU25_BlockCounter 0;
BA_ "GenSigInactiveValue" SG_ 794 SGU25_BlockCounter 0;
BA_ "GenSigInvalidValue" SG_ 794 SGU25_BlockCounter 0;
BA_ "GenSigSendType" SG_ 794 SGU25_BlockCounter 1;
BA_ "GenSigStartValue" SG_ 794 SGU25_BlockCounter 0;
BA_ "GenSigTimeoutValue" SG_ 794 SGU25_BlockCounter 0;
BA_ "Remark" SG_ 794 SGU25_BlockCounter "";
BA_ "EventCommandSignal" SG_ 794 SGU25_LifeCycles_OBJ 0;
BA_ "GatewayedSignals" SG_ 794 SGU25_LifeCycles_OBJ 0;
BA_ "GenSigInactiveValue" SG_ 794 SGU25_LifeCycles_OBJ 0;
BA_ "GenSigInvalidValue" SG_ 794 SGU25_LifeCycles_OBJ 0;
BA_ "GenSigSendType" SG_ 794 SGU25_LifeCycles_OBJ 1;
BA_ "GenSigStartValue" SG_ 794 SGU25_LifeCycles_OBJ 0;
BA_ "GenSigTimeoutValue" SG_ 794 SGU25_LifeCycles_OBJ 0;
BA_ "Remark" SG_ 794 SGU25_LifeCycles_OBJ "";
BA_ "EventCommandSignal" SG_ 794 SGU25_Msg_AliveCounter 0;
BA_ "GatewayedSignals" SG_ 794 SGU25_Msg_AliveCounter 0;
BA_ "GenSigInactiveValue" SG_ 794 SGU25_Msg_AliveCounter 0;
BA_ "GenSigInvalidValue" SG_ 794 SGU25_Msg_AliveCounter 0;
BA_ "GenSigSendType" SG_ 794 SGU25_Msg_AliveCounter 1;
BA_ "GenSigStartValue" SG_ 794 SGU25_Msg_AliveCounter 0;
BA_ "GenSigTimeoutValue" SG_ 794 SGU25_Msg_AliveCounter 0;
BA_ "Remark" SG_ 794 SGU25_Msg_AliveCounter "";
BA_ "EventCommandSignal" SG_ 794 SGU25_Msg_CheckSum 0;
BA_ "GatewayedSignals" SG_ 794 SGU25_Msg_CheckSum 0;
BA_ "GenSigInactiveValue" SG_ 794 SGU25_Msg_CheckSum 0;
BA_ "GenSigInvalidValue" SG_ 794 SGU25_Msg_CheckSum 0;
BA_ "GenSigSendType" SG_ 794 SGU25_Msg_CheckSum 1;
BA_ "GenSigStartValue" SG_ 794 SGU25_Msg_CheckSum 0;
BA_ "GenSigTimeoutValue" SG_ 794 SGU25_Msg_CheckSum 0;
BA_ "Remark" SG_ 794 SGU25_Msg_CheckSum "";
BA_ "EventCommandSignal" SG_ 794 SGU25_ObjRCS_25 0;
BA_ "GatewayedSignals" SG_ 794 SGU25_ObjRCS_25 0;
BA_ "GenSigInactiveValue" SG_ 794 SGU25_ObjRCS_25 0;
BA_ "GenSigInvalidValue" SG_ 794 SGU25_ObjRCS_25 0;
BA_ "GenSigSendType" SG_ 794 SGU25_ObjRCS_25 1;
BA_ "GenSigStartValue" SG_ 794 SGU25_ObjRCS_25 0;
BA_ "GenSigTimeoutValue" SG_ 794 SGU25_ObjRCS_25 0;
BA_ "Remark" SG_ 794 SGU25_ObjRCS_25 "";
BA_ "EventCommandSignal" SG_ 794 SGU25_Obj_DistLat_rms 0;
BA_ "GatewayedSignals" SG_ 794 SGU25_Obj_DistLat_rms 0;
BA_ "GenSigInactiveValue" SG_ 794 SGU25_Obj_DistLat_rms 0;
BA_ "GenSigInvalidValue" SG_ 794 SGU25_Obj_DistLat_rms 0;
BA_ "GenSigSendType" SG_ 794 SGU25_Obj_DistLat_rms 1;
BA_ "GenSigStartValue" SG_ 794 SGU25_Obj_DistLat_rms 0;
BA_ "GenSigTimeoutValue" SG_ 794 SGU25_Obj_DistLat_rms 0;
BA_ "Remark" SG_ 794 SGU25_Obj_DistLat_rms "";
BA_ "EventCommandSignal" SG_ 794 SGU25_Obj_VrelLong_rms 0;
BA_ "GatewayedSignals" SG_ 794 SGU25_Obj_VrelLong_rms 0;
BA_ "GenSigInactiveValue" SG_ 794 SGU25_Obj_VrelLong_rms 0;
BA_ "GenSigInvalidValue" SG_ 794 SGU25_Obj_VrelLong_rms 0;
BA_ "GenSigSendType" SG_ 794 SGU25_Obj_VrelLong_rms 1;
BA_ "GenSigStartValue" SG_ 794 SGU25_Obj_VrelLong_rms 0;
BA_ "GenSigTimeoutValue" SG_ 794 SGU25_Obj_VrelLong_rms 0;
BA_ "Remark" SG_ 794 SGU25_Obj_VrelLong_rms "";
BA_ "EventCommandSignal" SG_ 794 SGU25_Obj_Vrelat_rms 0;
BA_ "GatewayedSignals" SG_ 794 SGU25_Obj_Vrelat_rms 0;
BA_ "GenSigInactiveValue" SG_ 794 SGU25_Obj_Vrelat_rms 0;
BA_ "GenSigInvalidValue" SG_ 794 SGU25_Obj_Vrelat_rms 0;
BA_ "GenSigSendType" SG_ 794 SGU25_Obj_Vrelat_rms 1;
BA_ "GenSigStartValue" SG_ 794 SGU25_Obj_Vrelat_rms 0;
BA_ "GenSigTimeoutValue" SG_ 794 SGU25_Obj_Vrelat_rms 0;
BA_ "Remark" SG_ 794 SGU25_Obj_Vrelat_rms "";
BA_ "EventCommandSignal" SG_ 794 SGU25_Object_DetStatus 0;
BA_ "GatewayedSignals" SG_ 794 SGU25_Object_DetStatus 0;
BA_ "GenSigInactiveValue" SG_ 794 SGU25_Object_DetStatus 0;
BA_ "GenSigInvalidValue" SG_ 794 SGU25_Object_DetStatus 0;
BA_ "GenSigSendType" SG_ 794 SGU25_Object_DetStatus 1;
BA_ "GenSigStartValue" SG_ 794 SGU25_Object_DetStatus 0;
BA_ "GenSigTimeoutValue" SG_ 794 SGU25_Object_DetStatus 0;
BA_ "Remark" SG_ 794 SGU25_Object_DetStatus "";
BA_ "EventCommandSignal" SG_ 794 SGU25_Object_DistLong_rms 0;
BA_ "GatewayedSignals" SG_ 794 SGU25_Object_DistLong_rms 0;
BA_ "GenSigInactiveValue" SG_ 794 SGU25_Object_DistLong_rms 0;
BA_ "GenSigInvalidValue" SG_ 794 SGU25_Object_DistLong_rms 0;
BA_ "GenSigSendType" SG_ 794 SGU25_Object_DistLong_rms 1;
BA_ "GenSigStartValue" SG_ 794 SGU25_Object_DistLong_rms 0;
BA_ "GenSigTimeoutValue" SG_ 794 SGU25_Object_DistLong_rms 0;
BA_ "Remark" SG_ 794 SGU25_Object_DistLong_rms "";
BA_ "EventCommandSignal" SG_ 794 SGU25_Object_ID 0;
BA_ "GatewayedSignals" SG_ 794 SGU25_Object_ID 0;
BA_ "GenSigInactiveValue" SG_ 794 SGU25_Object_ID 0;
BA_ "GenSigInvalidValue" SG_ 794 SGU25_Object_ID 0;
BA_ "GenSigSendType" SG_ 794 SGU25_Object_ID 1;
BA_ "GenSigStartValue" SG_ 794 SGU25_Object_ID 0;
BA_ "GenSigTimeoutValue" SG_ 794 SGU25_Object_ID 0;
BA_ "Remark" SG_ 794 SGU25_Object_ID "";
BA_ "EventCommandSignal" SG_ 794 SGU25_Object_Motion_Pattern 0;
BA_ "GatewayedSignals" SG_ 794 SGU25_Object_Motion_Pattern 0;
BA_ "GenSigInactiveValue" SG_ 794 SGU25_Object_Motion_Pattern 0;
BA_ "GenSigInvalidValue" SG_ 794 SGU25_Object_Motion_Pattern 0;
BA_ "GenSigSendType" SG_ 794 SGU25_Object_Motion_Pattern 1;
BA_ "GenSigStartValue" SG_ 794 SGU25_Object_Motion_Pattern 0;
BA_ "GenSigTimeoutValue" SG_ 794 SGU25_Object_Motion_Pattern 0;
BA_ "Remark" SG_ 794 SGU25_Object_Motion_Pattern "";
BA_ "EventCommandSignal" SG_ 794 SGU25_Object_Type 0;
BA_ "GatewayedSignals" SG_ 794 SGU25_Object_Type 0;
BA_ "GenSigInactiveValue" SG_ 794 SGU25_Object_Type 0;
BA_ "GenSigInvalidValue" SG_ 794 SGU25_Object_Type 0;
BA_ "GenSigSendType" SG_ 794 SGU25_Object_Type 1;
BA_ "GenSigStartValue" SG_ 794 SGU25_Object_Type 0;
BA_ "GenSigTimeoutValue" SG_ 794 SGU25_Object_Type 0;
BA_ "Remark" SG_ 794 SGU25_Object_Type "";
BA_ "EventCommandSignal" SG_ 794 SGU25_Object_ax 0;
BA_ "GatewayedSignals" SG_ 794 SGU25_Object_ax 0;
BA_ "GenSigInactiveValue" SG_ 794 SGU25_Object_ax 0;
BA_ "GenSigInvalidValue" SG_ 794 SGU25_Object_ax 0;
BA_ "GenSigSendType" SG_ 794 SGU25_Object_ax 1;
BA_ "GenSigStartValue" SG_ 794 SGU25_Object_ax 0;
BA_ "GenSigTimeoutValue" SG_ 794 SGU25_Object_ax 0;
BA_ "Remark" SG_ 794 SGU25_Object_ax "";
BA_ "EventCommandSignal" SG_ 794 SGU25_Object_ay 0;
BA_ "GatewayedSignals" SG_ 794 SGU25_Object_ay 0;
BA_ "GenSigInactiveValue" SG_ 794 SGU25_Object_ay 0;
BA_ "GenSigInvalidValue" SG_ 794 SGU25_Object_ay 0;
BA_ "GenSigSendType" SG_ 794 SGU25_Object_ay 1;
BA_ "GenSigStartValue" SG_ 794 SGU25_Object_ay 0;
BA_ "GenSigTimeoutValue" SG_ 794 SGU25_Object_ay 0;
BA_ "Remark" SG_ 794 SGU25_Object_ay "";
BA_ "EventCommandSignal" SG_ 794 SGU25_Object_dx 0;
BA_ "GatewayedSignals" SG_ 794 SGU25_Object_dx 0;
BA_ "GenSigInactiveValue" SG_ 794 SGU25_Object_dx 0;
BA_ "GenSigInvalidValue" SG_ 794 SGU25_Object_dx 0;
BA_ "GenSigSendType" SG_ 794 SGU25_Object_dx 1;
BA_ "GenSigStartValue" SG_ 794 SGU25_Object_dx 0;
BA_ "GenSigTimeoutValue" SG_ 794 SGU25_Object_dx 0;
BA_ "Remark" SG_ 794 SGU25_Object_dx "";
BA_ "EventCommandSignal" SG_ 794 SGU25_Object_dx_Rear 0;
BA_ "GatewayedSignals" SG_ 794 SGU25_Object_dx_Rear 0;
BA_ "GenSigInactiveValue" SG_ 794 SGU25_Object_dx_Rear 0;
BA_ "GenSigInvalidValue" SG_ 794 SGU25_Object_dx_Rear 0;
BA_ "GenSigSendType" SG_ 794 SGU25_Object_dx_Rear 1;
BA_ "GenSigStartValue" SG_ 794 SGU25_Object_dx_Rear 0;
BA_ "GenSigTimeoutValue" SG_ 794 SGU25_Object_dx_Rear 0;
BA_ "Remark" SG_ 794 SGU25_Object_dx_Rear "";
BA_ "EventCommandSignal" SG_ 794 SGU25_Object_dy 0;
BA_ "GatewayedSignals" SG_ 794 SGU25_Object_dy 0;
BA_ "GenSigInactiveValue" SG_ 794 SGU25_Object_dy 0;
BA_ "GenSigInvalidValue" SG_ 794 SGU25_Object_dy 0;
BA_ "GenSigSendType" SG_ 794 SGU25_Object_dy 1;
BA_ "GenSigStartValue" SG_ 794 SGU25_Object_dy 0;
BA_ "GenSigTimeoutValue" SG_ 794 SGU25_Object_dy 0;
BA_ "Remark" SG_ 794 SGU25_Object_dy "";
BA_ "EventCommandSignal" SG_ 794 SGU25_Object_dy_Rear 0;
BA_ "GatewayedSignals" SG_ 794 SGU25_Object_dy_Rear 0;
BA_ "GenSigInactiveValue" SG_ 794 SGU25_Object_dy_Rear 0;
BA_ "GenSigInvalidValue" SG_ 794 SGU25_Object_dy_Rear 0;
BA_ "GenSigSendType" SG_ 794 SGU25_Object_dy_Rear 1;
BA_ "GenSigStartValue" SG_ 794 SGU25_Object_dy_Rear 0;
BA_ "GenSigTimeoutValue" SG_ 794 SGU25_Object_dy_Rear 0;
BA_ "Remark" SG_ 794 SGU25_Object_dy_Rear "";
BA_ "EventCommandSignal" SG_ 794 SGU25_Object_vx 0;
BA_ "GatewayedSignals" SG_ 794 SGU25_Object_vx 0;
BA_ "GenSigInactiveValue" SG_ 794 SGU25_Object_vx 0;
BA_ "GenSigInvalidValue" SG_ 794 SGU25_Object_vx 0;
BA_ "GenSigSendType" SG_ 794 SGU25_Object_vx 1;
BA_ "GenSigStartValue" SG_ 794 SGU25_Object_vx 0;
BA_ "GenSigTimeoutValue" SG_ 794 SGU25_Object_vx 0;
BA_ "Remark" SG_ 794 SGU25_Object_vx "";
BA_ "EventCommandSignal" SG_ 794 SGU25_Object_vy 0;
BA_ "GatewayedSignals" SG_ 794 SGU25_Object_vy 0;
BA_ "GenSigInactiveValue" SG_ 794 SGU25_Object_vy 0;
BA_ "GenSigInvalidValue" SG_ 794 SGU25_Object_vy 0;
BA_ "GenSigSendType" SG_ 794 SGU25_Object_vy 1;
BA_ "GenSigStartValue" SG_ 794 SGU25_Object_vy 0;
BA_ "GenSigTimeoutValue" SG_ 794 SGU25_Object_vy 0;
BA_ "Remark" SG_ 794 SGU25_Object_vy "";
BA_ "EventCommandSignal" SG_ 794 SGU25_Object_wExist 0;
BA_ "GatewayedSignals" SG_ 794 SGU25_Object_wExist 0;
BA_ "GenSigInactiveValue" SG_ 794 SGU25_Object_wExist 0;
BA_ "GenSigInvalidValue" SG_ 794 SGU25_Object_wExist 0;
BA_ "GenSigSendType" SG_ 794 SGU25_Object_wExist 1;
BA_ "GenSigStartValue" SG_ 794 SGU25_Object_wExist 0;
BA_ "GenSigTimeoutValue" SG_ 794 SGU25_Object_wExist 0;
BA_ "Remark" SG_ 794 SGU25_Object_wExist "";
BA_ "EventCommandSignal" SG_ 794 SGU25_Object_wObstacle 0;
BA_ "GatewayedSignals" SG_ 794 SGU25_Object_wObstacle 0;
BA_ "GenSigInactiveValue" SG_ 794 SGU25_Object_wObstacle 0;
BA_ "GenSigInvalidValue" SG_ 794 SGU25_Object_wObstacle 0;
BA_ "GenSigSendType" SG_ 794 SGU25_Object_wObstacle 1;
BA_ "GenSigStartValue" SG_ 794 SGU25_Object_wObstacle 0;
BA_ "GenSigTimeoutValue" SG_ 794 SGU25_Object_wObstacle 0;
BA_ "Remark" SG_ 794 SGU25_Object_wObstacle "";
BA_ "EventCommandSignal" SG_ 795 SGU26_BlockCounter 0;
BA_ "GatewayedSignals" SG_ 795 SGU26_BlockCounter 0;
BA_ "GenSigInactiveValue" SG_ 795 SGU26_BlockCounter 0;
BA_ "GenSigInvalidValue" SG_ 795 SGU26_BlockCounter 0;
BA_ "GenSigSendType" SG_ 795 SGU26_BlockCounter 1;
BA_ "GenSigStartValue" SG_ 795 SGU26_BlockCounter 0;
BA_ "GenSigTimeoutValue" SG_ 795 SGU26_BlockCounter 0;
BA_ "Remark" SG_ 795 SGU26_BlockCounter "";
BA_ "EventCommandSignal" SG_ 795 SGU26_LifeCycles_OBJ 0;
BA_ "GatewayedSignals" SG_ 795 SGU26_LifeCycles_OBJ 0;
BA_ "GenSigInactiveValue" SG_ 795 SGU26_LifeCycles_OBJ 0;
BA_ "GenSigInvalidValue" SG_ 795 SGU26_LifeCycles_OBJ 0;
BA_ "GenSigSendType" SG_ 795 SGU26_LifeCycles_OBJ 1;
BA_ "GenSigStartValue" SG_ 795 SGU26_LifeCycles_OBJ 0;
BA_ "GenSigTimeoutValue" SG_ 795 SGU26_LifeCycles_OBJ 0;
BA_ "Remark" SG_ 795 SGU26_LifeCycles_OBJ "";
BA_ "EventCommandSignal" SG_ 795 SGU26_Msg_AliveCounter 0;
BA_ "GatewayedSignals" SG_ 795 SGU26_Msg_AliveCounter 0;
BA_ "GenSigInactiveValue" SG_ 795 SGU26_Msg_AliveCounter 0;
BA_ "GenSigInvalidValue" SG_ 795 SGU26_Msg_AliveCounter 0;
BA_ "GenSigSendType" SG_ 795 SGU26_Msg_AliveCounter 1;
BA_ "GenSigStartValue" SG_ 795 SGU26_Msg_AliveCounter 0;
BA_ "GenSigTimeoutValue" SG_ 795 SGU26_Msg_AliveCounter 0;
BA_ "Remark" SG_ 795 SGU26_Msg_AliveCounter "";
BA_ "EventCommandSignal" SG_ 795 SGU26_Msg_CheckSum 0;
BA_ "GatewayedSignals" SG_ 795 SGU26_Msg_CheckSum 0;
BA_ "GenSigInactiveValue" SG_ 795 SGU26_Msg_CheckSum 0;
BA_ "GenSigInvalidValue" SG_ 795 SGU26_Msg_CheckSum 0;
BA_ "GenSigSendType" SG_ 795 SGU26_Msg_CheckSum 1;
BA_ "GenSigStartValue" SG_ 795 SGU26_Msg_CheckSum 0;
BA_ "GenSigTimeoutValue" SG_ 795 SGU26_Msg_CheckSum 0;
BA_ "Remark" SG_ 795 SGU26_Msg_CheckSum "";
BA_ "EventCommandSignal" SG_ 795 SGU26_ObjRCS_26 0;
BA_ "GatewayedSignals" SG_ 795 SGU26_ObjRCS_26 0;
BA_ "GenSigInactiveValue" SG_ 795 SGU26_ObjRCS_26 0;
BA_ "GenSigInvalidValue" SG_ 795 SGU26_ObjRCS_26 0;
BA_ "GenSigSendType" SG_ 795 SGU26_ObjRCS_26 1;
BA_ "GenSigStartValue" SG_ 795 SGU26_ObjRCS_26 0;
BA_ "GenSigTimeoutValue" SG_ 795 SGU26_ObjRCS_26 0;
BA_ "Remark" SG_ 795 SGU26_ObjRCS_26 "";
BA_ "EventCommandSignal" SG_ 795 SGU26_Obj_DistLat_rms 0;
BA_ "GatewayedSignals" SG_ 795 SGU26_Obj_DistLat_rms 0;
BA_ "GenSigInactiveValue" SG_ 795 SGU26_Obj_DistLat_rms 0;
BA_ "GenSigInvalidValue" SG_ 795 SGU26_Obj_DistLat_rms 0;
BA_ "GenSigSendType" SG_ 795 SGU26_Obj_DistLat_rms 1;
BA_ "GenSigStartValue" SG_ 795 SGU26_Obj_DistLat_rms 0;
BA_ "GenSigTimeoutValue" SG_ 795 SGU26_Obj_DistLat_rms 0;
BA_ "Remark" SG_ 795 SGU26_Obj_DistLat_rms "";
BA_ "EventCommandSignal" SG_ 795 SGU26_Obj_VrelLong_rms 0;
BA_ "GatewayedSignals" SG_ 795 SGU26_Obj_VrelLong_rms 0;
BA_ "GenSigInactiveValue" SG_ 795 SGU26_Obj_VrelLong_rms 0;
BA_ "GenSigInvalidValue" SG_ 795 SGU26_Obj_VrelLong_rms 0;
BA_ "GenSigSendType" SG_ 795 SGU26_Obj_VrelLong_rms 1;
BA_ "GenSigStartValue" SG_ 795 SGU26_Obj_VrelLong_rms 0;
BA_ "GenSigTimeoutValue" SG_ 795 SGU26_Obj_VrelLong_rms 0;
BA_ "Remark" SG_ 795 SGU26_Obj_VrelLong_rms "";
BA_ "EventCommandSignal" SG_ 795 SGU26_Obj_Vrelat_rms 0;
BA_ "GatewayedSignals" SG_ 795 SGU26_Obj_Vrelat_rms 0;
BA_ "GenSigInactiveValue" SG_ 795 SGU26_Obj_Vrelat_rms 0;
BA_ "GenSigInvalidValue" SG_ 795 SGU26_Obj_Vrelat_rms 0;
BA_ "GenSigSendType" SG_ 795 SGU26_Obj_Vrelat_rms 1;
BA_ "GenSigStartValue" SG_ 795 SGU26_Obj_Vrelat_rms 0;
BA_ "GenSigTimeoutValue" SG_ 795 SGU26_Obj_Vrelat_rms 0;
BA_ "Remark" SG_ 795 SGU26_Obj_Vrelat_rms "";
BA_ "EventCommandSignal" SG_ 795 SGU26_Object_DetStatus 0;
BA_ "GatewayedSignals" SG_ 795 SGU26_Object_DetStatus 0;
BA_ "GenSigInactiveValue" SG_ 795 SGU26_Object_DetStatus 0;
BA_ "GenSigInvalidValue" SG_ 795 SGU26_Object_DetStatus 0;
BA_ "GenSigSendType" SG_ 795 SGU26_Object_DetStatus 1;
BA_ "GenSigStartValue" SG_ 795 SGU26_Object_DetStatus 0;
BA_ "GenSigTimeoutValue" SG_ 795 SGU26_Object_DetStatus 0;
BA_ "Remark" SG_ 795 SGU26_Object_DetStatus "";
BA_ "EventCommandSignal" SG_ 795 SGU26_Object_DistLong_rms 0;
BA_ "GatewayedSignals" SG_ 795 SGU26_Object_DistLong_rms 0;
BA_ "GenSigInactiveValue" SG_ 795 SGU26_Object_DistLong_rms 0;
BA_ "GenSigInvalidValue" SG_ 795 SGU26_Object_DistLong_rms 0;
BA_ "GenSigSendType" SG_ 795 SGU26_Object_DistLong_rms 1;
BA_ "GenSigStartValue" SG_ 795 SGU26_Object_DistLong_rms 0;
BA_ "GenSigTimeoutValue" SG_ 795 SGU26_Object_DistLong_rms 0;
BA_ "Remark" SG_ 795 SGU26_Object_DistLong_rms "";
BA_ "EventCommandSignal" SG_ 795 SGU26_Object_ID 0;
BA_ "GatewayedSignals" SG_ 795 SGU26_Object_ID 0;
BA_ "GenSigInactiveValue" SG_ 795 SGU26_Object_ID 0;
BA_ "GenSigInvalidValue" SG_ 795 SGU26_Object_ID 0;
BA_ "GenSigSendType" SG_ 795 SGU26_Object_ID 1;
BA_ "GenSigStartValue" SG_ 795 SGU26_Object_ID 0;
BA_ "GenSigTimeoutValue" SG_ 795 SGU26_Object_ID 0;
BA_ "Remark" SG_ 795 SGU26_Object_ID "";
BA_ "EventCommandSignal" SG_ 795 SGU26_Object_Motion_Pattern 0;
BA_ "GatewayedSignals" SG_ 795 SGU26_Object_Motion_Pattern 0;
BA_ "GenSigInactiveValue" SG_ 795 SGU26_Object_Motion_Pattern 0;
BA_ "GenSigInvalidValue" SG_ 795 SGU26_Object_Motion_Pattern 0;
BA_ "GenSigSendType" SG_ 795 SGU26_Object_Motion_Pattern 1;
BA_ "GenSigStartValue" SG_ 795 SGU26_Object_Motion_Pattern 0;
BA_ "GenSigTimeoutValue" SG_ 795 SGU26_Object_Motion_Pattern 0;
BA_ "Remark" SG_ 795 SGU26_Object_Motion_Pattern "";
BA_ "EventCommandSignal" SG_ 795 SGU26_Object_Type 0;
BA_ "GatewayedSignals" SG_ 795 SGU26_Object_Type 0;
BA_ "GenSigInactiveValue" SG_ 795 SGU26_Object_Type 0;
BA_ "GenSigInvalidValue" SG_ 795 SGU26_Object_Type 0;
BA_ "GenSigSendType" SG_ 795 SGU26_Object_Type 1;
BA_ "GenSigStartValue" SG_ 795 SGU26_Object_Type 0;
BA_ "GenSigTimeoutValue" SG_ 795 SGU26_Object_Type 0;
BA_ "Remark" SG_ 795 SGU26_Object_Type "";
BA_ "EventCommandSignal" SG_ 795 SGU26_Object_ax 0;
BA_ "GatewayedSignals" SG_ 795 SGU26_Object_ax 0;
BA_ "GenSigInactiveValue" SG_ 795 SGU26_Object_ax 0;
BA_ "GenSigInvalidValue" SG_ 795 SGU26_Object_ax 0;
BA_ "GenSigSendType" SG_ 795 SGU26_Object_ax 1;
BA_ "GenSigStartValue" SG_ 795 SGU26_Object_ax 0;
BA_ "GenSigTimeoutValue" SG_ 795 SGU26_Object_ax 0;
BA_ "Remark" SG_ 795 SGU26_Object_ax "";
BA_ "EventCommandSignal" SG_ 795 SGU26_Object_ay 0;
BA_ "GatewayedSignals" SG_ 795 SGU26_Object_ay 0;
BA_ "GenSigInactiveValue" SG_ 795 SGU26_Object_ay 0;
BA_ "GenSigInvalidValue" SG_ 795 SGU26_Object_ay 0;
BA_ "GenSigSendType" SG_ 795 SGU26_Object_ay 1;
BA_ "GenSigStartValue" SG_ 795 SGU26_Object_ay 0;
BA_ "GenSigTimeoutValue" SG_ 795 SGU26_Object_ay 0;
BA_ "Remark" SG_ 795 SGU26_Object_ay "";
BA_ "EventCommandSignal" SG_ 795 SGU26_Object_dx 0;
BA_ "GatewayedSignals" SG_ 795 SGU26_Object_dx 0;
BA_ "GenSigInactiveValue" SG_ 795 SGU26_Object_dx 0;
BA_ "GenSigInvalidValue" SG_ 795 SGU26_Object_dx 0;
BA_ "GenSigSendType" SG_ 795 SGU26_Object_dx 1;
BA_ "GenSigStartValue" SG_ 795 SGU26_Object_dx 0;
BA_ "GenSigTimeoutValue" SG_ 795 SGU26_Object_dx 0;
BA_ "Remark" SG_ 795 SGU26_Object_dx "";
BA_ "EventCommandSignal" SG_ 795 SGU26_Object_dx_Rear 0;
BA_ "GatewayedSignals" SG_ 795 SGU26_Object_dx_Rear 0;
BA_ "GenSigInactiveValue" SG_ 795 SGU26_Object_dx_Rear 0;
BA_ "GenSigInvalidValue" SG_ 795 SGU26_Object_dx_Rear 0;
BA_ "GenSigSendType" SG_ 795 SGU26_Object_dx_Rear 1;
BA_ "GenSigStartValue" SG_ 795 SGU26_Object_dx_Rear 0;
BA_ "GenSigTimeoutValue" SG_ 795 SGU26_Object_dx_Rear 0;
BA_ "Remark" SG_ 795 SGU26_Object_dx_Rear "";
BA_ "EventCommandSignal" SG_ 795 SGU26_Object_dy 0;
BA_ "GatewayedSignals" SG_ 795 SGU26_Object_dy 0;
BA_ "GenSigInactiveValue" SG_ 795 SGU26_Object_dy 0;
BA_ "GenSigInvalidValue" SG_ 795 SGU26_Object_dy 0;
BA_ "GenSigSendType" SG_ 795 SGU26_Object_dy 1;
BA_ "GenSigStartValue" SG_ 795 SGU26_Object_dy 0;
BA_ "GenSigTimeoutValue" SG_ 795 SGU26_Object_dy 0;
BA_ "Remark" SG_ 795 SGU26_Object_dy "";
BA_ "EventCommandSignal" SG_ 795 SGU26_Object_dy_Rear 0;
BA_ "GatewayedSignals" SG_ 795 SGU26_Object_dy_Rear 0;
BA_ "GenSigInactiveValue" SG_ 795 SGU26_Object_dy_Rear 0;
BA_ "GenSigInvalidValue" SG_ 795 SGU26_Object_dy_Rear 0;
BA_ "GenSigSendType" SG_ 795 SGU26_Object_dy_Rear 1;
BA_ "GenSigStartValue" SG_ 795 SGU26_Object_dy_Rear 0;
BA_ "GenSigTimeoutValue" SG_ 795 SGU26_Object_dy_Rear 0;
BA_ "Remark" SG_ 795 SGU26_Object_dy_Rear "";
BA_ "EventCommandSignal" SG_ 795 SGU26_Object_vx 0;
BA_ "GatewayedSignals" SG_ 795 SGU26_Object_vx 0;
BA_ "GenSigInactiveValue" SG_ 795 SGU26_Object_vx 0;
BA_ "GenSigInvalidValue" SG_ 795 SGU26_Object_vx 0;
BA_ "GenSigSendType" SG_ 795 SGU26_Object_vx 1;
BA_ "GenSigStartValue" SG_ 795 SGU26_Object_vx 0;
BA_ "GenSigTimeoutValue" SG_ 795 SGU26_Object_vx 0;
BA_ "Remark" SG_ 795 SGU26_Object_vx "";
BA_ "EventCommandSignal" SG_ 795 SGU26_Object_vy 0;
BA_ "GatewayedSignals" SG_ 795 SGU26_Object_vy 0;
BA_ "GenSigInactiveValue" SG_ 795 SGU26_Object_vy 0;
BA_ "GenSigInvalidValue" SG_ 795 SGU26_Object_vy 0;
BA_ "GenSigSendType" SG_ 795 SGU26_Object_vy 1;
BA_ "GenSigStartValue" SG_ 795 SGU26_Object_vy 0;
BA_ "GenSigTimeoutValue" SG_ 795 SGU26_Object_vy 0;
BA_ "Remark" SG_ 795 SGU26_Object_vy "";
BA_ "EventCommandSignal" SG_ 795 SGU26_Object_wExist 0;
BA_ "GatewayedSignals" SG_ 795 SGU26_Object_wExist 0;
BA_ "GenSigInactiveValue" SG_ 795 SGU26_Object_wExist 0;
BA_ "GenSigInvalidValue" SG_ 795 SGU26_Object_wExist 0;
BA_ "GenSigSendType" SG_ 795 SGU26_Object_wExist 1;
BA_ "GenSigStartValue" SG_ 795 SGU26_Object_wExist 0;
BA_ "GenSigTimeoutValue" SG_ 795 SGU26_Object_wExist 0;
BA_ "Remark" SG_ 795 SGU26_Object_wExist "";
BA_ "EventCommandSignal" SG_ 795 SGU26_Object_wObstacle 0;
BA_ "GatewayedSignals" SG_ 795 SGU26_Object_wObstacle 0;
BA_ "GenSigInactiveValue" SG_ 795 SGU26_Object_wObstacle 0;
BA_ "GenSigInvalidValue" SG_ 795 SGU26_Object_wObstacle 0;
BA_ "GenSigSendType" SG_ 795 SGU26_Object_wObstacle 1;
BA_ "GenSigStartValue" SG_ 795 SGU26_Object_wObstacle 0;
BA_ "GenSigTimeoutValue" SG_ 795 SGU26_Object_wObstacle 0;
BA_ "Remark" SG_ 795 SGU26_Object_wObstacle "";
BA_ "EventCommandSignal" SG_ 796 SGU27_BlockCounter 0;
BA_ "GatewayedSignals" SG_ 796 SGU27_BlockCounter 0;
BA_ "GenSigInactiveValue" SG_ 796 SGU27_BlockCounter 0;
BA_ "GenSigInvalidValue" SG_ 796 SGU27_BlockCounter 0;
BA_ "GenSigSendType" SG_ 796 SGU27_BlockCounter 1;
BA_ "GenSigStartValue" SG_ 796 SGU27_BlockCounter 0;
BA_ "GenSigTimeoutValue" SG_ 796 SGU27_BlockCounter 0;
BA_ "Remark" SG_ 796 SGU27_BlockCounter "";
BA_ "EventCommandSignal" SG_ 796 SGU27_LifeCycles_OBJ 0;
BA_ "GatewayedSignals" SG_ 796 SGU27_LifeCycles_OBJ 0;
BA_ "GenSigInactiveValue" SG_ 796 SGU27_LifeCycles_OBJ 0;
BA_ "GenSigInvalidValue" SG_ 796 SGU27_LifeCycles_OBJ 0;
BA_ "GenSigSendType" SG_ 796 SGU27_LifeCycles_OBJ 1;
BA_ "GenSigStartValue" SG_ 796 SGU27_LifeCycles_OBJ 0;
BA_ "GenSigTimeoutValue" SG_ 796 SGU27_LifeCycles_OBJ 0;
BA_ "Remark" SG_ 796 SGU27_LifeCycles_OBJ "";
BA_ "EventCommandSignal" SG_ 796 SGU27_Msg_AliveCounter 0;
BA_ "GatewayedSignals" SG_ 796 SGU27_Msg_AliveCounter 0;
BA_ "GenSigInactiveValue" SG_ 796 SGU27_Msg_AliveCounter 0;
BA_ "GenSigInvalidValue" SG_ 796 SGU27_Msg_AliveCounter 0;
BA_ "GenSigSendType" SG_ 796 SGU27_Msg_AliveCounter 1;
BA_ "GenSigStartValue" SG_ 796 SGU27_Msg_AliveCounter 0;
BA_ "GenSigTimeoutValue" SG_ 796 SGU27_Msg_AliveCounter 0;
BA_ "Remark" SG_ 796 SGU27_Msg_AliveCounter "";
BA_ "EventCommandSignal" SG_ 796 SGU27_Msg_CheckSum 0;
BA_ "GatewayedSignals" SG_ 796 SGU27_Msg_CheckSum 0;
BA_ "GenSigInactiveValue" SG_ 796 SGU27_Msg_CheckSum 0;
BA_ "GenSigInvalidValue" SG_ 796 SGU27_Msg_CheckSum 0;
BA_ "GenSigSendType" SG_ 796 SGU27_Msg_CheckSum 1;
BA_ "GenSigStartValue" SG_ 796 SGU27_Msg_CheckSum 0;
BA_ "GenSigTimeoutValue" SG_ 796 SGU27_Msg_CheckSum 0;
BA_ "Remark" SG_ 796 SGU27_Msg_CheckSum "";
BA_ "EventCommandSignal" SG_ 796 SGU27_ObjRCS_27 0;
BA_ "GatewayedSignals" SG_ 796 SGU27_ObjRCS_27 0;
BA_ "GenSigInactiveValue" SG_ 796 SGU27_ObjRCS_27 0;
BA_ "GenSigInvalidValue" SG_ 796 SGU27_ObjRCS_27 0;
BA_ "GenSigSendType" SG_ 796 SGU27_ObjRCS_27 1;
BA_ "GenSigStartValue" SG_ 796 SGU27_ObjRCS_27 0;
BA_ "GenSigTimeoutValue" SG_ 796 SGU27_ObjRCS_27 0;
BA_ "Remark" SG_ 796 SGU27_ObjRCS_27 "";
BA_ "EventCommandSignal" SG_ 796 SGU27_Obj_DistLat_rms 0;
BA_ "GatewayedSignals" SG_ 796 SGU27_Obj_DistLat_rms 0;
BA_ "GenSigInactiveValue" SG_ 796 SGU27_Obj_DistLat_rms 0;
BA_ "GenSigInvalidValue" SG_ 796 SGU27_Obj_DistLat_rms 0;
BA_ "GenSigSendType" SG_ 796 SGU27_Obj_DistLat_rms 1;
BA_ "GenSigStartValue" SG_ 796 SGU27_Obj_DistLat_rms 0;
BA_ "GenSigTimeoutValue" SG_ 796 SGU27_Obj_DistLat_rms 0;
BA_ "Remark" SG_ 796 SGU27_Obj_DistLat_rms "";
BA_ "EventCommandSignal" SG_ 796 SGU27_Obj_VrelLong_rms 0;
BA_ "GatewayedSignals" SG_ 796 SGU27_Obj_VrelLong_rms 0;
BA_ "GenSigInactiveValue" SG_ 796 SGU27_Obj_VrelLong_rms 0;
BA_ "GenSigInvalidValue" SG_ 796 SGU27_Obj_VrelLong_rms 0;
BA_ "GenSigSendType" SG_ 796 SGU27_Obj_VrelLong_rms 1;
BA_ "GenSigStartValue" SG_ 796 SGU27_Obj_VrelLong_rms 0;
BA_ "GenSigTimeoutValue" SG_ 796 SGU27_Obj_VrelLong_rms 0;
BA_ "Remark" SG_ 796 SGU27_Obj_VrelLong_rms "";
BA_ "EventCommandSignal" SG_ 796 SGU27_Obj_Vrelat_rms 0;
BA_ "GatewayedSignals" SG_ 796 SGU27_Obj_Vrelat_rms 0;
BA_ "GenSigInactiveValue" SG_ 796 SGU27_Obj_Vrelat_rms 0;
BA_ "GenSigInvalidValue" SG_ 796 SGU27_Obj_Vrelat_rms 0;
BA_ "GenSigSendType" SG_ 796 SGU27_Obj_Vrelat_rms 1;
BA_ "GenSigStartValue" SG_ 796 SGU27_Obj_Vrelat_rms 0;
BA_ "GenSigTimeoutValue" SG_ 796 SGU27_Obj_Vrelat_rms 0;
BA_ "Remark" SG_ 796 SGU27_Obj_Vrelat_rms "";
BA_ "EventCommandSignal" SG_ 796 SGU27_Object_DetStatus 0;
BA_ "GatewayedSignals" SG_ 796 SGU27_Object_DetStatus 0;
BA_ "GenSigInactiveValue" SG_ 796 SGU27_Object_DetStatus 0;
BA_ "GenSigInvalidValue" SG_ 796 SGU27_Object_DetStatus 0;
BA_ "GenSigSendType" SG_ 796 SGU27_Object_DetStatus 1;
BA_ "GenSigStartValue" SG_ 796 SGU27_Object_DetStatus 0;
BA_ "GenSigTimeoutValue" SG_ 796 SGU27_Object_DetStatus 0;
BA_ "Remark" SG_ 796 SGU27_Object_DetStatus "";
BA_ "EventCommandSignal" SG_ 796 SGU27_Object_DistLong_rms 0;
BA_ "GatewayedSignals" SG_ 796 SGU27_Object_DistLong_rms 0;
BA_ "GenSigInactiveValue" SG_ 796 SGU27_Object_DistLong_rms 0;
BA_ "GenSigInvalidValue" SG_ 796 SGU27_Object_DistLong_rms 0;
BA_ "GenSigSendType" SG_ 796 SGU27_Object_DistLong_rms 1;
BA_ "GenSigStartValue" SG_ 796 SGU27_Object_DistLong_rms 0;
BA_ "GenSigTimeoutValue" SG_ 796 SGU27_Object_DistLong_rms 0;
BA_ "Remark" SG_ 796 SGU27_Object_DistLong_rms "";
BA_ "EventCommandSignal" SG_ 796 SGU27_Object_ID 0;
BA_ "GatewayedSignals" SG_ 796 SGU27_Object_ID 0;
BA_ "GenSigInactiveValue" SG_ 796 SGU27_Object_ID 0;
BA_ "GenSigInvalidValue" SG_ 796 SGU27_Object_ID 0;
BA_ "GenSigSendType" SG_ 796 SGU27_Object_ID 1;
BA_ "GenSigStartValue" SG_ 796 SGU27_Object_ID 0;
BA_ "GenSigTimeoutValue" SG_ 796 SGU27_Object_ID 0;
BA_ "Remark" SG_ 796 SGU27_Object_ID "";
BA_ "EventCommandSignal" SG_ 796 SGU27_Object_Motion_Pattern 0;
BA_ "GatewayedSignals" SG_ 796 SGU27_Object_Motion_Pattern 0;
BA_ "GenSigInactiveValue" SG_ 796 SGU27_Object_Motion_Pattern 0;
BA_ "GenSigInvalidValue" SG_ 796 SGU27_Object_Motion_Pattern 0;
BA_ "GenSigSendType" SG_ 796 SGU27_Object_Motion_Pattern 1;
BA_ "GenSigStartValue" SG_ 796 SGU27_Object_Motion_Pattern 0;
BA_ "GenSigTimeoutValue" SG_ 796 SGU27_Object_Motion_Pattern 0;
BA_ "Remark" SG_ 796 SGU27_Object_Motion_Pattern "";
BA_ "EventCommandSignal" SG_ 796 SGU27_Object_Type 0;
BA_ "GatewayedSignals" SG_ 796 SGU27_Object_Type 0;
BA_ "GenSigInactiveValue" SG_ 796 SGU27_Object_Type 0;
BA_ "GenSigInvalidValue" SG_ 796 SGU27_Object_Type 0;
BA_ "GenSigSendType" SG_ 796 SGU27_Object_Type 1;
BA_ "GenSigStartValue" SG_ 796 SGU27_Object_Type 0;
BA_ "GenSigTimeoutValue" SG_ 796 SGU27_Object_Type 0;
BA_ "Remark" SG_ 796 SGU27_Object_Type "";
BA_ "EventCommandSignal" SG_ 796 SGU27_Object_ax 0;
BA_ "GatewayedSignals" SG_ 796 SGU27_Object_ax 0;
BA_ "GenSigInactiveValue" SG_ 796 SGU27_Object_ax 0;
BA_ "GenSigInvalidValue" SG_ 796 SGU27_Object_ax 0;
BA_ "GenSigSendType" SG_ 796 SGU27_Object_ax 1;
BA_ "GenSigStartValue" SG_ 796 SGU27_Object_ax 0;
BA_ "GenSigTimeoutValue" SG_ 796 SGU27_Object_ax 0;
BA_ "Remark" SG_ 796 SGU27_Object_ax "";
BA_ "EventCommandSignal" SG_ 796 SGU27_Object_ay 0;
BA_ "GatewayedSignals" SG_ 796 SGU27_Object_ay 0;
BA_ "GenSigInactiveValue" SG_ 796 SGU27_Object_ay 0;
BA_ "GenSigInvalidValue" SG_ 796 SGU27_Object_ay 0;
BA_ "GenSigSendType" SG_ 796 SGU27_Object_ay 1;
BA_ "GenSigStartValue" SG_ 796 SGU27_Object_ay 0;
BA_ "GenSigTimeoutValue" SG_ 796 SGU27_Object_ay 0;
BA_ "Remark" SG_ 796 SGU27_Object_ay "";
BA_ "EventCommandSignal" SG_ 796 SGU27_Object_dx 0;
BA_ "GatewayedSignals" SG_ 796 SGU27_Object_dx 0;
BA_ "GenSigInactiveValue" SG_ 796 SGU27_Object_dx 0;
BA_ "GenSigInvalidValue" SG_ 796 SGU27_Object_dx 0;
BA_ "GenSigSendType" SG_ 796 SGU27_Object_dx 1;
BA_ "GenSigStartValue" SG_ 796 SGU27_Object_dx 0;
BA_ "GenSigTimeoutValue" SG_ 796 SGU27_Object_dx 0;
BA_ "Remark" SG_ 796 SGU27_Object_dx "";
BA_ "EventCommandSignal" SG_ 796 SGU27_Object_dx_Rear 0;
BA_ "GatewayedSignals" SG_ 796 SGU27_Object_dx_Rear 0;
BA_ "GenSigInactiveValue" SG_ 796 SGU27_Object_dx_Rear 0;
BA_ "GenSigInvalidValue" SG_ 796 SGU27_Object_dx_Rear 0;
BA_ "GenSigSendType" SG_ 796 SGU27_Object_dx_Rear 1;
BA_ "GenSigStartValue" SG_ 796 SGU27_Object_dx_Rear 0;
BA_ "GenSigTimeoutValue" SG_ 796 SGU27_Object_dx_Rear 0;
BA_ "Remark" SG_ 796 SGU27_Object_dx_Rear "";
BA_ "EventCommandSignal" SG_ 796 SGU27_Object_dy 0;
BA_ "GatewayedSignals" SG_ 796 SGU27_Object_dy 0;
BA_ "GenSigInactiveValue" SG_ 796 SGU27_Object_dy 0;
BA_ "GenSigInvalidValue" SG_ 796 SGU27_Object_dy 0;
BA_ "GenSigSendType" SG_ 796 SGU27_Object_dy 1;
BA_ "GenSigStartValue" SG_ 796 SGU27_Object_dy 0;
BA_ "GenSigTimeoutValue" SG_ 796 SGU27_Object_dy 0;
BA_ "Remark" SG_ 796 SGU27_Object_dy "";
BA_ "EventCommandSignal" SG_ 796 SGU27_Object_dy_Rear 0;
BA_ "GatewayedSignals" SG_ 796 SGU27_Object_dy_Rear 0;
BA_ "GenSigInactiveValue" SG_ 796 SGU27_Object_dy_Rear 0;
BA_ "GenSigInvalidValue" SG_ 796 SGU27_Object_dy_Rear 0;
BA_ "GenSigSendType" SG_ 796 SGU27_Object_dy_Rear 1;
BA_ "GenSigStartValue" SG_ 796 SGU27_Object_dy_Rear 0;
BA_ "GenSigTimeoutValue" SG_ 796 SGU27_Object_dy_Rear 0;
BA_ "Remark" SG_ 796 SGU27_Object_dy_Rear "";
BA_ "EventCommandSignal" SG_ 796 SGU27_Object_vx 0;
BA_ "GatewayedSignals" SG_ 796 SGU27_Object_vx 0;
BA_ "GenSigInactiveValue" SG_ 796 SGU27_Object_vx 0;
BA_ "GenSigInvalidValue" SG_ 796 SGU27_Object_vx 0;
BA_ "GenSigSendType" SG_ 796 SGU27_Object_vx 1;
BA_ "GenSigStartValue" SG_ 796 SGU27_Object_vx 0;
BA_ "GenSigTimeoutValue" SG_ 796 SGU27_Object_vx 0;
BA_ "Remark" SG_ 796 SGU27_Object_vx "";
BA_ "EventCommandSignal" SG_ 796 SGU27_Object_vy 0;
BA_ "GatewayedSignals" SG_ 796 SGU27_Object_vy 0;
BA_ "GenSigInactiveValue" SG_ 796 SGU27_Object_vy 0;
BA_ "GenSigInvalidValue" SG_ 796 SGU27_Object_vy 0;
BA_ "GenSigSendType" SG_ 796 SGU27_Object_vy 1;
BA_ "GenSigStartValue" SG_ 796 SGU27_Object_vy 0;
BA_ "GenSigTimeoutValue" SG_ 796 SGU27_Object_vy 0;
BA_ "Remark" SG_ 796 SGU27_Object_vy "";
BA_ "EventCommandSignal" SG_ 796 SGU27_Object_wExist 0;
BA_ "GatewayedSignals" SG_ 796 SGU27_Object_wExist 0;
BA_ "GenSigInactiveValue" SG_ 796 SGU27_Object_wExist 0;
BA_ "GenSigInvalidValue" SG_ 796 SGU27_Object_wExist 0;
BA_ "GenSigSendType" SG_ 796 SGU27_Object_wExist 1;
BA_ "GenSigStartValue" SG_ 796 SGU27_Object_wExist 0;
BA_ "GenSigTimeoutValue" SG_ 796 SGU27_Object_wExist 0;
BA_ "Remark" SG_ 796 SGU27_Object_wExist "";
BA_ "EventCommandSignal" SG_ 796 SGU27_Object_wObstacle 0;
BA_ "GatewayedSignals" SG_ 796 SGU27_Object_wObstacle 0;
BA_ "GenSigInactiveValue" SG_ 796 SGU27_Object_wObstacle 0;
BA_ "GenSigInvalidValue" SG_ 796 SGU27_Object_wObstacle 0;
BA_ "GenSigSendType" SG_ 796 SGU27_Object_wObstacle 1;
BA_ "GenSigStartValue" SG_ 796 SGU27_Object_wObstacle 0;
BA_ "GenSigTimeoutValue" SG_ 796 SGU27_Object_wObstacle 0;
BA_ "Remark" SG_ 796 SGU27_Object_wObstacle "";
BA_ "EventCommandSignal" SG_ 797 SGU28_BlockCounter 0;
BA_ "GatewayedSignals" SG_ 797 SGU28_BlockCounter 0;
BA_ "GenSigInactiveValue" SG_ 797 SGU28_BlockCounter 0;
BA_ "GenSigInvalidValue" SG_ 797 SGU28_BlockCounter 0;
BA_ "GenSigSendType" SG_ 797 SGU28_BlockCounter 1;
BA_ "GenSigStartValue" SG_ 797 SGU28_BlockCounter 0;
BA_ "GenSigTimeoutValue" SG_ 797 SGU28_BlockCounter 0;
BA_ "Remark" SG_ 797 SGU28_BlockCounter "";
BA_ "EventCommandSignal" SG_ 797 SGU28_LifeCycles_OBJ 0;
BA_ "GatewayedSignals" SG_ 797 SGU28_LifeCycles_OBJ 0;
BA_ "GenSigInactiveValue" SG_ 797 SGU28_LifeCycles_OBJ 0;
BA_ "GenSigInvalidValue" SG_ 797 SGU28_LifeCycles_OBJ 0;
BA_ "GenSigSendType" SG_ 797 SGU28_LifeCycles_OBJ 1;
BA_ "GenSigStartValue" SG_ 797 SGU28_LifeCycles_OBJ 0;
BA_ "GenSigTimeoutValue" SG_ 797 SGU28_LifeCycles_OBJ 0;
BA_ "Remark" SG_ 797 SGU28_LifeCycles_OBJ "";
BA_ "EventCommandSignal" SG_ 797 SGU28_Msg_AliveCounter 0;
BA_ "GatewayedSignals" SG_ 797 SGU28_Msg_AliveCounter 0;
BA_ "GenSigInactiveValue" SG_ 797 SGU28_Msg_AliveCounter 0;
BA_ "GenSigInvalidValue" SG_ 797 SGU28_Msg_AliveCounter 0;
BA_ "GenSigSendType" SG_ 797 SGU28_Msg_AliveCounter 1;
BA_ "GenSigStartValue" SG_ 797 SGU28_Msg_AliveCounter 0;
BA_ "GenSigTimeoutValue" SG_ 797 SGU28_Msg_AliveCounter 0;
BA_ "Remark" SG_ 797 SGU28_Msg_AliveCounter "";
BA_ "EventCommandSignal" SG_ 797 SGU28_Msg_CheckSum 0;
BA_ "GatewayedSignals" SG_ 797 SGU28_Msg_CheckSum 0;
BA_ "GenSigInactiveValue" SG_ 797 SGU28_Msg_CheckSum 0;
BA_ "GenSigInvalidValue" SG_ 797 SGU28_Msg_CheckSum 0;
BA_ "GenSigSendType" SG_ 797 SGU28_Msg_CheckSum 1;
BA_ "GenSigStartValue" SG_ 797 SGU28_Msg_CheckSum 0;
BA_ "GenSigTimeoutValue" SG_ 797 SGU28_Msg_CheckSum 0;
BA_ "Remark" SG_ 797 SGU28_Msg_CheckSum "";
BA_ "EventCommandSignal" SG_ 797 SGU28_ObjRCS_28 0;
BA_ "GatewayedSignals" SG_ 797 SGU28_ObjRCS_28 0;
BA_ "GenSigInactiveValue" SG_ 797 SGU28_ObjRCS_28 0;
BA_ "GenSigInvalidValue" SG_ 797 SGU28_ObjRCS_28 0;
BA_ "GenSigSendType" SG_ 797 SGU28_ObjRCS_28 1;
BA_ "GenSigStartValue" SG_ 797 SGU28_ObjRCS_28 0;
BA_ "GenSigTimeoutValue" SG_ 797 SGU28_ObjRCS_28 0;
BA_ "Remark" SG_ 797 SGU28_ObjRCS_28 "";
BA_ "EventCommandSignal" SG_ 797 SGU28_Obj_DistLat_rms 0;
BA_ "GatewayedSignals" SG_ 797 SGU28_Obj_DistLat_rms 0;
BA_ "GenSigInactiveValue" SG_ 797 SGU28_Obj_DistLat_rms 0;
BA_ "GenSigInvalidValue" SG_ 797 SGU28_Obj_DistLat_rms 0;
BA_ "GenSigSendType" SG_ 797 SGU28_Obj_DistLat_rms 1;
BA_ "GenSigStartValue" SG_ 797 SGU28_Obj_DistLat_rms 0;
BA_ "GenSigTimeoutValue" SG_ 797 SGU28_Obj_DistLat_rms 0;
BA_ "Remark" SG_ 797 SGU28_Obj_DistLat_rms "";
BA_ "EventCommandSignal" SG_ 797 SGU28_Obj_VrelLong_rms 0;
BA_ "GatewayedSignals" SG_ 797 SGU28_Obj_VrelLong_rms 0;
BA_ "GenSigInactiveValue" SG_ 797 SGU28_Obj_VrelLong_rms 0;
BA_ "GenSigInvalidValue" SG_ 797 SGU28_Obj_VrelLong_rms 0;
BA_ "GenSigSendType" SG_ 797 SGU28_Obj_VrelLong_rms 1;
BA_ "GenSigStartValue" SG_ 797 SGU28_Obj_VrelLong_rms 0;
BA_ "GenSigTimeoutValue" SG_ 797 SGU28_Obj_VrelLong_rms 0;
BA_ "Remark" SG_ 797 SGU28_Obj_VrelLong_rms "";
BA_ "EventCommandSignal" SG_ 797 SGU28_Obj_Vrelat_rms 0;
BA_ "GatewayedSignals" SG_ 797 SGU28_Obj_Vrelat_rms 0;
BA_ "GenSigInactiveValue" SG_ 797 SGU28_Obj_Vrelat_rms 0;
BA_ "GenSigInvalidValue" SG_ 797 SGU28_Obj_Vrelat_rms 0;
BA_ "GenSigSendType" SG_ 797 SGU28_Obj_Vrelat_rms 1;
BA_ "GenSigStartValue" SG_ 797 SGU28_Obj_Vrelat_rms 0;
BA_ "GenSigTimeoutValue" SG_ 797 SGU28_Obj_Vrelat_rms 0;
BA_ "Remark" SG_ 797 SGU28_Obj_Vrelat_rms "";
BA_ "EventCommandSignal" SG_ 797 SGU28_Object_DetStatus 0;
BA_ "GatewayedSignals" SG_ 797 SGU28_Object_DetStatus 0;
BA_ "GenSigInactiveValue" SG_ 797 SGU28_Object_DetStatus 0;
BA_ "GenSigInvalidValue" SG_ 797 SGU28_Object_DetStatus 0;
BA_ "GenSigSendType" SG_ 797 SGU28_Object_DetStatus 1;
BA_ "GenSigStartValue" SG_ 797 SGU28_Object_DetStatus 0;
BA_ "GenSigTimeoutValue" SG_ 797 SGU28_Object_DetStatus 0;
BA_ "Remark" SG_ 797 SGU28_Object_DetStatus "";
BA_ "EventCommandSignal" SG_ 797 SGU28_Object_DistLong_rms 0;
BA_ "GatewayedSignals" SG_ 797 SGU28_Object_DistLong_rms 0;
BA_ "GenSigInactiveValue" SG_ 797 SGU28_Object_DistLong_rms 0;
BA_ "GenSigInvalidValue" SG_ 797 SGU28_Object_DistLong_rms 0;
BA_ "GenSigSendType" SG_ 797 SGU28_Object_DistLong_rms 1;
BA_ "GenSigStartValue" SG_ 797 SGU28_Object_DistLong_rms 0;
BA_ "GenSigTimeoutValue" SG_ 797 SGU28_Object_DistLong_rms 0;
BA_ "Remark" SG_ 797 SGU28_Object_DistLong_rms "";
BA_ "EventCommandSignal" SG_ 797 SGU28_Object_ID 0;
BA_ "GatewayedSignals" SG_ 797 SGU28_Object_ID 0;
BA_ "GenSigInactiveValue" SG_ 797 SGU28_Object_ID 0;
BA_ "GenSigInvalidValue" SG_ 797 SGU28_Object_ID 0;
BA_ "GenSigSendType" SG_ 797 SGU28_Object_ID 1;
BA_ "GenSigStartValue" SG_ 797 SGU28_Object_ID 0;
BA_ "GenSigTimeoutValue" SG_ 797 SGU28_Object_ID 0;
BA_ "Remark" SG_ 797 SGU28_Object_ID "";
BA_ "EventCommandSignal" SG_ 797 SGU28_Object_Motion_Pattern 0;
BA_ "GatewayedSignals" SG_ 797 SGU28_Object_Motion_Pattern 0;
BA_ "GenSigInactiveValue" SG_ 797 SGU28_Object_Motion_Pattern 0;
BA_ "GenSigInvalidValue" SG_ 797 SGU28_Object_Motion_Pattern 0;
BA_ "GenSigSendType" SG_ 797 SGU28_Object_Motion_Pattern 1;
BA_ "GenSigStartValue" SG_ 797 SGU28_Object_Motion_Pattern 0;
BA_ "GenSigTimeoutValue" SG_ 797 SGU28_Object_Motion_Pattern 0;
BA_ "Remark" SG_ 797 SGU28_Object_Motion_Pattern "";
BA_ "EventCommandSignal" SG_ 797 SGU28_Object_Type 0;
BA_ "GatewayedSignals" SG_ 797 SGU28_Object_Type 0;
BA_ "GenSigInactiveValue" SG_ 797 SGU28_Object_Type 0;
BA_ "GenSigInvalidValue" SG_ 797 SGU28_Object_Type 0;
BA_ "GenSigSendType" SG_ 797 SGU28_Object_Type 1;
BA_ "GenSigStartValue" SG_ 797 SGU28_Object_Type 0;
BA_ "GenSigTimeoutValue" SG_ 797 SGU28_Object_Type 0;
BA_ "Remark" SG_ 797 SGU28_Object_Type "";
BA_ "EventCommandSignal" SG_ 797 SGU28_Object_ax 0;
BA_ "GatewayedSignals" SG_ 797 SGU28_Object_ax 0;
BA_ "GenSigInactiveValue" SG_ 797 SGU28_Object_ax 0;
BA_ "GenSigInvalidValue" SG_ 797 SGU28_Object_ax 0;
BA_ "GenSigSendType" SG_ 797 SGU28_Object_ax 1;
BA_ "GenSigStartValue" SG_ 797 SGU28_Object_ax 0;
BA_ "GenSigTimeoutValue" SG_ 797 SGU28_Object_ax 0;
BA_ "Remark" SG_ 797 SGU28_Object_ax "";
BA_ "EventCommandSignal" SG_ 797 SGU28_Object_ay 0;
BA_ "GatewayedSignals" SG_ 797 SGU28_Object_ay 0;
BA_ "GenSigInactiveValue" SG_ 797 SGU28_Object_ay 0;
BA_ "GenSigInvalidValue" SG_ 797 SGU28_Object_ay 0;
BA_ "GenSigSendType" SG_ 797 SGU28_Object_ay 1;
BA_ "GenSigStartValue" SG_ 797 SGU28_Object_ay 0;
BA_ "GenSigTimeoutValue" SG_ 797 SGU28_Object_ay 0;
BA_ "Remark" SG_ 797 SGU28_Object_ay "";
BA_ "EventCommandSignal" SG_ 797 SGU28_Object_dx 0;
BA_ "GatewayedSignals" SG_ 797 SGU28_Object_dx 0;
BA_ "GenSigInactiveValue" SG_ 797 SGU28_Object_dx 0;
BA_ "GenSigInvalidValue" SG_ 797 SGU28_Object_dx 0;
BA_ "GenSigSendType" SG_ 797 SGU28_Object_dx 1;
BA_ "GenSigStartValue" SG_ 797 SGU28_Object_dx 0;
BA_ "GenSigTimeoutValue" SG_ 797 SGU28_Object_dx 0;
BA_ "Remark" SG_ 797 SGU28_Object_dx "";
BA_ "EventCommandSignal" SG_ 797 SGU28_Object_dx_Rear 0;
BA_ "GatewayedSignals" SG_ 797 SGU28_Object_dx_Rear 0;
BA_ "GenSigInactiveValue" SG_ 797 SGU28_Object_dx_Rear 0;
BA_ "GenSigInvalidValue" SG_ 797 SGU28_Object_dx_Rear 0;
BA_ "GenSigSendType" SG_ 797 SGU28_Object_dx_Rear 1;
BA_ "GenSigStartValue" SG_ 797 SGU28_Object_dx_Rear 0;
BA_ "GenSigTimeoutValue" SG_ 797 SGU28_Object_dx_Rear 0;
BA_ "Remark" SG_ 797 SGU28_Object_dx_Rear "";
BA_ "EventCommandSignal" SG_ 797 SGU28_Object_dy 0;
BA_ "GatewayedSignals" SG_ 797 SGU28_Object_dy 0;
BA_ "GenSigInactiveValue" SG_ 797 SGU28_Object_dy 0;
BA_ "GenSigInvalidValue" SG_ 797 SGU28_Object_dy 0;
BA_ "GenSigSendType" SG_ 797 SGU28_Object_dy 1;
BA_ "GenSigStartValue" SG_ 797 SGU28_Object_dy 0;
BA_ "GenSigTimeoutValue" SG_ 797 SGU28_Object_dy 0;
BA_ "Remark" SG_ 797 SGU28_Object_dy "";
BA_ "EventCommandSignal" SG_ 797 SGU28_Object_dy_Rear 0;
BA_ "GatewayedSignals" SG_ 797 SGU28_Object_dy_Rear 0;
BA_ "GenSigInactiveValue" SG_ 797 SGU28_Object_dy_Rear 0;
BA_ "GenSigInvalidValue" SG_ 797 SGU28_Object_dy_Rear 0;
BA_ "GenSigSendType" SG_ 797 SGU28_Object_dy_Rear 1;
BA_ "GenSigStartValue" SG_ 797 SGU28_Object_dy_Rear 0;
BA_ "GenSigTimeoutValue" SG_ 797 SGU28_Object_dy_Rear 0;
BA_ "Remark" SG_ 797 SGU28_Object_dy_Rear "";
BA_ "EventCommandSignal" SG_ 797 SGU28_Object_vx 0;
BA_ "GatewayedSignals" SG_ 797 SGU28_Object_vx 0;
BA_ "GenSigInactiveValue" SG_ 797 SGU28_Object_vx 0;
BA_ "GenSigInvalidValue" SG_ 797 SGU28_Object_vx 0;
BA_ "GenSigSendType" SG_ 797 SGU28_Object_vx 1;
BA_ "GenSigStartValue" SG_ 797 SGU28_Object_vx 0;
BA_ "GenSigTimeoutValue" SG_ 797 SGU28_Object_vx 0;
BA_ "Remark" SG_ 797 SGU28_Object_vx "";
BA_ "EventCommandSignal" SG_ 797 SGU28_Object_vy 0;
BA_ "GatewayedSignals" SG_ 797 SGU28_Object_vy 0;
BA_ "GenSigInactiveValue" SG_ 797 SGU28_Object_vy 0;
BA_ "GenSigInvalidValue" SG_ 797 SGU28_Object_vy 0;
BA_ "GenSigSendType" SG_ 797 SGU28_Object_vy 1;
BA_ "GenSigStartValue" SG_ 797 SGU28_Object_vy 0;
BA_ "GenSigTimeoutValue" SG_ 797 SGU28_Object_vy 0;
BA_ "Remark" SG_ 797 SGU28_Object_vy "";
BA_ "EventCommandSignal" SG_ 797 SGU28_Object_wExist 0;
BA_ "GatewayedSignals" SG_ 797 SGU28_Object_wExist 0;
BA_ "GenSigInactiveValue" SG_ 797 SGU28_Object_wExist 0;
BA_ "GenSigInvalidValue" SG_ 797 SGU28_Object_wExist 0;
BA_ "GenSigSendType" SG_ 797 SGU28_Object_wExist 1;
BA_ "GenSigStartValue" SG_ 797 SGU28_Object_wExist 0;
BA_ "GenSigTimeoutValue" SG_ 797 SGU28_Object_wExist 0;
BA_ "Remark" SG_ 797 SGU28_Object_wExist "";
BA_ "EventCommandSignal" SG_ 797 SGU28_Object_wObstacle 0;
BA_ "GatewayedSignals" SG_ 797 SGU28_Object_wObstacle 0;
BA_ "GenSigInactiveValue" SG_ 797 SGU28_Object_wObstacle 0;
BA_ "GenSigInvalidValue" SG_ 797 SGU28_Object_wObstacle 0;
BA_ "GenSigSendType" SG_ 797 SGU28_Object_wObstacle 1;
BA_ "GenSigStartValue" SG_ 797 SGU28_Object_wObstacle 0;
BA_ "GenSigTimeoutValue" SG_ 797 SGU28_Object_wObstacle 0;
BA_ "Remark" SG_ 797 SGU28_Object_wObstacle "";
BA_ "EventCommandSignal" SG_ 798 SGU29_BlockCounter 0;
BA_ "GatewayedSignals" SG_ 798 SGU29_BlockCounter 0;
BA_ "GenSigInactiveValue" SG_ 798 SGU29_BlockCounter 0;
BA_ "GenSigInvalidValue" SG_ 798 SGU29_BlockCounter 0;
BA_ "GenSigSendType" SG_ 798 SGU29_BlockCounter 1;
BA_ "GenSigStartValue" SG_ 798 SGU29_BlockCounter 0;
BA_ "GenSigTimeoutValue" SG_ 798 SGU29_BlockCounter 0;
BA_ "Remark" SG_ 798 SGU29_BlockCounter "";
BA_ "EventCommandSignal" SG_ 798 SGU29_LifeCycles_OBJ 0;
BA_ "GatewayedSignals" SG_ 798 SGU29_LifeCycles_OBJ 0;
BA_ "GenSigInactiveValue" SG_ 798 SGU29_LifeCycles_OBJ 0;
BA_ "GenSigInvalidValue" SG_ 798 SGU29_LifeCycles_OBJ 0;
BA_ "GenSigSendType" SG_ 798 SGU29_LifeCycles_OBJ 1;
BA_ "GenSigStartValue" SG_ 798 SGU29_LifeCycles_OBJ 0;
BA_ "GenSigTimeoutValue" SG_ 798 SGU29_LifeCycles_OBJ 0;
BA_ "Remark" SG_ 798 SGU29_LifeCycles_OBJ "";
BA_ "EventCommandSignal" SG_ 798 SGU29_Msg_AliveCounter 0;
BA_ "GatewayedSignals" SG_ 798 SGU29_Msg_AliveCounter 0;
BA_ "GenSigInactiveValue" SG_ 798 SGU29_Msg_AliveCounter 0;
BA_ "GenSigInvalidValue" SG_ 798 SGU29_Msg_AliveCounter 0;
BA_ "GenSigSendType" SG_ 798 SGU29_Msg_AliveCounter 1;
BA_ "GenSigStartValue" SG_ 798 SGU29_Msg_AliveCounter 0;
BA_ "GenSigTimeoutValue" SG_ 798 SGU29_Msg_AliveCounter 0;
BA_ "Remark" SG_ 798 SGU29_Msg_AliveCounter "";
BA_ "EventCommandSignal" SG_ 798 SGU29_Msg_CheckSum 0;
BA_ "GatewayedSignals" SG_ 798 SGU29_Msg_CheckSum 0;
BA_ "GenSigInactiveValue" SG_ 798 SGU29_Msg_CheckSum 0;
BA_ "GenSigInvalidValue" SG_ 798 SGU29_Msg_CheckSum 0;
BA_ "GenSigSendType" SG_ 798 SGU29_Msg_CheckSum 1;
BA_ "GenSigStartValue" SG_ 798 SGU29_Msg_CheckSum 0;
BA_ "GenSigTimeoutValue" SG_ 798 SGU29_Msg_CheckSum 0;
BA_ "Remark" SG_ 798 SGU29_Msg_CheckSum "";
BA_ "EventCommandSignal" SG_ 798 SGU29_ObjRCS_29 0;
BA_ "GatewayedSignals" SG_ 798 SGU29_ObjRCS_29 0;
BA_ "GenSigInactiveValue" SG_ 798 SGU29_ObjRCS_29 0;
BA_ "GenSigInvalidValue" SG_ 798 SGU29_ObjRCS_29 0;
BA_ "GenSigSendType" SG_ 798 SGU29_ObjRCS_29 1;
BA_ "GenSigStartValue" SG_ 798 SGU29_ObjRCS_29 0;
BA_ "GenSigTimeoutValue" SG_ 798 SGU29_ObjRCS_29 0;
BA_ "Remark" SG_ 798 SGU29_ObjRCS_29 "";
BA_ "EventCommandSignal" SG_ 798 SGU29_Obj_DistLat_rms 0;
BA_ "GatewayedSignals" SG_ 798 SGU29_Obj_DistLat_rms 0;
BA_ "GenSigInactiveValue" SG_ 798 SGU29_Obj_DistLat_rms 0;
BA_ "GenSigInvalidValue" SG_ 798 SGU29_Obj_DistLat_rms 0;
BA_ "GenSigSendType" SG_ 798 SGU29_Obj_DistLat_rms 1;
BA_ "GenSigStartValue" SG_ 798 SGU29_Obj_DistLat_rms 0;
BA_ "GenSigTimeoutValue" SG_ 798 SGU29_Obj_DistLat_rms 0;
BA_ "Remark" SG_ 798 SGU29_Obj_DistLat_rms "";
BA_ "EventCommandSignal" SG_ 798 SGU29_Obj_VrelLong_rms 0;
BA_ "GatewayedSignals" SG_ 798 SGU29_Obj_VrelLong_rms 0;
BA_ "GenSigInactiveValue" SG_ 798 SGU29_Obj_VrelLong_rms 0;
BA_ "GenSigInvalidValue" SG_ 798 SGU29_Obj_VrelLong_rms 0;
BA_ "GenSigSendType" SG_ 798 SGU29_Obj_VrelLong_rms 1;
BA_ "GenSigStartValue" SG_ 798 SGU29_Obj_VrelLong_rms 0;
BA_ "GenSigTimeoutValue" SG_ 798 SGU29_Obj_VrelLong_rms 0;
BA_ "Remark" SG_ 798 SGU29_Obj_VrelLong_rms "";
BA_ "EventCommandSignal" SG_ 798 SGU29_Obj_Vrelat_rms 0;
BA_ "GatewayedSignals" SG_ 798 SGU29_Obj_Vrelat_rms 0;
BA_ "GenSigInactiveValue" SG_ 798 SGU29_Obj_Vrelat_rms 0;
BA_ "GenSigInvalidValue" SG_ 798 SGU29_Obj_Vrelat_rms 0;
BA_ "GenSigSendType" SG_ 798 SGU29_Obj_Vrelat_rms 1;
BA_ "GenSigStartValue" SG_ 798 SGU29_Obj_Vrelat_rms 0;
BA_ "GenSigTimeoutValue" SG_ 798 SGU29_Obj_Vrelat_rms 0;
BA_ "Remark" SG_ 798 SGU29_Obj_Vrelat_rms "";
BA_ "EventCommandSignal" SG_ 798 SGU29_Object_DetStatus 0;
BA_ "GatewayedSignals" SG_ 798 SGU29_Object_DetStatus 0;
BA_ "GenSigInactiveValue" SG_ 798 SGU29_Object_DetStatus 0;
BA_ "GenSigInvalidValue" SG_ 798 SGU29_Object_DetStatus 0;
BA_ "GenSigSendType" SG_ 798 SGU29_Object_DetStatus 1;
BA_ "GenSigStartValue" SG_ 798 SGU29_Object_DetStatus 0;
BA_ "GenSigTimeoutValue" SG_ 798 SGU29_Object_DetStatus 0;
BA_ "Remark" SG_ 798 SGU29_Object_DetStatus "";
BA_ "EventCommandSignal" SG_ 798 SGU29_Object_DistLong_rms 0;
BA_ "GatewayedSignals" SG_ 798 SGU29_Object_DistLong_rms 0;
BA_ "GenSigInactiveValue" SG_ 798 SGU29_Object_DistLong_rms 0;
BA_ "GenSigInvalidValue" SG_ 798 SGU29_Object_DistLong_rms 0;
BA_ "GenSigSendType" SG_ 798 SGU29_Object_DistLong_rms 1;
BA_ "GenSigStartValue" SG_ 798 SGU29_Object_DistLong_rms 0;
BA_ "GenSigTimeoutValue" SG_ 798 SGU29_Object_DistLong_rms 0;
BA_ "Remark" SG_ 798 SGU29_Object_DistLong_rms "";
BA_ "EventCommandSignal" SG_ 798 SGU29_Object_ID 0;
BA_ "GatewayedSignals" SG_ 798 SGU29_Object_ID 0;
BA_ "GenSigInactiveValue" SG_ 798 SGU29_Object_ID 0;
BA_ "GenSigInvalidValue" SG_ 798 SGU29_Object_ID 0;
BA_ "GenSigSendType" SG_ 798 SGU29_Object_ID 1;
BA_ "GenSigStartValue" SG_ 798 SGU29_Object_ID 0;
BA_ "GenSigTimeoutValue" SG_ 798 SGU29_Object_ID 0;
BA_ "Remark" SG_ 798 SGU29_Object_ID "";
BA_ "EventCommandSignal" SG_ 798 SGU29_Object_Motion_Pattern 0;
BA_ "GatewayedSignals" SG_ 798 SGU29_Object_Motion_Pattern 0;
BA_ "GenSigInactiveValue" SG_ 798 SGU29_Object_Motion_Pattern 0;
BA_ "GenSigInvalidValue" SG_ 798 SGU29_Object_Motion_Pattern 0;
BA_ "GenSigSendType" SG_ 798 SGU29_Object_Motion_Pattern 1;
BA_ "GenSigStartValue" SG_ 798 SGU29_Object_Motion_Pattern 0;
BA_ "GenSigTimeoutValue" SG_ 798 SGU29_Object_Motion_Pattern 0;
BA_ "Remark" SG_ 798 SGU29_Object_Motion_Pattern "";
BA_ "EventCommandSignal" SG_ 798 SGU29_Object_Type 0;
BA_ "GatewayedSignals" SG_ 798 SGU29_Object_Type 0;
BA_ "GenSigInactiveValue" SG_ 798 SGU29_Object_Type 0;
BA_ "GenSigInvalidValue" SG_ 798 SGU29_Object_Type 0;
BA_ "GenSigSendType" SG_ 798 SGU29_Object_Type 1;
BA_ "GenSigStartValue" SG_ 798 SGU29_Object_Type 0;
BA_ "GenSigTimeoutValue" SG_ 798 SGU29_Object_Type 0;
BA_ "Remark" SG_ 798 SGU29_Object_Type "";
BA_ "EventCommandSignal" SG_ 798 SGU29_Object_ax 0;
BA_ "GatewayedSignals" SG_ 798 SGU29_Object_ax 0;
BA_ "GenSigInactiveValue" SG_ 798 SGU29_Object_ax 0;
BA_ "GenSigInvalidValue" SG_ 798 SGU29_Object_ax 0;
BA_ "GenSigSendType" SG_ 798 SGU29_Object_ax 1;
BA_ "GenSigStartValue" SG_ 798 SGU29_Object_ax 0;
BA_ "GenSigTimeoutValue" SG_ 798 SGU29_Object_ax 0;
BA_ "Remark" SG_ 798 SGU29_Object_ax "";
BA_ "EventCommandSignal" SG_ 798 SGU29_Object_ay 0;
BA_ "GatewayedSignals" SG_ 798 SGU29_Object_ay 0;
BA_ "GenSigInactiveValue" SG_ 798 SGU29_Object_ay 0;
BA_ "GenSigInvalidValue" SG_ 798 SGU29_Object_ay 0;
BA_ "GenSigSendType" SG_ 798 SGU29_Object_ay 1;
BA_ "GenSigStartValue" SG_ 798 SGU29_Object_ay 0;
BA_ "GenSigTimeoutValue" SG_ 798 SGU29_Object_ay 0;
BA_ "Remark" SG_ 798 SGU29_Object_ay "";
BA_ "EventCommandSignal" SG_ 798 SGU29_Object_dx 0;
BA_ "GatewayedSignals" SG_ 798 SGU29_Object_dx 0;
BA_ "GenSigInactiveValue" SG_ 798 SGU29_Object_dx 0;
BA_ "GenSigInvalidValue" SG_ 798 SGU29_Object_dx 0;
BA_ "GenSigSendType" SG_ 798 SGU29_Object_dx 1;
BA_ "GenSigStartValue" SG_ 798 SGU29_Object_dx 0;
BA_ "GenSigTimeoutValue" SG_ 798 SGU29_Object_dx 0;
BA_ "Remark" SG_ 798 SGU29_Object_dx "";
BA_ "EventCommandSignal" SG_ 798 SGU29_Object_dx_Rear 0;
BA_ "GatewayedSignals" SG_ 798 SGU29_Object_dx_Rear 0;
BA_ "GenSigInactiveValue" SG_ 798 SGU29_Object_dx_Rear 0;
BA_ "GenSigInvalidValue" SG_ 798 SGU29_Object_dx_Rear 0;
BA_ "GenSigSendType" SG_ 798 SGU29_Object_dx_Rear 1;
BA_ "GenSigStartValue" SG_ 798 SGU29_Object_dx_Rear 0;
BA_ "GenSigTimeoutValue" SG_ 798 SGU29_Object_dx_Rear 0;
BA_ "Remark" SG_ 798 SGU29_Object_dx_Rear "";
BA_ "EventCommandSignal" SG_ 798 SGU29_Object_dy 0;
BA_ "GatewayedSignals" SG_ 798 SGU29_Object_dy 0;
BA_ "GenSigInactiveValue" SG_ 798 SGU29_Object_dy 0;
BA_ "GenSigInvalidValue" SG_ 798 SGU29_Object_dy 0;
BA_ "GenSigSendType" SG_ 798 SGU29_Object_dy 1;
BA_ "GenSigStartValue" SG_ 798 SGU29_Object_dy 0;
BA_ "GenSigTimeoutValue" SG_ 798 SGU29_Object_dy 0;
BA_ "Remark" SG_ 798 SGU29_Object_dy "";
BA_ "EventCommandSignal" SG_ 798 SGU29_Object_dy_Rear 0;
BA_ "GatewayedSignals" SG_ 798 SGU29_Object_dy_Rear 0;
BA_ "GenSigInactiveValue" SG_ 798 SGU29_Object_dy_Rear 0;
BA_ "GenSigInvalidValue" SG_ 798 SGU29_Object_dy_Rear 0;
BA_ "GenSigSendType" SG_ 798 SGU29_Object_dy_Rear 1;
BA_ "GenSigStartValue" SG_ 798 SGU29_Object_dy_Rear 0;
BA_ "GenSigTimeoutValue" SG_ 798 SGU29_Object_dy_Rear 0;
BA_ "Remark" SG_ 798 SGU29_Object_dy_Rear "";
BA_ "EventCommandSignal" SG_ 798 SGU29_Object_vx 0;
BA_ "GatewayedSignals" SG_ 798 SGU29_Object_vx 0;
BA_ "GenSigInactiveValue" SG_ 798 SGU29_Object_vx 0;
BA_ "GenSigInvalidValue" SG_ 798 SGU29_Object_vx 0;
BA_ "GenSigSendType" SG_ 798 SGU29_Object_vx 1;
BA_ "GenSigStartValue" SG_ 798 SGU29_Object_vx 0;
BA_ "GenSigTimeoutValue" SG_ 798 SGU29_Object_vx 0;
BA_ "Remark" SG_ 798 SGU29_Object_vx "";
BA_ "EventCommandSignal" SG_ 798 SGU29_Object_vy 0;
BA_ "GatewayedSignals" SG_ 798 SGU29_Object_vy 0;
BA_ "GenSigInactiveValue" SG_ 798 SGU29_Object_vy 0;
BA_ "GenSigInvalidValue" SG_ 798 SGU29_Object_vy 0;
BA_ "GenSigSendType" SG_ 798 SGU29_Object_vy 1;
BA_ "GenSigStartValue" SG_ 798 SGU29_Object_vy 0;
BA_ "GenSigTimeoutValue" SG_ 798 SGU29_Object_vy 0;
BA_ "Remark" SG_ 798 SGU29_Object_vy "";
BA_ "EventCommandSignal" SG_ 798 SGU29_Object_wExist 0;
BA_ "GatewayedSignals" SG_ 798 SGU29_Object_wExist 0;
BA_ "GenSigInactiveValue" SG_ 798 SGU29_Object_wExist 0;
BA_ "GenSigInvalidValue" SG_ 798 SGU29_Object_wExist 0;
BA_ "GenSigSendType" SG_ 798 SGU29_Object_wExist 1;
BA_ "GenSigStartValue" SG_ 798 SGU29_Object_wExist 0;
BA_ "GenSigTimeoutValue" SG_ 798 SGU29_Object_wExist 0;
BA_ "Remark" SG_ 798 SGU29_Object_wExist "";
BA_ "EventCommandSignal" SG_ 798 SGU29_Object_wObstacle 0;
BA_ "GatewayedSignals" SG_ 798 SGU29_Object_wObstacle 0;
BA_ "GenSigInactiveValue" SG_ 798 SGU29_Object_wObstacle 0;
BA_ "GenSigInvalidValue" SG_ 798 SGU29_Object_wObstacle 0;
BA_ "GenSigSendType" SG_ 798 SGU29_Object_wObstacle 1;
BA_ "GenSigStartValue" SG_ 798 SGU29_Object_wObstacle 0;
BA_ "GenSigTimeoutValue" SG_ 798 SGU29_Object_wObstacle 0;
BA_ "Remark" SG_ 798 SGU29_Object_wObstacle "";
BA_ "EventCommandSignal" SG_ 799 SGU30_BlockCounter 0;
BA_ "GatewayedSignals" SG_ 799 SGU30_BlockCounter 0;
BA_ "GenSigInactiveValue" SG_ 799 SGU30_BlockCounter 0;
BA_ "GenSigInvalidValue" SG_ 799 SGU30_BlockCounter 0;
BA_ "GenSigSendType" SG_ 799 SGU30_BlockCounter 1;
BA_ "GenSigStartValue" SG_ 799 SGU30_BlockCounter 0;
BA_ "GenSigTimeoutValue" SG_ 799 SGU30_BlockCounter 0;
BA_ "Remark" SG_ 799 SGU30_BlockCounter "";
BA_ "EventCommandSignal" SG_ 799 SGU30_LifeCycles_OBJ 0;
BA_ "GatewayedSignals" SG_ 799 SGU30_LifeCycles_OBJ 0;
BA_ "GenSigInactiveValue" SG_ 799 SGU30_LifeCycles_OBJ 0;
BA_ "GenSigInvalidValue" SG_ 799 SGU30_LifeCycles_OBJ 0;
BA_ "GenSigSendType" SG_ 799 SGU30_LifeCycles_OBJ 1;
BA_ "GenSigStartValue" SG_ 799 SGU30_LifeCycles_OBJ 0;
BA_ "GenSigTimeoutValue" SG_ 799 SGU30_LifeCycles_OBJ 0;
BA_ "Remark" SG_ 799 SGU30_LifeCycles_OBJ "";
BA_ "EventCommandSignal" SG_ 799 SGU30_Msg_AliveCounter 0;
BA_ "GatewayedSignals" SG_ 799 SGU30_Msg_AliveCounter 0;
BA_ "GenSigInactiveValue" SG_ 799 SGU30_Msg_AliveCounter 0;
BA_ "GenSigInvalidValue" SG_ 799 SGU30_Msg_AliveCounter 0;
BA_ "GenSigSendType" SG_ 799 SGU30_Msg_AliveCounter 1;
BA_ "GenSigStartValue" SG_ 799 SGU30_Msg_AliveCounter 0;
BA_ "GenSigTimeoutValue" SG_ 799 SGU30_Msg_AliveCounter 0;
BA_ "Remark" SG_ 799 SGU30_Msg_AliveCounter "";
BA_ "EventCommandSignal" SG_ 799 SGU30_Msg_CheckSum 0;
BA_ "GatewayedSignals" SG_ 799 SGU30_Msg_CheckSum 0;
BA_ "GenSigInactiveValue" SG_ 799 SGU30_Msg_CheckSum 0;
BA_ "GenSigInvalidValue" SG_ 799 SGU30_Msg_CheckSum 0;
BA_ "GenSigSendType" SG_ 799 SGU30_Msg_CheckSum 1;
BA_ "GenSigStartValue" SG_ 799 SGU30_Msg_CheckSum 0;
BA_ "GenSigTimeoutValue" SG_ 799 SGU30_Msg_CheckSum 0;
BA_ "Remark" SG_ 799 SGU30_Msg_CheckSum "";
BA_ "EventCommandSignal" SG_ 799 SGU30_ObjRCS_30 0;
BA_ "GatewayedSignals" SG_ 799 SGU30_ObjRCS_30 0;
BA_ "GenSigInactiveValue" SG_ 799 SGU30_ObjRCS_30 0;
BA_ "GenSigInvalidValue" SG_ 799 SGU30_ObjRCS_30 0;
BA_ "GenSigSendType" SG_ 799 SGU30_ObjRCS_30 1;
BA_ "GenSigStartValue" SG_ 799 SGU30_ObjRCS_30 0;
BA_ "GenSigTimeoutValue" SG_ 799 SGU30_ObjRCS_30 0;
BA_ "Remark" SG_ 799 SGU30_ObjRCS_30 "";
BA_ "EventCommandSignal" SG_ 799 SGU30_Obj_DistLat_rms 0;
BA_ "GatewayedSignals" SG_ 799 SGU30_Obj_DistLat_rms 0;
BA_ "GenSigInactiveValue" SG_ 799 SGU30_Obj_DistLat_rms 0;
BA_ "GenSigInvalidValue" SG_ 799 SGU30_Obj_DistLat_rms 0;
BA_ "GenSigSendType" SG_ 799 SGU30_Obj_DistLat_rms 1;
BA_ "GenSigStartValue" SG_ 799 SGU30_Obj_DistLat_rms 0;
BA_ "GenSigTimeoutValue" SG_ 799 SGU30_Obj_DistLat_rms 0;
BA_ "Remark" SG_ 799 SGU30_Obj_DistLat_rms "";
BA_ "EventCommandSignal" SG_ 799 SGU30_Obj_VrelLong_rms 0;
BA_ "GatewayedSignals" SG_ 799 SGU30_Obj_VrelLong_rms 0;
BA_ "GenSigInactiveValue" SG_ 799 SGU30_Obj_VrelLong_rms 0;
BA_ "GenSigInvalidValue" SG_ 799 SGU30_Obj_VrelLong_rms 0;
BA_ "GenSigSendType" SG_ 799 SGU30_Obj_VrelLong_rms 1;
BA_ "GenSigStartValue" SG_ 799 SGU30_Obj_VrelLong_rms 0;
BA_ "GenSigTimeoutValue" SG_ 799 SGU30_Obj_VrelLong_rms 0;
BA_ "Remark" SG_ 799 SGU30_Obj_VrelLong_rms "";
BA_ "EventCommandSignal" SG_ 799 SGU30_Obj_Vrelat_rms 0;
BA_ "GatewayedSignals" SG_ 799 SGU30_Obj_Vrelat_rms 0;
BA_ "GenSigInactiveValue" SG_ 799 SGU30_Obj_Vrelat_rms 0;
BA_ "GenSigInvalidValue" SG_ 799 SGU30_Obj_Vrelat_rms 0;
BA_ "GenSigSendType" SG_ 799 SGU30_Obj_Vrelat_rms 1;
BA_ "GenSigStartValue" SG_ 799 SGU30_Obj_Vrelat_rms 0;
BA_ "GenSigTimeoutValue" SG_ 799 SGU30_Obj_Vrelat_rms 0;
BA_ "Remark" SG_ 799 SGU30_Obj_Vrelat_rms "";
BA_ "EventCommandSignal" SG_ 799 SGU30_Object_DetStatus 0;
BA_ "GatewayedSignals" SG_ 799 SGU30_Object_DetStatus 0;
BA_ "GenSigInactiveValue" SG_ 799 SGU30_Object_DetStatus 0;
BA_ "GenSigInvalidValue" SG_ 799 SGU30_Object_DetStatus 0;
BA_ "GenSigSendType" SG_ 799 SGU30_Object_DetStatus 1;
BA_ "GenSigStartValue" SG_ 799 SGU30_Object_DetStatus 0;
BA_ "GenSigTimeoutValue" SG_ 799 SGU30_Object_DetStatus 0;
BA_ "Remark" SG_ 799 SGU30_Object_DetStatus "";
BA_ "EventCommandSignal" SG_ 799 SGU30_Object_DistLong_rms 0;
BA_ "GatewayedSignals" SG_ 799 SGU30_Object_DistLong_rms 0;
BA_ "GenSigInactiveValue" SG_ 799 SGU30_Object_DistLong_rms 0;
BA_ "GenSigInvalidValue" SG_ 799 SGU30_Object_DistLong_rms 0;
BA_ "GenSigSendType" SG_ 799 SGU30_Object_DistLong_rms 1;
BA_ "GenSigStartValue" SG_ 799 SGU30_Object_DistLong_rms 0;
BA_ "GenSigTimeoutValue" SG_ 799 SGU30_Object_DistLong_rms 0;
BA_ "Remark" SG_ 799 SGU30_Object_DistLong_rms "";
BA_ "EventCommandSignal" SG_ 799 SGU30_Object_ID 0;
BA_ "GatewayedSignals" SG_ 799 SGU30_Object_ID 0;
BA_ "GenSigInactiveValue" SG_ 799 SGU30_Object_ID 0;
BA_ "GenSigInvalidValue" SG_ 799 SGU30_Object_ID 0;
BA_ "GenSigSendType" SG_ 799 SGU30_Object_ID 1;
BA_ "GenSigStartValue" SG_ 799 SGU30_Object_ID 0;
BA_ "GenSigTimeoutValue" SG_ 799 SGU30_Object_ID 0;
BA_ "Remark" SG_ 799 SGU30_Object_ID "";
BA_ "EventCommandSignal" SG_ 799 SGU30_Object_Motion_Pattern 0;
BA_ "GatewayedSignals" SG_ 799 SGU30_Object_Motion_Pattern 0;
BA_ "GenSigInactiveValue" SG_ 799 SGU30_Object_Motion_Pattern 0;
BA_ "GenSigInvalidValue" SG_ 799 SGU30_Object_Motion_Pattern 0;
BA_ "GenSigSendType" SG_ 799 SGU30_Object_Motion_Pattern 1;
BA_ "GenSigStartValue" SG_ 799 SGU30_Object_Motion_Pattern 0;
BA_ "GenSigTimeoutValue" SG_ 799 SGU30_Object_Motion_Pattern 0;
BA_ "Remark" SG_ 799 SGU30_Object_Motion_Pattern "";
BA_ "EventCommandSignal" SG_ 799 SGU30_Object_Type 0;
BA_ "GatewayedSignals" SG_ 799 SGU30_Object_Type 0;
BA_ "GenSigInactiveValue" SG_ 799 SGU30_Object_Type 0;
BA_ "GenSigInvalidValue" SG_ 799 SGU30_Object_Type 0;
BA_ "GenSigSendType" SG_ 799 SGU30_Object_Type 1;
BA_ "GenSigStartValue" SG_ 799 SGU30_Object_Type 0;
BA_ "GenSigTimeoutValue" SG_ 799 SGU30_Object_Type 0;
BA_ "Remark" SG_ 799 SGU30_Object_Type "";
BA_ "EventCommandSignal" SG_ 799 SGU30_Object_ax 0;
BA_ "GatewayedSignals" SG_ 799 SGU30_Object_ax 0;
BA_ "GenSigInactiveValue" SG_ 799 SGU30_Object_ax 0;
BA_ "GenSigInvalidValue" SG_ 799 SGU30_Object_ax 0;
BA_ "GenSigSendType" SG_ 799 SGU30_Object_ax 1;
BA_ "GenSigStartValue" SG_ 799 SGU30_Object_ax 0;
BA_ "GenSigTimeoutValue" SG_ 799 SGU30_Object_ax 0;
BA_ "Remark" SG_ 799 SGU30_Object_ax "";
BA_ "EventCommandSignal" SG_ 799 SGU30_Object_ay 0;
BA_ "GatewayedSignals" SG_ 799 SGU30_Object_ay 0;
BA_ "GenSigInactiveValue" SG_ 799 SGU30_Object_ay 0;
BA_ "GenSigInvalidValue" SG_ 799 SGU30_Object_ay 0;
BA_ "GenSigSendType" SG_ 799 SGU30_Object_ay 1;
BA_ "GenSigStartValue" SG_ 799 SGU30_Object_ay 0;
BA_ "GenSigTimeoutValue" SG_ 799 SGU30_Object_ay 0;
BA_ "Remark" SG_ 799 SGU30_Object_ay "";
BA_ "EventCommandSignal" SG_ 799 SGU30_Object_dx 0;
BA_ "GatewayedSignals" SG_ 799 SGU30_Object_dx 0;
BA_ "GenSigInactiveValue" SG_ 799 SGU30_Object_dx 0;
BA_ "GenSigInvalidValue" SG_ 799 SGU30_Object_dx 0;
BA_ "GenSigSendType" SG_ 799 SGU30_Object_dx 1;
BA_ "GenSigStartValue" SG_ 799 SGU30_Object_dx 0;
BA_ "GenSigTimeoutValue" SG_ 799 SGU30_Object_dx 0;
BA_ "Remark" SG_ 799 SGU30_Object_dx "";
BA_ "EventCommandSignal" SG_ 799 SGU30_Object_dx_Rear 0;
BA_ "GatewayedSignals" SG_ 799 SGU30_Object_dx_Rear 0;
BA_ "GenSigInactiveValue" SG_ 799 SGU30_Object_dx_Rear 0;
BA_ "GenSigInvalidValue" SG_ 799 SGU30_Object_dx_Rear 0;
BA_ "GenSigSendType" SG_ 799 SGU30_Object_dx_Rear 1;
BA_ "GenSigStartValue" SG_ 799 SGU30_Object_dx_Rear 0;
BA_ "GenSigTimeoutValue" SG_ 799 SGU30_Object_dx_Rear 0;
BA_ "Remark" SG_ 799 SGU30_Object_dx_Rear "";
BA_ "EventCommandSignal" SG_ 799 SGU30_Object_dy 0;
BA_ "GatewayedSignals" SG_ 799 SGU30_Object_dy 0;
BA_ "GenSigInactiveValue" SG_ 799 SGU30_Object_dy 0;
BA_ "GenSigInvalidValue" SG_ 799 SGU30_Object_dy 0;
BA_ "GenSigSendType" SG_ 799 SGU30_Object_dy 1;
BA_ "GenSigStartValue" SG_ 799 SGU30_Object_dy 0;
BA_ "GenSigTimeoutValue" SG_ 799 SGU30_Object_dy 0;
BA_ "Remark" SG_ 799 SGU30_Object_dy "";
BA_ "EventCommandSignal" SG_ 799 SGU30_Object_dy_Rear 0;
BA_ "GatewayedSignals" SG_ 799 SGU30_Object_dy_Rear 0;
BA_ "GenSigInactiveValue" SG_ 799 SGU30_Object_dy_Rear 0;
BA_ "GenSigInvalidValue" SG_ 799 SGU30_Object_dy_Rear 0;
BA_ "GenSigSendType" SG_ 799 SGU30_Object_dy_Rear 1;
BA_ "GenSigStartValue" SG_ 799 SGU30_Object_dy_Rear 0;
BA_ "GenSigTimeoutValue" SG_ 799 SGU30_Object_dy_Rear 0;
BA_ "Remark" SG_ 799 SGU30_Object_dy_Rear "";
BA_ "EventCommandSignal" SG_ 799 SGU30_Object_vx 0;
BA_ "GatewayedSignals" SG_ 799 SGU30_Object_vx 0;
BA_ "GenSigInactiveValue" SG_ 799 SGU30_Object_vx 0;
BA_ "GenSigInvalidValue" SG_ 799 SGU30_Object_vx 0;
BA_ "GenSigSendType" SG_ 799 SGU30_Object_vx 1;
BA_ "GenSigStartValue" SG_ 799 SGU30_Object_vx 0;
BA_ "GenSigTimeoutValue" SG_ 799 SGU30_Object_vx 0;
BA_ "Remark" SG_ 799 SGU30_Object_vx "";
BA_ "EventCommandSignal" SG_ 799 SGU30_Object_vy 0;
BA_ "GatewayedSignals" SG_ 799 SGU30_Object_vy 0;
BA_ "GenSigInactiveValue" SG_ 799 SGU30_Object_vy 0;
BA_ "GenSigInvalidValue" SG_ 799 SGU30_Object_vy 0;
BA_ "GenSigSendType" SG_ 799 SGU30_Object_vy 1;
BA_ "GenSigStartValue" SG_ 799 SGU30_Object_vy 0;
BA_ "GenSigTimeoutValue" SG_ 799 SGU30_Object_vy 0;
BA_ "Remark" SG_ 799 SGU30_Object_vy "";
BA_ "EventCommandSignal" SG_ 799 SGU30_Object_wExist 0;
BA_ "GatewayedSignals" SG_ 799 SGU30_Object_wExist 0;
BA_ "GenSigInactiveValue" SG_ 799 SGU30_Object_wExist 0;
BA_ "GenSigInvalidValue" SG_ 799 SGU30_Object_wExist 0;
BA_ "GenSigSendType" SG_ 799 SGU30_Object_wExist 1;
BA_ "GenSigStartValue" SG_ 799 SGU30_Object_wExist 0;
BA_ "GenSigTimeoutValue" SG_ 799 SGU30_Object_wExist 0;
BA_ "Remark" SG_ 799 SGU30_Object_wExist "";
BA_ "EventCommandSignal" SG_ 799 SGU30_Object_wObstacle 0;
BA_ "GatewayedSignals" SG_ 799 SGU30_Object_wObstacle 0;
BA_ "GenSigInactiveValue" SG_ 799 SGU30_Object_wObstacle 0;
BA_ "GenSigInvalidValue" SG_ 799 SGU30_Object_wObstacle 0;
BA_ "GenSigSendType" SG_ 799 SGU30_Object_wObstacle 1;
BA_ "GenSigStartValue" SG_ 799 SGU30_Object_wObstacle 0;
BA_ "GenSigTimeoutValue" SG_ 799 SGU30_Object_wObstacle 0;
BA_ "Remark" SG_ 799 SGU30_Object_wObstacle "";
BA_ "EventCommandSignal" SG_ 800 SGU31_BlockCounter 0;
BA_ "GatewayedSignals" SG_ 800 SGU31_BlockCounter 0;
BA_ "GenSigInactiveValue" SG_ 800 SGU31_BlockCounter 0;
BA_ "GenSigInvalidValue" SG_ 800 SGU31_BlockCounter 0;
BA_ "GenSigSendType" SG_ 800 SGU31_BlockCounter 1;
BA_ "GenSigStartValue" SG_ 800 SGU31_BlockCounter 0;
BA_ "GenSigTimeoutValue" SG_ 800 SGU31_BlockCounter 0;
BA_ "Remark" SG_ 800 SGU31_BlockCounter "";
BA_ "EventCommandSignal" SG_ 800 SGU31_LifeCycles_OBJ 0;
BA_ "GatewayedSignals" SG_ 800 SGU31_LifeCycles_OBJ 0;
BA_ "GenSigInactiveValue" SG_ 800 SGU31_LifeCycles_OBJ 0;
BA_ "GenSigInvalidValue" SG_ 800 SGU31_LifeCycles_OBJ 0;
BA_ "GenSigSendType" SG_ 800 SGU31_LifeCycles_OBJ 1;
BA_ "GenSigStartValue" SG_ 800 SGU31_LifeCycles_OBJ 0;
BA_ "GenSigTimeoutValue" SG_ 800 SGU31_LifeCycles_OBJ 0;
BA_ "Remark" SG_ 800 SGU31_LifeCycles_OBJ "";
BA_ "EventCommandSignal" SG_ 800 SGU31_Msg_AliveCounter 0;
BA_ "GatewayedSignals" SG_ 800 SGU31_Msg_AliveCounter 0;
BA_ "GenSigInactiveValue" SG_ 800 SGU31_Msg_AliveCounter 0;
BA_ "GenSigInvalidValue" SG_ 800 SGU31_Msg_AliveCounter 0;
BA_ "GenSigSendType" SG_ 800 SGU31_Msg_AliveCounter 1;
BA_ "GenSigStartValue" SG_ 800 SGU31_Msg_AliveCounter 0;
BA_ "GenSigTimeoutValue" SG_ 800 SGU31_Msg_AliveCounter 0;
BA_ "Remark" SG_ 800 SGU31_Msg_AliveCounter "";
BA_ "EventCommandSignal" SG_ 800 SGU31_Msg_CheckSum 0;
BA_ "GatewayedSignals" SG_ 800 SGU31_Msg_CheckSum 0;
BA_ "GenSigInactiveValue" SG_ 800 SGU31_Msg_CheckSum 0;
BA_ "GenSigInvalidValue" SG_ 800 SGU31_Msg_CheckSum 0;
BA_ "GenSigSendType" SG_ 800 SGU31_Msg_CheckSum 1;
BA_ "GenSigStartValue" SG_ 800 SGU31_Msg_CheckSum 0;
BA_ "GenSigTimeoutValue" SG_ 800 SGU31_Msg_CheckSum 0;
BA_ "Remark" SG_ 800 SGU31_Msg_CheckSum "";
BA_ "EventCommandSignal" SG_ 800 SGU31_ObjRCS_31 0;
BA_ "GatewayedSignals" SG_ 800 SGU31_ObjRCS_31 0;
BA_ "GenSigInactiveValue" SG_ 800 SGU31_ObjRCS_31 0;
BA_ "GenSigInvalidValue" SG_ 800 SGU31_ObjRCS_31 0;
BA_ "GenSigSendType" SG_ 800 SGU31_ObjRCS_31 1;
BA_ "GenSigStartValue" SG_ 800 SGU31_ObjRCS_31 0;
BA_ "GenSigTimeoutValue" SG_ 800 SGU31_ObjRCS_31 0;
BA_ "Remark" SG_ 800 SGU31_ObjRCS_31 "";
BA_ "EventCommandSignal" SG_ 800 SGU31_Obj_DistLat_rms 0;
BA_ "GatewayedSignals" SG_ 800 SGU31_Obj_DistLat_rms 0;
BA_ "GenSigInactiveValue" SG_ 800 SGU31_Obj_DistLat_rms 0;
BA_ "GenSigInvalidValue" SG_ 800 SGU31_Obj_DistLat_rms 0;
BA_ "GenSigSendType" SG_ 800 SGU31_Obj_DistLat_rms 1;
BA_ "GenSigStartValue" SG_ 800 SGU31_Obj_DistLat_rms 0;
BA_ "GenSigTimeoutValue" SG_ 800 SGU31_Obj_DistLat_rms 0;
BA_ "Remark" SG_ 800 SGU31_Obj_DistLat_rms "";
BA_ "EventCommandSignal" SG_ 800 SGU31_Obj_VrelLong_rms 0;
BA_ "GatewayedSignals" SG_ 800 SGU31_Obj_VrelLong_rms 0;
BA_ "GenSigInactiveValue" SG_ 800 SGU31_Obj_VrelLong_rms 0;
BA_ "GenSigInvalidValue" SG_ 800 SGU31_Obj_VrelLong_rms 0;
BA_ "GenSigSendType" SG_ 800 SGU31_Obj_VrelLong_rms 1;
BA_ "GenSigStartValue" SG_ 800 SGU31_Obj_VrelLong_rms 0;
BA_ "GenSigTimeoutValue" SG_ 800 SGU31_Obj_VrelLong_rms 0;
BA_ "Remark" SG_ 800 SGU31_Obj_VrelLong_rms "";
BA_ "EventCommandSignal" SG_ 800 SGU31_Obj_Vrelat_rms 0;
BA_ "GatewayedSignals" SG_ 800 SGU31_Obj_Vrelat_rms 0;
BA_ "GenSigInactiveValue" SG_ 800 SGU31_Obj_Vrelat_rms 0;
BA_ "GenSigInvalidValue" SG_ 800 SGU31_Obj_Vrelat_rms 0;
BA_ "GenSigSendType" SG_ 800 SGU31_Obj_Vrelat_rms 1;
BA_ "GenSigStartValue" SG_ 800 SGU31_Obj_Vrelat_rms 0;
BA_ "GenSigTimeoutValue" SG_ 800 SGU31_Obj_Vrelat_rms 0;
BA_ "Remark" SG_ 800 SGU31_Obj_Vrelat_rms "";
BA_ "EventCommandSignal" SG_ 800 SGU31_Object_DetStatus 0;
BA_ "GatewayedSignals" SG_ 800 SGU31_Object_DetStatus 0;
BA_ "GenSigInactiveValue" SG_ 800 SGU31_Object_DetStatus 0;
BA_ "GenSigInvalidValue" SG_ 800 SGU31_Object_DetStatus 0;
BA_ "GenSigSendType" SG_ 800 SGU31_Object_DetStatus 1;
BA_ "GenSigStartValue" SG_ 800 SGU31_Object_DetStatus 0;
BA_ "GenSigTimeoutValue" SG_ 800 SGU31_Object_DetStatus 0;
BA_ "Remark" SG_ 800 SGU31_Object_DetStatus "";
BA_ "EventCommandSignal" SG_ 800 SGU31_Object_DistLong_rms 0;
BA_ "GatewayedSignals" SG_ 800 SGU31_Object_DistLong_rms 0;
BA_ "GenSigInactiveValue" SG_ 800 SGU31_Object_DistLong_rms 0;
BA_ "GenSigInvalidValue" SG_ 800 SGU31_Object_DistLong_rms 0;
BA_ "GenSigSendType" SG_ 800 SGU31_Object_DistLong_rms 1;
BA_ "GenSigStartValue" SG_ 800 SGU31_Object_DistLong_rms 0;
BA_ "GenSigTimeoutValue" SG_ 800 SGU31_Object_DistLong_rms 0;
BA_ "Remark" SG_ 800 SGU31_Object_DistLong_rms "";
BA_ "EventCommandSignal" SG_ 800 SGU31_Object_ID 0;
BA_ "GatewayedSignals" SG_ 800 SGU31_Object_ID 0;
BA_ "GenSigInactiveValue" SG_ 800 SGU31_Object_ID 0;
BA_ "GenSigInvalidValue" SG_ 800 SGU31_Object_ID 0;
BA_ "GenSigSendType" SG_ 800 SGU31_Object_ID 1;
BA_ "GenSigStartValue" SG_ 800 SGU31_Object_ID 0;
BA_ "GenSigTimeoutValue" SG_ 800 SGU31_Object_ID 0;
BA_ "Remark" SG_ 800 SGU31_Object_ID "";
BA_ "EventCommandSignal" SG_ 800 SGU31_Object_Motion_Pattern 0;
BA_ "GatewayedSignals" SG_ 800 SGU31_Object_Motion_Pattern 0;
BA_ "GenSigInactiveValue" SG_ 800 SGU31_Object_Motion_Pattern 0;
BA_ "GenSigInvalidValue" SG_ 800 SGU31_Object_Motion_Pattern 0;
BA_ "GenSigSendType" SG_ 800 SGU31_Object_Motion_Pattern 1;
BA_ "GenSigStartValue" SG_ 800 SGU31_Object_Motion_Pattern 0;
BA_ "GenSigTimeoutValue" SG_ 800 SGU31_Object_Motion_Pattern 0;
BA_ "Remark" SG_ 800 SGU31_Object_Motion_Pattern "";
BA_ "EventCommandSignal" SG_ 800 SGU31_Object_Type 0;
BA_ "GatewayedSignals" SG_ 800 SGU31_Object_Type 0;
BA_ "GenSigInactiveValue" SG_ 800 SGU31_Object_Type 0;
BA_ "GenSigInvalidValue" SG_ 800 SGU31_Object_Type 0;
BA_ "GenSigSendType" SG_ 800 SGU31_Object_Type 1;
BA_ "GenSigStartValue" SG_ 800 SGU31_Object_Type 0;
BA_ "GenSigTimeoutValue" SG_ 800 SGU31_Object_Type 0;
BA_ "Remark" SG_ 800 SGU31_Object_Type "";
BA_ "EventCommandSignal" SG_ 800 SGU31_Object_ax 0;
BA_ "GatewayedSignals" SG_ 800 SGU31_Object_ax 0;
BA_ "GenSigInactiveValue" SG_ 800 SGU31_Object_ax 0;
BA_ "GenSigInvalidValue" SG_ 800 SGU31_Object_ax 0;
BA_ "GenSigSendType" SG_ 800 SGU31_Object_ax 1;
BA_ "GenSigStartValue" SG_ 800 SGU31_Object_ax 0;
BA_ "GenSigTimeoutValue" SG_ 800 SGU31_Object_ax 0;
BA_ "Remark" SG_ 800 SGU31_Object_ax "";
BA_ "EventCommandSignal" SG_ 800 SGU31_Object_ay 0;
BA_ "GatewayedSignals" SG_ 800 SGU31_Object_ay 0;
BA_ "GenSigInactiveValue" SG_ 800 SGU31_Object_ay 0;
BA_ "GenSigInvalidValue" SG_ 800 SGU31_Object_ay 0;
BA_ "GenSigSendType" SG_ 800 SGU31_Object_ay 1;
BA_ "GenSigStartValue" SG_ 800 SGU31_Object_ay 0;
BA_ "GenSigTimeoutValue" SG_ 800 SGU31_Object_ay 0;
BA_ "Remark" SG_ 800 SGU31_Object_ay "";
BA_ "EventCommandSignal" SG_ 800 SGU31_Object_dx 0;
BA_ "GatewayedSignals" SG_ 800 SGU31_Object_dx 0;
BA_ "GenSigInactiveValue" SG_ 800 SGU31_Object_dx 0;
BA_ "GenSigInvalidValue" SG_ 800 SGU31_Object_dx 0;
BA_ "GenSigSendType" SG_ 800 SGU31_Object_dx 1;
BA_ "GenSigStartValue" SG_ 800 SGU31_Object_dx 0;
BA_ "GenSigTimeoutValue" SG_ 800 SGU31_Object_dx 0;
BA_ "Remark" SG_ 800 SGU31_Object_dx "";
BA_ "EventCommandSignal" SG_ 800 SGU31_Object_dx_Rear 0;
BA_ "GatewayedSignals" SG_ 800 SGU31_Object_dx_Rear 0;
BA_ "GenSigInactiveValue" SG_ 800 SGU31_Object_dx_Rear 0;
BA_ "GenSigInvalidValue" SG_ 800 SGU31_Object_dx_Rear 0;
BA_ "GenSigSendType" SG_ 800 SGU31_Object_dx_Rear 1;
BA_ "GenSigStartValue" SG_ 800 SGU31_Object_dx_Rear 0;
BA_ "GenSigTimeoutValue" SG_ 800 SGU31_Object_dx_Rear 0;
BA_ "Remark" SG_ 800 SGU31_Object_dx_Rear "";
BA_ "EventCommandSignal" SG_ 800 SGU31_Object_dy 0;
BA_ "GatewayedSignals" SG_ 800 SGU31_Object_dy 0;
BA_ "GenSigInactiveValue" SG_ 800 SGU31_Object_dy 0;
BA_ "GenSigInvalidValue" SG_ 800 SGU31_Object_dy 0;
BA_ "GenSigSendType" SG_ 800 SGU31_Object_dy 1;
BA_ "GenSigStartValue" SG_ 800 SGU31_Object_dy 0;
BA_ "GenSigTimeoutValue" SG_ 800 SGU31_Object_dy 0;
BA_ "Remark" SG_ 800 SGU31_Object_dy "";
BA_ "EventCommandSignal" SG_ 800 SGU31_Object_dy_Rear 0;
BA_ "GatewayedSignals" SG_ 800 SGU31_Object_dy_Rear 0;
BA_ "GenSigInactiveValue" SG_ 800 SGU31_Object_dy_Rear 0;
BA_ "GenSigInvalidValue" SG_ 800 SGU31_Object_dy_Rear 0;
BA_ "GenSigSendType" SG_ 800 SGU31_Object_dy_Rear 1;
BA_ "GenSigStartValue" SG_ 800 SGU31_Object_dy_Rear 0;
BA_ "GenSigTimeoutValue" SG_ 800 SGU31_Object_dy_Rear 0;
BA_ "Remark" SG_ 800 SGU31_Object_dy_Rear "";
BA_ "EventCommandSignal" SG_ 800 SGU31_Object_vx 0;
BA_ "GatewayedSignals" SG_ 800 SGU31_Object_vx 0;
BA_ "GenSigInactiveValue" SG_ 800 SGU31_Object_vx 0;
BA_ "GenSigInvalidValue" SG_ 800 SGU31_Object_vx 0;
BA_ "GenSigSendType" SG_ 800 SGU31_Object_vx 1;
BA_ "GenSigStartValue" SG_ 800 SGU31_Object_vx 0;
BA_ "GenSigTimeoutValue" SG_ 800 SGU31_Object_vx 0;
BA_ "Remark" SG_ 800 SGU31_Object_vx "";
BA_ "EventCommandSignal" SG_ 800 SGU31_Object_vy 0;
BA_ "GatewayedSignals" SG_ 800 SGU31_Object_vy 0;
BA_ "GenSigInactiveValue" SG_ 800 SGU31_Object_vy 0;
BA_ "GenSigInvalidValue" SG_ 800 SGU31_Object_vy 0;
BA_ "GenSigSendType" SG_ 800 SGU31_Object_vy 1;
BA_ "GenSigStartValue" SG_ 800 SGU31_Object_vy 0;
BA_ "GenSigTimeoutValue" SG_ 800 SGU31_Object_vy 0;
BA_ "Remark" SG_ 800 SGU31_Object_vy "";
BA_ "EventCommandSignal" SG_ 800 SGU31_Object_wExist 0;
BA_ "GatewayedSignals" SG_ 800 SGU31_Object_wExist 0;
BA_ "GenSigInactiveValue" SG_ 800 SGU31_Object_wExist 0;
BA_ "GenSigInvalidValue" SG_ 800 SGU31_Object_wExist 0;
BA_ "GenSigSendType" SG_ 800 SGU31_Object_wExist 1;
BA_ "GenSigStartValue" SG_ 800 SGU31_Object_wExist 0;
BA_ "GenSigTimeoutValue" SG_ 800 SGU31_Object_wExist 0;
BA_ "Remark" SG_ 800 SGU31_Object_wExist "";
BA_ "EventCommandSignal" SG_ 800 SGU31_Object_wObstacle 0;
BA_ "GatewayedSignals" SG_ 800 SGU31_Object_wObstacle 0;
BA_ "GenSigInactiveValue" SG_ 800 SGU31_Object_wObstacle 0;
BA_ "GenSigInvalidValue" SG_ 800 SGU31_Object_wObstacle 0;
BA_ "GenSigSendType" SG_ 800 SGU31_Object_wObstacle 1;
BA_ "GenSigStartValue" SG_ 800 SGU31_Object_wObstacle 0;
BA_ "GenSigTimeoutValue" SG_ 800 SGU31_Object_wObstacle 0;
BA_ "Remark" SG_ 800 SGU31_Object_wObstacle "";
BA_ "EventCommandSignal" SG_ 801 SGU32_BlockCounter 0;
BA_ "GatewayedSignals" SG_ 801 SGU32_BlockCounter 0;
BA_ "GenSigInactiveValue" SG_ 801 SGU32_BlockCounter 0;
BA_ "GenSigInvalidValue" SG_ 801 SGU32_BlockCounter 0;
BA_ "GenSigSendType" SG_ 801 SGU32_BlockCounter 1;
BA_ "GenSigStartValue" SG_ 801 SGU32_BlockCounter 0;
BA_ "GenSigTimeoutValue" SG_ 801 SGU32_BlockCounter 0;
BA_ "Remark" SG_ 801 SGU32_BlockCounter "";
BA_ "EventCommandSignal" SG_ 801 SGU32_LifeCycles_OBJ 0;
BA_ "GatewayedSignals" SG_ 801 SGU32_LifeCycles_OBJ 0;
BA_ "GenSigInactiveValue" SG_ 801 SGU32_LifeCycles_OBJ 0;
BA_ "GenSigInvalidValue" SG_ 801 SGU32_LifeCycles_OBJ 0;
BA_ "GenSigSendType" SG_ 801 SGU32_LifeCycles_OBJ 1;
BA_ "GenSigStartValue" SG_ 801 SGU32_LifeCycles_OBJ 0;
BA_ "GenSigTimeoutValue" SG_ 801 SGU32_LifeCycles_OBJ 0;
BA_ "Remark" SG_ 801 SGU32_LifeCycles_OBJ "";
BA_ "EventCommandSignal" SG_ 801 SGU32_Msg_AliveCounter 0;
BA_ "GatewayedSignals" SG_ 801 SGU32_Msg_AliveCounter 0;
BA_ "GenSigInactiveValue" SG_ 801 SGU32_Msg_AliveCounter 0;
BA_ "GenSigInvalidValue" SG_ 801 SGU32_Msg_AliveCounter 0;
BA_ "GenSigSendType" SG_ 801 SGU32_Msg_AliveCounter 1;
BA_ "GenSigStartValue" SG_ 801 SGU32_Msg_AliveCounter 0;
BA_ "GenSigTimeoutValue" SG_ 801 SGU32_Msg_AliveCounter 0;
BA_ "Remark" SG_ 801 SGU32_Msg_AliveCounter "";
BA_ "EventCommandSignal" SG_ 801 SGU32_Msg_CheckSum 0;
BA_ "GatewayedSignals" SG_ 801 SGU32_Msg_CheckSum 0;
BA_ "GenSigInactiveValue" SG_ 801 SGU32_Msg_CheckSum 0;
BA_ "GenSigInvalidValue" SG_ 801 SGU32_Msg_CheckSum 0;
BA_ "GenSigSendType" SG_ 801 SGU32_Msg_CheckSum 1;
BA_ "GenSigStartValue" SG_ 801 SGU32_Msg_CheckSum 0;
BA_ "GenSigTimeoutValue" SG_ 801 SGU32_Msg_CheckSum 0;
BA_ "Remark" SG_ 801 SGU32_Msg_CheckSum "";
BA_ "EventCommandSignal" SG_ 801 SGU32_ObjRCS_32 0;
BA_ "GatewayedSignals" SG_ 801 SGU32_ObjRCS_32 0;
BA_ "GenSigInactiveValue" SG_ 801 SGU32_ObjRCS_32 0;
BA_ "GenSigInvalidValue" SG_ 801 SGU32_ObjRCS_32 0;
BA_ "GenSigSendType" SG_ 801 SGU32_ObjRCS_32 1;
BA_ "GenSigStartValue" SG_ 801 SGU32_ObjRCS_32 0;
BA_ "GenSigTimeoutValue" SG_ 801 SGU32_ObjRCS_32 0;
BA_ "Remark" SG_ 801 SGU32_ObjRCS_32 "";
BA_ "EventCommandSignal" SG_ 801 SGU32_Obj_DistLat_rms 0;
BA_ "GatewayedSignals" SG_ 801 SGU32_Obj_DistLat_rms 0;
BA_ "GenSigInactiveValue" SG_ 801 SGU32_Obj_DistLat_rms 0;
BA_ "GenSigInvalidValue" SG_ 801 SGU32_Obj_DistLat_rms 0;
BA_ "GenSigSendType" SG_ 801 SGU32_Obj_DistLat_rms 1;
BA_ "GenSigStartValue" SG_ 801 SGU32_Obj_DistLat_rms 0;
BA_ "GenSigTimeoutValue" SG_ 801 SGU32_Obj_DistLat_rms 0;
BA_ "Remark" SG_ 801 SGU32_Obj_DistLat_rms "";
BA_ "EventCommandSignal" SG_ 801 SGU32_Obj_VrelLong_rms 0;
BA_ "GatewayedSignals" SG_ 801 SGU32_Obj_VrelLong_rms 0;
BA_ "GenSigInactiveValue" SG_ 801 SGU32_Obj_VrelLong_rms 0;
BA_ "GenSigInvalidValue" SG_ 801 SGU32_Obj_VrelLong_rms 0;
BA_ "GenSigSendType" SG_ 801 SGU32_Obj_VrelLong_rms 1;
BA_ "GenSigStartValue" SG_ 801 SGU32_Obj_VrelLong_rms 0;
BA_ "GenSigTimeoutValue" SG_ 801 SGU32_Obj_VrelLong_rms 0;
BA_ "Remark" SG_ 801 SGU32_Obj_VrelLong_rms "";
BA_ "EventCommandSignal" SG_ 801 SGU32_Obj_Vrelat_rms 0;
BA_ "GatewayedSignals" SG_ 801 SGU32_Obj_Vrelat_rms 0;
BA_ "GenSigInactiveValue" SG_ 801 SGU32_Obj_Vrelat_rms 0;
BA_ "GenSigInvalidValue" SG_ 801 SGU32_Obj_Vrelat_rms 0;
BA_ "GenSigSendType" SG_ 801 SGU32_Obj_Vrelat_rms 1;
BA_ "GenSigStartValue" SG_ 801 SGU32_Obj_Vrelat_rms 0;
BA_ "GenSigTimeoutValue" SG_ 801 SGU32_Obj_Vrelat_rms 0;
BA_ "Remark" SG_ 801 SGU32_Obj_Vrelat_rms "";
BA_ "EventCommandSignal" SG_ 801 SGU32_Object_DetStatus 0;
BA_ "GatewayedSignals" SG_ 801 SGU32_Object_DetStatus 0;
BA_ "GenSigInactiveValue" SG_ 801 SGU32_Object_DetStatus 0;
BA_ "GenSigInvalidValue" SG_ 801 SGU32_Object_DetStatus 0;
BA_ "GenSigSendType" SG_ 801 SGU32_Object_DetStatus 1;
BA_ "GenSigStartValue" SG_ 801 SGU32_Object_DetStatus 0;
BA_ "GenSigTimeoutValue" SG_ 801 SGU32_Object_DetStatus 0;
BA_ "Remark" SG_ 801 SGU32_Object_DetStatus "";
BA_ "EventCommandSignal" SG_ 801 SGU32_Object_DistLong_rms 0;
BA_ "GatewayedSignals" SG_ 801 SGU32_Object_DistLong_rms 0;
BA_ "GenSigInactiveValue" SG_ 801 SGU32_Object_DistLong_rms 0;
BA_ "GenSigInvalidValue" SG_ 801 SGU32_Object_DistLong_rms 0;
BA_ "GenSigSendType" SG_ 801 SGU32_Object_DistLong_rms 1;
BA_ "GenSigStartValue" SG_ 801 SGU32_Object_DistLong_rms 0;
BA_ "GenSigTimeoutValue" SG_ 801 SGU32_Object_DistLong_rms 0;
BA_ "Remark" SG_ 801 SGU32_Object_DistLong_rms "";
BA_ "EventCommandSignal" SG_ 801 SGU32_Object_ID 0;
BA_ "GatewayedSignals" SG_ 801 SGU32_Object_ID 0;
BA_ "GenSigInactiveValue" SG_ 801 SGU32_Object_ID 0;
BA_ "GenSigInvalidValue" SG_ 801 SGU32_Object_ID 0;
BA_ "GenSigSendType" SG_ 801 SGU32_Object_ID 1;
BA_ "GenSigStartValue" SG_ 801 SGU32_Object_ID 0;
BA_ "GenSigTimeoutValue" SG_ 801 SGU32_Object_ID 0;
BA_ "Remark" SG_ 801 SGU32_Object_ID "";
BA_ "EventCommandSignal" SG_ 801 SGU32_Object_Motion_Pattern 0;
BA_ "GatewayedSignals" SG_ 801 SGU32_Object_Motion_Pattern 0;
BA_ "GenSigInactiveValue" SG_ 801 SGU32_Object_Motion_Pattern 0;
BA_ "GenSigInvalidValue" SG_ 801 SGU32_Object_Motion_Pattern 0;
BA_ "GenSigSendType" SG_ 801 SGU32_Object_Motion_Pattern 1;
BA_ "GenSigStartValue" SG_ 801 SGU32_Object_Motion_Pattern 0;
BA_ "GenSigTimeoutValue" SG_ 801 SGU32_Object_Motion_Pattern 0;
BA_ "Remark" SG_ 801 SGU32_Object_Motion_Pattern "";
BA_ "EventCommandSignal" SG_ 801 SGU32_Object_Type 0;
BA_ "GatewayedSignals" SG_ 801 SGU32_Object_Type 0;
BA_ "GenSigInactiveValue" SG_ 801 SGU32_Object_Type 0;
BA_ "GenSigInvalidValue" SG_ 801 SGU32_Object_Type 0;
BA_ "GenSigSendType" SG_ 801 SGU32_Object_Type 1;
BA_ "GenSigStartValue" SG_ 801 SGU32_Object_Type 0;
BA_ "GenSigTimeoutValue" SG_ 801 SGU32_Object_Type 0;
BA_ "Remark" SG_ 801 SGU32_Object_Type "";
BA_ "EventCommandSignal" SG_ 801 SGU32_Object_ax 0;
BA_ "GatewayedSignals" SG_ 801 SGU32_Object_ax 0;
BA_ "GenSigInactiveValue" SG_ 801 SGU32_Object_ax 0;
BA_ "GenSigInvalidValue" SG_ 801 SGU32_Object_ax 0;
BA_ "GenSigSendType" SG_ 801 SGU32_Object_ax 1;
BA_ "GenSigStartValue" SG_ 801 SGU32_Object_ax 0;
BA_ "GenSigTimeoutValue" SG_ 801 SGU32_Object_ax 0;
BA_ "Remark" SG_ 801 SGU32_Object_ax "";
BA_ "EventCommandSignal" SG_ 801 SGU32_Object_ay 0;
BA_ "GatewayedSignals" SG_ 801 SGU32_Object_ay 0;
BA_ "GenSigInactiveValue" SG_ 801 SGU32_Object_ay 0;
BA_ "GenSigInvalidValue" SG_ 801 SGU32_Object_ay 0;
BA_ "GenSigSendType" SG_ 801 SGU32_Object_ay 1;
BA_ "GenSigStartValue" SG_ 801 SGU32_Object_ay 0;
BA_ "GenSigTimeoutValue" SG_ 801 SGU32_Object_ay 0;
BA_ "Remark" SG_ 801 SGU32_Object_ay "";
BA_ "EventCommandSignal" SG_ 801 SGU32_Object_dx 0;
BA_ "GatewayedSignals" SG_ 801 SGU32_Object_dx 0;
BA_ "GenSigInactiveValue" SG_ 801 SGU32_Object_dx 0;
BA_ "GenSigInvalidValue" SG_ 801 SGU32_Object_dx 0;
BA_ "GenSigSendType" SG_ 801 SGU32_Object_dx 1;
BA_ "GenSigStartValue" SG_ 801 SGU32_Object_dx 0;
BA_ "GenSigTimeoutValue" SG_ 801 SGU32_Object_dx 0;
BA_ "Remark" SG_ 801 SGU32_Object_dx "";
BA_ "EventCommandSignal" SG_ 801 SGU32_Object_dx_Rear 0;
BA_ "GatewayedSignals" SG_ 801 SGU32_Object_dx_Rear 0;
BA_ "GenSigInactiveValue" SG_ 801 SGU32_Object_dx_Rear 0;
BA_ "GenSigInvalidValue" SG_ 801 SGU32_Object_dx_Rear 0;
BA_ "GenSigSendType" SG_ 801 SGU32_Object_dx_Rear 1;
BA_ "GenSigStartValue" SG_ 801 SGU32_Object_dx_Rear 0;
BA_ "GenSigTimeoutValue" SG_ 801 SGU32_Object_dx_Rear 0;
BA_ "Remark" SG_ 801 SGU32_Object_dx_Rear "";
BA_ "EventCommandSignal" SG_ 801 SGU32_Object_dy 0;
BA_ "GatewayedSignals" SG_ 801 SGU32_Object_dy 0;
BA_ "GenSigInactiveValue" SG_ 801 SGU32_Object_dy 0;
BA_ "GenSigInvalidValue" SG_ 801 SGU32_Object_dy 0;
BA_ "GenSigSendType" SG_ 801 SGU32_Object_dy 1;
BA_ "GenSigStartValue" SG_ 801 SGU32_Object_dy 0;
BA_ "GenSigTimeoutValue" SG_ 801 SGU32_Object_dy 0;
BA_ "Remark" SG_ 801 SGU32_Object_dy "";
BA_ "EventCommandSignal" SG_ 801 SGU32_Object_dy_Rear 0;
BA_ "GatewayedSignals" SG_ 801 SGU32_Object_dy_Rear 0;
BA_ "GenSigInactiveValue" SG_ 801 SGU32_Object_dy_Rear 0;
BA_ "GenSigInvalidValue" SG_ 801 SGU32_Object_dy_Rear 0;
BA_ "GenSigSendType" SG_ 801 SGU32_Object_dy_Rear 1;
BA_ "GenSigStartValue" SG_ 801 SGU32_Object_dy_Rear 0;
BA_ "GenSigTimeoutValue" SG_ 801 SGU32_Object_dy_Rear 0;
BA_ "Remark" SG_ 801 SGU32_Object_dy_Rear "";
BA_ "EventCommandSignal" SG_ 801 SGU32_Object_vx 0;
BA_ "GatewayedSignals" SG_ 801 SGU32_Object_vx 0;
BA_ "GenSigInactiveValue" SG_ 801 SGU32_Object_vx 0;
BA_ "GenSigInvalidValue" SG_ 801 SGU32_Object_vx 0;
BA_ "GenSigSendType" SG_ 801 SGU32_Object_vx 1;
BA_ "GenSigStartValue" SG_ 801 SGU32_Object_vx 0;
BA_ "GenSigTimeoutValue" SG_ 801 SGU32_Object_vx 0;
BA_ "Remark" SG_ 801 SGU32_Object_vx "";
BA_ "EventCommandSignal" SG_ 801 SGU32_Object_vy 0;
BA_ "GatewayedSignals" SG_ 801 SGU32_Object_vy 0;
BA_ "GenSigInactiveValue" SG_ 801 SGU32_Object_vy 0;
BA_ "GenSigInvalidValue" SG_ 801 SGU32_Object_vy 0;
BA_ "GenSigSendType" SG_ 801 SGU32_Object_vy 1;
BA_ "GenSigStartValue" SG_ 801 SGU32_Object_vy 0;
BA_ "GenSigTimeoutValue" SG_ 801 SGU32_Object_vy 0;
BA_ "Remark" SG_ 801 SGU32_Object_vy "";
BA_ "EventCommandSignal" SG_ 801 SGU32_Object_wExist 0;
BA_ "GatewayedSignals" SG_ 801 SGU32_Object_wExist 0;
BA_ "GenSigInactiveValue" SG_ 801 SGU32_Object_wExist 0;
BA_ "GenSigInvalidValue" SG_ 801 SGU32_Object_wExist 0;
BA_ "GenSigSendType" SG_ 801 SGU32_Object_wExist 1;
BA_ "GenSigStartValue" SG_ 801 SGU32_Object_wExist 0;
BA_ "GenSigTimeoutValue" SG_ 801 SGU32_Object_wExist 0;
BA_ "Remark" SG_ 801 SGU32_Object_wExist "";
BA_ "EventCommandSignal" SG_ 801 SGU32_Object_wObstacle 0;
BA_ "GatewayedSignals" SG_ 801 SGU32_Object_wObstacle 0;
BA_ "GenSigInactiveValue" SG_ 801 SGU32_Object_wObstacle 0;
BA_ "GenSigInvalidValue" SG_ 801 SGU32_Object_wObstacle 0;
BA_ "GenSigSendType" SG_ 801 SGU32_Object_wObstacle 1;
BA_ "GenSigStartValue" SG_ 801 SGU32_Object_wObstacle 0;
BA_ "GenSigTimeoutValue" SG_ 801 SGU32_Object_wObstacle 0;
BA_ "Remark" SG_ 801 SGU32_Object_wObstacle "";
BA_ "EventCommandSignal" SG_ 802 AngleEMEIndicatorAz 0;
BA_ "GatewayedSignals" SG_ 802 AngleEMEIndicatorAz 0;
BA_ "GenSigInactiveValue" SG_ 802 AngleEMEIndicatorAz 0;
BA_ "GenSigInvalidValue" SG_ 802 AngleEMEIndicatorAz 0;
BA_ "GenSigSendType" SG_ 802 AngleEMEIndicatorAz 1;
BA_ "GenSigStartValue" SG_ 802 AngleEMEIndicatorAz 0;
BA_ "GenSigTimeoutValue" SG_ 802 AngleEMEIndicatorAz 0;
BA_ "Remark" SG_ 802 AngleEMEIndicatorAz "";
BA_ "EventCommandSignal" SG_ 802 AngleEMEIndicatorEl 0;
BA_ "GatewayedSignals" SG_ 802 AngleEMEIndicatorEl 0;
BA_ "GenSigInactiveValue" SG_ 802 AngleEMEIndicatorEl 0;
BA_ "GenSigInvalidValue" SG_ 802 AngleEMEIndicatorEl 0;
BA_ "GenSigSendType" SG_ 802 AngleEMEIndicatorEl 1;
BA_ "GenSigStartValue" SG_ 802 AngleEMEIndicatorEl 0;
BA_ "GenSigTimeoutValue" SG_ 802 AngleEMEIndicatorEl 0;
BA_ "Remark" SG_ 802 AngleEMEIndicatorEl "";
BA_ "EventCommandSignal" SG_ 802 FRR_Blindness_FaultSts 0;
BA_ "GatewayedSignals" SG_ 802 FRR_Blindness_FaultSts 0;
BA_ "GenSigInactiveValue" SG_ 802 FRR_Blindness_FaultSts 0;
BA_ "GenSigInvalidValue" SG_ 802 FRR_Blindness_FaultSts 0;
BA_ "GenSigSendType" SG_ 802 FRR_Blindness_FaultSts 1;
BA_ "GenSigStartValue" SG_ 802 FRR_Blindness_FaultSts 0;
BA_ "GenSigTimeoutValue" SG_ 802 FRR_Blindness_FaultSts 0;
BA_ "Remark" SG_ 802 FRR_Blindness_FaultSts "";
BA_ "EventCommandSignal" SG_ 802 FRR_DTC_ALIGNMENT_NOT_DONE 0;
BA_ "GatewayedSignals" SG_ 802 FRR_DTC_ALIGNMENT_NOT_DONE 0;
BA_ "GenSigInactiveValue" SG_ 802 FRR_DTC_ALIGNMENT_NOT_DONE 0;
BA_ "GenSigInvalidValue" SG_ 802 FRR_DTC_ALIGNMENT_NOT_DONE 0;
BA_ "GenSigSendType" SG_ 802 FRR_DTC_ALIGNMENT_NOT_DONE 1;
BA_ "GenSigStartValue" SG_ 802 FRR_DTC_ALIGNMENT_NOT_DONE 0;
BA_ "GenSigTimeoutValue" SG_ 802 FRR_DTC_ALIGNMENT_NOT_DONE 0;
BA_ "Remark" SG_ 802 FRR_DTC_ALIGNMENT_NOT_DONE "";
BA_ "EventCommandSignal" SG_ 802 FRR_DTC_CORNER_RADAR_BLIND 0;
BA_ "GatewayedSignals" SG_ 802 FRR_DTC_CORNER_RADAR_BLIND 0;
BA_ "GenSigInactiveValue" SG_ 802 FRR_DTC_CORNER_RADAR_BLIND 0;
BA_ "GenSigInvalidValue" SG_ 802 FRR_DTC_CORNER_RADAR_BLIND 0;
BA_ "GenSigSendType" SG_ 802 FRR_DTC_CORNER_RADAR_BLIND 1;
BA_ "GenSigStartValue" SG_ 802 FRR_DTC_CORNER_RADAR_BLIND 0;
BA_ "GenSigTimeoutValue" SG_ 802 FRR_DTC_CORNER_RADAR_BLIND 0;
BA_ "Remark" SG_ 802 FRR_DTC_CORNER_RADAR_BLIND "";
BA_ "EventCommandSignal" SG_ 802 FRR_DTC_CORNER_RADAR_MISALIGNED 0;
BA_ "GatewayedSignals" SG_ 802 FRR_DTC_CORNER_RADAR_MISALIGNED 0;
BA_ "GenSigInactiveValue" SG_ 802 FRR_DTC_CORNER_RADAR_MISALIGNED 0;
BA_ "GenSigInvalidValue" SG_ 802 FRR_DTC_CORNER_RADAR_MISALIGNED 0;
BA_ "GenSigSendType" SG_ 802 FRR_DTC_CORNER_RADAR_MISALIGNED 1;
BA_ "GenSigStartValue" SG_ 802 FRR_DTC_CORNER_RADAR_MISALIGNED 0;
BA_ "GenSigTimeoutValue" SG_ 802 FRR_DTC_CORNER_RADAR_MISALIGNED 0;
BA_ "Remark" SG_ 802 FRR_DTC_CORNER_RADAR_MISALIGNED "";
BA_ "EventCommandSignal" SG_ 802 FRR_DTC_DACORE_OOS 0;
BA_ "GatewayedSignals" SG_ 802 FRR_DTC_DACORE_OOS 0;
BA_ "GenSigInactiveValue" SG_ 802 FRR_DTC_DACORE_OOS 0;
BA_ "GenSigInvalidValue" SG_ 802 FRR_DTC_DACORE_OOS 0;
BA_ "GenSigSendType" SG_ 802 FRR_DTC_DACORE_OOS 1;
BA_ "GenSigStartValue" SG_ 802 FRR_DTC_DACORE_OOS 0;
BA_ "GenSigTimeoutValue" SG_ 802 FRR_DTC_DACORE_OOS 0;
BA_ "Remark" SG_ 802 FRR_DTC_DACORE_OOS "";
BA_ "EventCommandSignal" SG_ 802 FRR_DTC_DSP_FAILURE 0;
BA_ "GatewayedSignals" SG_ 802 FRR_DTC_DSP_FAILURE 0;
BA_ "GenSigInactiveValue" SG_ 802 FRR_DTC_DSP_FAILURE 0;
BA_ "GenSigInvalidValue" SG_ 802 FRR_DTC_DSP_FAILURE 0;
BA_ "GenSigSendType" SG_ 802 FRR_DTC_DSP_FAILURE 1;
BA_ "GenSigStartValue" SG_ 802 FRR_DTC_DSP_FAILURE 0;
BA_ "GenSigTimeoutValue" SG_ 802 FRR_DTC_DSP_FAILURE 0;
BA_ "Remark" SG_ 802 FRR_DTC_DSP_FAILURE "";
BA_ "EventCommandSignal" SG_ 802 FRR_DTC_HARDWARE_FAILURE 0;
BA_ "GatewayedSignals" SG_ 802 FRR_DTC_HARDWARE_FAILURE 0;
BA_ "GenSigInactiveValue" SG_ 802 FRR_DTC_HARDWARE_FAILURE 0;
BA_ "GenSigInvalidValue" SG_ 802 FRR_DTC_HARDWARE_FAILURE 0;
BA_ "GenSigSendType" SG_ 802 FRR_DTC_HARDWARE_FAILURE 1;
BA_ "GenSigStartValue" SG_ 802 FRR_DTC_HARDWARE_FAILURE 0;
BA_ "GenSigTimeoutValue" SG_ 802 FRR_DTC_HARDWARE_FAILURE 0;
BA_ "Remark" SG_ 802 FRR_DTC_HARDWARE_FAILURE "";
BA_ "EventCommandSignal" SG_ 802 FRR_DTC_INVALID_DATA_BCS 0;
BA_ "GatewayedSignals" SG_ 802 FRR_DTC_INVALID_DATA_BCS 0;
BA_ "GenSigInactiveValue" SG_ 802 FRR_DTC_INVALID_DATA_BCS 0;
BA_ "GenSigInvalidValue" SG_ 802 FRR_DTC_INVALID_DATA_BCS 0;
BA_ "GenSigSendType" SG_ 802 FRR_DTC_INVALID_DATA_BCS 1;
BA_ "GenSigStartValue" SG_ 802 FRR_DTC_INVALID_DATA_BCS 0;
BA_ "GenSigTimeoutValue" SG_ 802 FRR_DTC_INVALID_DATA_BCS 0;
BA_ "Remark" SG_ 802 FRR_DTC_INVALID_DATA_BCS "";
BA_ "EventCommandSignal" SG_ 802 FRR_DTC_INVALID_DATA_EPS 0;
BA_ "GatewayedSignals" SG_ 802 FRR_DTC_INVALID_DATA_EPS 0;
BA_ "GenSigInactiveValue" SG_ 802 FRR_DTC_INVALID_DATA_EPS 0;
BA_ "GenSigInvalidValue" SG_ 802 FRR_DTC_INVALID_DATA_EPS 0;
BA_ "GenSigSendType" SG_ 802 FRR_DTC_INVALID_DATA_EPS 1;
BA_ "GenSigStartValue" SG_ 802 FRR_DTC_INVALID_DATA_EPS 0;
BA_ "GenSigTimeoutValue" SG_ 802 FRR_DTC_INVALID_DATA_EPS 0;
BA_ "Remark" SG_ 802 FRR_DTC_INVALID_DATA_EPS "";
BA_ "EventCommandSignal" SG_ 802 FRR_DTC_INVALID_DATA_SOC 0;
BA_ "GatewayedSignals" SG_ 802 FRR_DTC_INVALID_DATA_SOC 0;
BA_ "GenSigInactiveValue" SG_ 802 FRR_DTC_INVALID_DATA_SOC 0;
BA_ "GenSigInvalidValue" SG_ 802 FRR_DTC_INVALID_DATA_SOC 0;
BA_ "GenSigSendType" SG_ 802 FRR_DTC_INVALID_DATA_SOC 1;
BA_ "GenSigStartValue" SG_ 802 FRR_DTC_INVALID_DATA_SOC 0;
BA_ "GenSigTimeoutValue" SG_ 802 FRR_DTC_INVALID_DATA_SOC 0;
BA_ "Remark" SG_ 802 FRR_DTC_INVALID_DATA_SOC "";
BA_ "EventCommandSignal" SG_ 802 FRR_DTC_LOST_COMM_BCS 0;
BA_ "GatewayedSignals" SG_ 802 FRR_DTC_LOST_COMM_BCS 0;
BA_ "GenSigInactiveValue" SG_ 802 FRR_DTC_LOST_COMM_BCS 0;
BA_ "GenSigInvalidValue" SG_ 802 FRR_DTC_LOST_COMM_BCS 0;
BA_ "GenSigSendType" SG_ 802 FRR_DTC_LOST_COMM_BCS 1;
BA_ "GenSigStartValue" SG_ 802 FRR_DTC_LOST_COMM_BCS 0;
BA_ "GenSigTimeoutValue" SG_ 802 FRR_DTC_LOST_COMM_BCS 0;
BA_ "Remark" SG_ 802 FRR_DTC_LOST_COMM_BCS "";
BA_ "EventCommandSignal" SG_ 802 FRR_DTC_LOST_COMM_EPS 0;
BA_ "GatewayedSignals" SG_ 802 FRR_DTC_LOST_COMM_EPS 0;
BA_ "GenSigInactiveValue" SG_ 802 FRR_DTC_LOST_COMM_EPS 0;
BA_ "GenSigInvalidValue" SG_ 802 FRR_DTC_LOST_COMM_EPS 0;
BA_ "GenSigSendType" SG_ 802 FRR_DTC_LOST_COMM_EPS 1;
BA_ "GenSigStartValue" SG_ 802 FRR_DTC_LOST_COMM_EPS 0;
BA_ "GenSigTimeoutValue" SG_ 802 FRR_DTC_LOST_COMM_EPS 0;
BA_ "Remark" SG_ 802 FRR_DTC_LOST_COMM_EPS "";
BA_ "EventCommandSignal" SG_ 802 FRR_DTC_LOST_COMM_SOC 0;
BA_ "GatewayedSignals" SG_ 802 FRR_DTC_LOST_COMM_SOC 0;
BA_ "GenSigInactiveValue" SG_ 802 FRR_DTC_LOST_COMM_SOC 0;
BA_ "GenSigInvalidValue" SG_ 802 FRR_DTC_LOST_COMM_SOC 0;
BA_ "GenSigSendType" SG_ 802 FRR_DTC_LOST_COMM_SOC 1;
BA_ "GenSigStartValue" SG_ 802 FRR_DTC_LOST_COMM_SOC 0;
BA_ "GenSigTimeoutValue" SG_ 802 FRR_DTC_LOST_COMM_SOC 0;
BA_ "Remark" SG_ 802 FRR_DTC_LOST_COMM_SOC "";
BA_ "EventCommandSignal" SG_ 802 FRR_DTC_PUBLIC_CAN_BUSOFF 0;
BA_ "GatewayedSignals" SG_ 802 FRR_DTC_PUBLIC_CAN_BUSOFF 0;
BA_ "GenSigInactiveValue" SG_ 802 FRR_DTC_PUBLIC_CAN_BUSOFF 0;
BA_ "GenSigInvalidValue" SG_ 802 FRR_DTC_PUBLIC_CAN_BUSOFF 0;
BA_ "GenSigSendType" SG_ 802 FRR_DTC_PUBLIC_CAN_BUSOFF 1;
BA_ "GenSigStartValue" SG_ 802 FRR_DTC_PUBLIC_CAN_BUSOFF 0;
BA_ "GenSigTimeoutValue" SG_ 802 FRR_DTC_PUBLIC_CAN_BUSOFF 0;
BA_ "Remark" SG_ 802 FRR_DTC_PUBLIC_CAN_BUSOFF "";
BA_ "EventCommandSignal" SG_ 802 FRR_DTC_RADAR_OVER_TEMPERATURE 0;
BA_ "GatewayedSignals" SG_ 802 FRR_DTC_RADAR_OVER_TEMPERATURE 0;
BA_ "GenSigInactiveValue" SG_ 802 FRR_DTC_RADAR_OVER_TEMPERATURE 0;
BA_ "GenSigInvalidValue" SG_ 802 FRR_DTC_RADAR_OVER_TEMPERATURE 0;
BA_ "GenSigSendType" SG_ 802 FRR_DTC_RADAR_OVER_TEMPERATURE 1;
BA_ "GenSigStartValue" SG_ 802 FRR_DTC_RADAR_OVER_TEMPERATURE 0;
BA_ "GenSigTimeoutValue" SG_ 802 FRR_DTC_RADAR_OVER_TEMPERATURE 0;
BA_ "Remark" SG_ 802 FRR_DTC_RADAR_OVER_TEMPERATURE "";
BA_ "EventCommandSignal" SG_ 802 FRR_DTC_RADAR_SIDE_MISMATCH 0;
BA_ "GatewayedSignals" SG_ 802 FRR_DTC_RADAR_SIDE_MISMATCH 0;
BA_ "GenSigInactiveValue" SG_ 802 FRR_DTC_RADAR_SIDE_MISMATCH 0;
BA_ "GenSigInvalidValue" SG_ 802 FRR_DTC_RADAR_SIDE_MISMATCH 0;
BA_ "GenSigSendType" SG_ 802 FRR_DTC_RADAR_SIDE_MISMATCH 1;
BA_ "GenSigStartValue" SG_ 802 FRR_DTC_RADAR_SIDE_MISMATCH 0;
BA_ "GenSigTimeoutValue" SG_ 802 FRR_DTC_RADAR_SIDE_MISMATCH 0;
BA_ "Remark" SG_ 802 FRR_DTC_RADAR_SIDE_MISMATCH "";
BA_ "EventCommandSignal" SG_ 802 FRR_DTC_SOC_Time_SYNC_FAIL 0;
BA_ "GatewayedSignals" SG_ 802 FRR_DTC_SOC_Time_SYNC_FAIL 0;
BA_ "GenSigInactiveValue" SG_ 802 FRR_DTC_SOC_Time_SYNC_FAIL 0;
BA_ "GenSigInvalidValue" SG_ 802 FRR_DTC_SOC_Time_SYNC_FAIL 0;
BA_ "GenSigSendType" SG_ 802 FRR_DTC_SOC_Time_SYNC_FAIL 1;
BA_ "GenSigStartValue" SG_ 802 FRR_DTC_SOC_Time_SYNC_FAIL 0;
BA_ "GenSigTimeoutValue" SG_ 802 FRR_DTC_SOC_Time_SYNC_FAIL 0;
BA_ "Remark" SG_ 802 FRR_DTC_SOC_Time_SYNC_FAIL "";
BA_ "EventCommandSignal" SG_ 802 FRR_DTC_VARIANT_SELECTION_NOT_DONE 0;
BA_ "GatewayedSignals" SG_ 802 FRR_DTC_VARIANT_SELECTION_NOT_DONE 0;
BA_ "GenSigInactiveValue" SG_ 802 FRR_DTC_VARIANT_SELECTION_NOT_DONE 0;
BA_ "GenSigInvalidValue" SG_ 802 FRR_DTC_VARIANT_SELECTION_NOT_DONE 0;
BA_ "GenSigSendType" SG_ 802 FRR_DTC_VARIANT_SELECTION_NOT_DONE 1;
BA_ "GenSigStartValue" SG_ 802 FRR_DTC_VARIANT_SELECTION_NOT_DONE 0;
BA_ "GenSigTimeoutValue" SG_ 802 FRR_DTC_VARIANT_SELECTION_NOT_DONE 0;
BA_ "Remark" SG_ 802 FRR_DTC_VARIANT_SELECTION_NOT_DONE "";
BA_ "EventCommandSignal" SG_ 802 FRR_DTC_VBAT_HIGH 0;
BA_ "GatewayedSignals" SG_ 802 FRR_DTC_VBAT_HIGH 0;
BA_ "GenSigInactiveValue" SG_ 802 FRR_DTC_VBAT_HIGH 0;
BA_ "GenSigInvalidValue" SG_ 802 FRR_DTC_VBAT_HIGH 0;
BA_ "GenSigSendType" SG_ 802 FRR_DTC_VBAT_HIGH 1;
BA_ "GenSigStartValue" SG_ 802 FRR_DTC_VBAT_HIGH 0;
BA_ "GenSigTimeoutValue" SG_ 802 FRR_DTC_VBAT_HIGH 0;
BA_ "Remark" SG_ 802 FRR_DTC_VBAT_HIGH "";
BA_ "EventCommandSignal" SG_ 802 FRR_DTC_VBAT_LOW 0;
BA_ "GatewayedSignals" SG_ 802 FRR_DTC_VBAT_LOW 0;
BA_ "GenSigInactiveValue" SG_ 802 FRR_DTC_VBAT_LOW 0;
BA_ "GenSigInvalidValue" SG_ 802 FRR_DTC_VBAT_LOW 0;
BA_ "GenSigSendType" SG_ 802 FRR_DTC_VBAT_LOW 1;
BA_ "GenSigStartValue" SG_ 802 FRR_DTC_VBAT_LOW 0;
BA_ "GenSigTimeoutValue" SG_ 802 FRR_DTC_VBAT_LOW 0;
BA_ "Remark" SG_ 802 FRR_DTC_VBAT_LOW "";
BA_ "EventCommandSignal" SG_ 802 FRR_EOL_CalibrationSts 0;
BA_ "GatewayedSignals" SG_ 802 FRR_EOL_CalibrationSts 0;
BA_ "GenSigInactiveValue" SG_ 802 FRR_EOL_CalibrationSts 0;
BA_ "GenSigInvalidValue" SG_ 802 FRR_EOL_CalibrationSts 0;
BA_ "GenSigSendType" SG_ 802 FRR_EOL_CalibrationSts 1;
BA_ "GenSigStartValue" SG_ 802 FRR_EOL_CalibrationSts 255;
BA_ "GenSigTimeoutValue" SG_ 802 FRR_EOL_CalibrationSts 0;
BA_ "Remark" SG_ 802 FRR_EOL_CalibrationSts "";
BA_ "EventCommandSignal" SG_ 802 FRR_Misalignment_FaultSts 0;
BA_ "GatewayedSignals" SG_ 802 FRR_Misalignment_FaultSts 0;
BA_ "GenSigInactiveValue" SG_ 802 FRR_Misalignment_FaultSts 0;
BA_ "GenSigInvalidValue" SG_ 802 FRR_Misalignment_FaultSts 0;
BA_ "GenSigSendType" SG_ 802 FRR_Misalignment_FaultSts 1;
BA_ "GenSigStartValue" SG_ 802 FRR_Misalignment_FaultSts 0;
BA_ "GenSigTimeoutValue" SG_ 802 FRR_Misalignment_FaultSts 0;
BA_ "Remark" SG_ 802 FRR_Misalignment_FaultSts "";
BA_ "EventCommandSignal" SG_ 802 FRR_ModulationSts 0;
BA_ "GatewayedSignals" SG_ 802 FRR_ModulationSts 0;
BA_ "GenSigInactiveValue" SG_ 802 FRR_ModulationSts 0;
BA_ "GenSigInvalidValue" SG_ 802 FRR_ModulationSts 0;
BA_ "GenSigSendType" SG_ 802 FRR_ModulationSts 1;
BA_ "GenSigStartValue" SG_ 802 FRR_ModulationSts 0;
BA_ "GenSigTimeoutValue" SG_ 802 FRR_ModulationSts 0;
BA_ "Remark" SG_ 802 FRR_ModulationSts "";
BA_ "EventCommandSignal" SG_ 802 FRR_RadarInfor_AliveCounter 0;
BA_ "GatewayedSignals" SG_ 802 FRR_RadarInfor_AliveCounter 0;
BA_ "GenSigInactiveValue" SG_ 802 FRR_RadarInfor_AliveCounter 0;
BA_ "GenSigInvalidValue" SG_ 802 FRR_RadarInfor_AliveCounter 0;
BA_ "GenSigSendType" SG_ 802 FRR_RadarInfor_AliveCounter 1;
BA_ "GenSigStartValue" SG_ 802 FRR_RadarInfor_AliveCounter 0;
BA_ "GenSigTimeoutValue" SG_ 802 FRR_RadarInfor_AliveCounter 0;
BA_ "Remark" SG_ 802 FRR_RadarInfor_AliveCounter "";
BA_ "EventCommandSignal" SG_ 802 FRR_RadarInfor_Checksum 0;
BA_ "GatewayedSignals" SG_ 802 FRR_RadarInfor_Checksum 0;
BA_ "GenSigInactiveValue" SG_ 802 FRR_RadarInfor_Checksum 0;
BA_ "GenSigInvalidValue" SG_ 802 FRR_RadarInfor_Checksum 0;
BA_ "GenSigSendType" SG_ 802 FRR_RadarInfor_Checksum 1;
BA_ "GenSigStartValue" SG_ 802 FRR_RadarInfor_Checksum 0;
BA_ "GenSigTimeoutValue" SG_ 802 FRR_RadarInfor_Checksum 0;
BA_ "Remark" SG_ 802 FRR_RadarInfor_Checksum "";
BA_ "EventCommandSignal" SG_ 802 FRR_Radar_FaultSts 0;
BA_ "GatewayedSignals" SG_ 802 FRR_Radar_FaultSts 0;
BA_ "GenSigInactiveValue" SG_ 802 FRR_Radar_FaultSts 0;
BA_ "GenSigInvalidValue" SG_ 802 FRR_Radar_FaultSts 0;
BA_ "GenSigSendType" SG_ 802 FRR_Radar_FaultSts 1;
BA_ "GenSigStartValue" SG_ 802 FRR_Radar_FaultSts 0;
BA_ "GenSigTimeoutValue" SG_ 802 FRR_Radar_FaultSts 0;
BA_ "Remark" SG_ 802 FRR_Radar_FaultSts "";
BA_ "EventCommandSignal" SG_ 802 FRR_SDA_CalibrationSts 0;
BA_ "GatewayedSignals" SG_ 802 FRR_SDA_CalibrationSts 0;
BA_ "GenSigInactiveValue" SG_ 802 FRR_SDA_CalibrationSts 0;
BA_ "GenSigInvalidValue" SG_ 802 FRR_SDA_CalibrationSts 0;
BA_ "GenSigSendType" SG_ 802 FRR_SDA_CalibrationSts 1;
BA_ "GenSigStartValue" SG_ 802 FRR_SDA_CalibrationSts 255;
BA_ "GenSigTimeoutValue" SG_ 802 FRR_SDA_CalibrationSts 0;
BA_ "Remark" SG_ 802 FRR_SDA_CalibrationSts "";
BA_ "EventCommandSignal" SG_ 802 FRR_SW_Baseline 0;
BA_ "GatewayedSignals" SG_ 802 FRR_SW_Baseline 0;
BA_ "GenSigInactiveValue" SG_ 802 FRR_SW_Baseline 0;
BA_ "GenSigInvalidValue" SG_ 802 FRR_SW_Baseline 0;
BA_ "GenSigSendType" SG_ 802 FRR_SW_Baseline 1;
BA_ "GenSigStartValue" SG_ 802 FRR_SW_Baseline 0;
BA_ "GenSigTimeoutValue" SG_ 802 FRR_SW_Baseline 0;
BA_ "Remark" SG_ 802 FRR_SW_Baseline "";
BA_ "EventCommandSignal" SG_ 802 FRR_SW_MajorVersion 0;
BA_ "GatewayedSignals" SG_ 802 FRR_SW_MajorVersion 0;
BA_ "GenSigInactiveValue" SG_ 802 FRR_SW_MajorVersion 0;
BA_ "GenSigInvalidValue" SG_ 802 FRR_SW_MajorVersion 0;
BA_ "GenSigSendType" SG_ 802 FRR_SW_MajorVersion 1;
BA_ "GenSigStartValue" SG_ 802 FRR_SW_MajorVersion 0;
BA_ "GenSigTimeoutValue" SG_ 802 FRR_SW_MajorVersion 0;
BA_ "Remark" SG_ 802 FRR_SW_MajorVersion "";
BA_ "EventCommandSignal" SG_ 802 FRR_SW_MinorVersion 0;
BA_ "GatewayedSignals" SG_ 802 FRR_SW_MinorVersion 0;
BA_ "GenSigInactiveValue" SG_ 802 FRR_SW_MinorVersion 0;
BA_ "GenSigInvalidValue" SG_ 802 FRR_SW_MinorVersion 0;
BA_ "GenSigSendType" SG_ 802 FRR_SW_MinorVersion 1;
BA_ "GenSigStartValue" SG_ 802 FRR_SW_MinorVersion 0;
BA_ "GenSigTimeoutValue" SG_ 802 FRR_SW_MinorVersion 0;
BA_ "Remark" SG_ 802 FRR_SW_MinorVersion "";
BA_ "EventCommandSignal" SG_ 802 FRR_SW_ReleaseType 0;
BA_ "GatewayedSignals" SG_ 802 FRR_SW_ReleaseType 0;
BA_ "GenSigInactiveValue" SG_ 802 FRR_SW_ReleaseType 0;
BA_ "GenSigInvalidValue" SG_ 802 FRR_SW_ReleaseType 0;
BA_ "GenSigSendType" SG_ 802 FRR_SW_ReleaseType 1;
BA_ "GenSigStartValue" SG_ 802 FRR_SW_ReleaseType 0;
BA_ "GenSigTimeoutValue" SG_ 802 FRR_SW_ReleaseType 0;
BA_ "Remark" SG_ 802 FRR_SW_ReleaseType "";
BA_ "EventCommandSignal" SG_ 802 Fault_MAL_HOR_ABS_EVENT 0;
BA_ "GatewayedSignals" SG_ 802 Fault_MAL_HOR_ABS_EVENT 0;
BA_ "GenSigInactiveValue" SG_ 802 Fault_MAL_HOR_ABS_EVENT 0;
BA_ "GenSigInvalidValue" SG_ 802 Fault_MAL_HOR_ABS_EVENT 0;
BA_ "GenSigSendType" SG_ 802 Fault_MAL_HOR_ABS_EVENT 1;
BA_ "GenSigStartValue" SG_ 802 Fault_MAL_HOR_ABS_EVENT 0;
BA_ "GenSigTimeoutValue" SG_ 802 Fault_MAL_HOR_ABS_EVENT 0;
BA_ "Remark" SG_ 802 Fault_MAL_HOR_ABS_EVENT "";
BA_ "EventCommandSignal" SG_ 802 Fault_MAL_HOR_REL_EVENT 0;
BA_ "GatewayedSignals" SG_ 802 Fault_MAL_HOR_REL_EVENT 0;
BA_ "GenSigInactiveValue" SG_ 802 Fault_MAL_HOR_REL_EVENT 0;
BA_ "GenSigInvalidValue" SG_ 802 Fault_MAL_HOR_REL_EVENT 0;
BA_ "GenSigSendType" SG_ 802 Fault_MAL_HOR_REL_EVENT 1;
BA_ "GenSigStartValue" SG_ 802 Fault_MAL_HOR_REL_EVENT 0;
BA_ "GenSigTimeoutValue" SG_ 802 Fault_MAL_HOR_REL_EVENT 0;
BA_ "Remark" SG_ 802 Fault_MAL_HOR_REL_EVENT "";
BA_ "EventCommandSignal" SG_ 802 Fault_MAL_VER_ABS_EVENT 0;
BA_ "GatewayedSignals" SG_ 802 Fault_MAL_VER_ABS_EVENT 0;
BA_ "GenSigInactiveValue" SG_ 802 Fault_MAL_VER_ABS_EVENT 0;
BA_ "GenSigInvalidValue" SG_ 802 Fault_MAL_VER_ABS_EVENT 0;
BA_ "GenSigSendType" SG_ 802 Fault_MAL_VER_ABS_EVENT 1;
BA_ "GenSigStartValue" SG_ 802 Fault_MAL_VER_ABS_EVENT 0;
BA_ "GenSigTimeoutValue" SG_ 802 Fault_MAL_VER_ABS_EVENT 0;
BA_ "Remark" SG_ 802 Fault_MAL_VER_ABS_EVENT "";
BA_ "EventCommandSignal" SG_ 802 Fault_MAL_VER_REL_EVENT 0;
BA_ "GatewayedSignals" SG_ 802 Fault_MAL_VER_REL_EVENT 0;
BA_ "GenSigInactiveValue" SG_ 802 Fault_MAL_VER_REL_EVENT 0;
BA_ "GenSigInvalidValue" SG_ 802 Fault_MAL_VER_REL_EVENT 0;
BA_ "GenSigSendType" SG_ 802 Fault_MAL_VER_REL_EVENT 1;
BA_ "GenSigStartValue" SG_ 802 Fault_MAL_VER_REL_EVENT 0;
BA_ "GenSigTimeoutValue" SG_ 802 Fault_MAL_VER_REL_EVENT 0;
BA_ "Remark" SG_ 802 Fault_MAL_VER_REL_EVENT "";
BA_ "EventCommandSignal" SG_ 802 FilteredPhiSpread 0;
BA_ "GatewayedSignals" SG_ 802 FilteredPhiSpread 0;
BA_ "GenSigInactiveValue" SG_ 802 FilteredPhiSpread 0;
BA_ "GenSigInvalidValue" SG_ 802 FilteredPhiSpread 0;
BA_ "GenSigSendType" SG_ 802 FilteredPhiSpread 1;
BA_ "GenSigStartValue" SG_ 802 FilteredPhiSpread 0;
BA_ "GenSigTimeoutValue" SG_ 802 FilteredPhiSpread 0;
BA_ "Remark" SG_ 802 FilteredPhiSpread "";
BA_ "EventCommandSignal" SG_ 802 azOutOfProfileCause 0;
BA_ "GatewayedSignals" SG_ 802 azOutOfProfileCause 0;
BA_ "GenSigInactiveValue" SG_ 802 azOutOfProfileCause 0;
BA_ "GenSigInvalidValue" SG_ 802 azOutOfProfileCause 0;
BA_ "GenSigSendType" SG_ 802 azOutOfProfileCause 1;
BA_ "GenSigStartValue" SG_ 802 azOutOfProfileCause 0;
BA_ "GenSigTimeoutValue" SG_ 802 azOutOfProfileCause 0;
BA_ "Remark" SG_ 802 azOutOfProfileCause "";
BA_ "EventCommandSignal" SG_ 802 azOutOfSpecCause 0;
BA_ "GatewayedSignals" SG_ 802 azOutOfSpecCause 0;
BA_ "GenSigInactiveValue" SG_ 802 azOutOfSpecCause 0;
BA_ "GenSigInvalidValue" SG_ 802 azOutOfSpecCause 0;
BA_ "GenSigSendType" SG_ 802 azOutOfSpecCause 1;
BA_ "GenSigStartValue" SG_ 802 azOutOfSpecCause 0;
BA_ "GenSigTimeoutValue" SG_ 802 azOutOfSpecCause 0;
BA_ "Remark" SG_ 802 azOutOfSpecCause "";
BA_ "EventCommandSignal" SG_ 802 elOutOfProfileCause 0;
BA_ "GatewayedSignals" SG_ 802 elOutOfProfileCause 0;
BA_ "GenSigInactiveValue" SG_ 802 elOutOfProfileCause 0;
BA_ "GenSigInvalidValue" SG_ 802 elOutOfProfileCause 0;
BA_ "GenSigSendType" SG_ 802 elOutOfProfileCause 1;
BA_ "GenSigStartValue" SG_ 802 elOutOfProfileCause 0;
BA_ "GenSigTimeoutValue" SG_ 802 elOutOfProfileCause 0;
BA_ "Remark" SG_ 802 elOutOfProfileCause "";
BA_ "EventCommandSignal" SG_ 802 elOutOfSpecCause 0;
BA_ "GatewayedSignals" SG_ 802 elOutOfSpecCause 0;
BA_ "GenSigInactiveValue" SG_ 802 elOutOfSpecCause 0;
BA_ "GenSigInvalidValue" SG_ 802 elOutOfSpecCause 0;
BA_ "GenSigSendType" SG_ 802 elOutOfSpecCause 1;
BA_ "GenSigStartValue" SG_ 802 elOutOfSpecCause 0;
BA_ "GenSigTimeoutValue" SG_ 802 elOutOfSpecCause 0;
BA_ "Remark" SG_ 802 elOutOfSpecCause "";
BA_ "EventCommandSignal" SG_ 802 highSpreadIndicator_az 0;
BA_ "GatewayedSignals" SG_ 802 highSpreadIndicator_az 0;
BA_ "GenSigInactiveValue" SG_ 802 highSpreadIndicator_az 0;
BA_ "GenSigInvalidValue" SG_ 802 highSpreadIndicator_az 0;
BA_ "GenSigSendType" SG_ 802 highSpreadIndicator_az 1;
BA_ "GenSigStartValue" SG_ 802 highSpreadIndicator_az 0;
BA_ "GenSigTimeoutValue" SG_ 802 highSpreadIndicator_az 0;
BA_ "Remark" SG_ 802 highSpreadIndicator_az "";
BA_ "EventCommandSignal" SG_ 802 highSpreadIndicator_el 0;
BA_ "GatewayedSignals" SG_ 802 highSpreadIndicator_el 0;
BA_ "GenSigInactiveValue" SG_ 802 highSpreadIndicator_el 0;
BA_ "GenSigInvalidValue" SG_ 802 highSpreadIndicator_el 0;
BA_ "GenSigSendType" SG_ 802 highSpreadIndicator_el 1;
BA_ "GenSigStartValue" SG_ 802 highSpreadIndicator_el 0;
BA_ "GenSigTimeoutValue" SG_ 802 highSpreadIndicator_el 0;
BA_ "Remark" SG_ 802 highSpreadIndicator_el "";
BA_ "EventCommandSignal" SG_ 802 malStablePosAz 0;
BA_ "GatewayedSignals" SG_ 802 malStablePosAz 0;
BA_ "GenSigInactiveValue" SG_ 802 malStablePosAz 0;
BA_ "GenSigInvalidValue" SG_ 802 malStablePosAz 0;
BA_ "GenSigSendType" SG_ 802 malStablePosAz 1;
BA_ "GenSigStartValue" SG_ 802 malStablePosAz 0;
BA_ "GenSigTimeoutValue" SG_ 802 malStablePosAz 0;
BA_ "Remark" SG_ 802 malStablePosAz "";
BA_ "EventCommandSignal" SG_ 802 malStablePosEl 0;
BA_ "GatewayedSignals" SG_ 802 malStablePosEl 0;
BA_ "GenSigInactiveValue" SG_ 802 malStablePosEl 0;
BA_ "GenSigInvalidValue" SG_ 802 malStablePosEl 0;
BA_ "GenSigSendType" SG_ 802 malStablePosEl 1;
BA_ "GenSigStartValue" SG_ 802 malStablePosEl 0;
BA_ "GenSigTimeoutValue" SG_ 802 malStablePosEl 0;
BA_ "Remark" SG_ 802 malStablePosEl "";
BA_ "EventCommandSignal" SG_ 802 mountAngleCurrent_az 0;
BA_ "GatewayedSignals" SG_ 802 mountAngleCurrent_az 0;
BA_ "GenSigInactiveValue" SG_ 802 mountAngleCurrent_az 0;
BA_ "GenSigInvalidValue" SG_ 802 mountAngleCurrent_az 0;
BA_ "GenSigSendType" SG_ 802 mountAngleCurrent_az 1;
BA_ "GenSigStartValue" SG_ 802 mountAngleCurrent_az 0;
BA_ "GenSigTimeoutValue" SG_ 802 mountAngleCurrent_az 0;
BA_ "Remark" SG_ 802 mountAngleCurrent_az "";
BA_ "EventCommandSignal" SG_ 802 mountAngleCurrent_el 0;
BA_ "GatewayedSignals" SG_ 802 mountAngleCurrent_el 0;
BA_ "GenSigInactiveValue" SG_ 802 mountAngleCurrent_el 0;
BA_ "GenSigInvalidValue" SG_ 802 mountAngleCurrent_el 0;
BA_ "GenSigSendType" SG_ 802 mountAngleCurrent_el 1;
BA_ "GenSigStartValue" SG_ 802 mountAngleCurrent_el 0;
BA_ "GenSigTimeoutValue" SG_ 802 mountAngleCurrent_el 0;
BA_ "Remark" SG_ 802 mountAngleCurrent_el "";
BA_ "EventCommandSignal" SG_ 802 mountAngleIndicator_az 0;
BA_ "GatewayedSignals" SG_ 802 mountAngleIndicator_az 0;
BA_ "GenSigInactiveValue" SG_ 802 mountAngleIndicator_az 0;
BA_ "GenSigInvalidValue" SG_ 802 mountAngleIndicator_az 0;
BA_ "GenSigSendType" SG_ 802 mountAngleIndicator_az 1;
BA_ "GenSigStartValue" SG_ 802 mountAngleIndicator_az 0;
BA_ "GenSigTimeoutValue" SG_ 802 mountAngleIndicator_az 0;
BA_ "Remark" SG_ 802 mountAngleIndicator_az "";
BA_ "EventCommandSignal" SG_ 802 mountAngleIndicator_el 0;
BA_ "GatewayedSignals" SG_ 802 mountAngleIndicator_el 0;
BA_ "GenSigInactiveValue" SG_ 802 mountAngleIndicator_el 0;
BA_ "GenSigInvalidValue" SG_ 802 mountAngleIndicator_el 0;
BA_ "GenSigSendType" SG_ 802 mountAngleIndicator_el 1;
BA_ "GenSigStartValue" SG_ 802 mountAngleIndicator_el 0;
BA_ "GenSigTimeoutValue" SG_ 802 mountAngleIndicator_el 0;
BA_ "Remark" SG_ 802 mountAngleIndicator_el "";
BA_ "EventCommandSignal" SG_ 1147 FLR_Diag_Response 1;
BA_ "GatewayedSignals" SG_ 1147 FLR_Diag_Response 0;
BA_ "GenSigInactiveValue" SG_ 1147 FLR_Diag_Response 0;
BA_ "GenSigInvalidValue" SG_ 1147 FLR_Diag_Response 0;
BA_ "GenSigSendType" SG_ 1147 FLR_Diag_Response 0;
BA_ "GenSigStartValue" SG_ 1147 FLR_Diag_Response 0;
BA_ "GenSigTimeoutValue" SG_ 1147 FLR_Diag_Response 0;
BA_ "Remark" SG_ 1147 FLR_Diag_Response "";
BA_ "EventCommandSignal" SG_ 1148 FRR_Diag_Response 1;
BA_ "GatewayedSignals" SG_ 1148 FRR_Diag_Response 0;
BA_ "GenSigInactiveValue" SG_ 1148 FRR_Diag_Response 0;
BA_ "GenSigInvalidValue" SG_ 1148 FRR_Diag_Response 0;
BA_ "GenSigSendType" SG_ 1148 FRR_Diag_Response 0;
BA_ "GenSigStartValue" SG_ 1148 FRR_Diag_Response 0;
BA_ "GenSigTimeoutValue" SG_ 1148 FRR_Diag_Response 0;
BA_ "Remark" SG_ 1148 FRR_Diag_Response "";
BA_ "EventCommandSignal" SG_ 1298 FLR_NMDataField 0;
BA_ "GatewayedSignals" SG_ 1298 FLR_NMDataField 0;
BA_ "GenSigInactiveValue" SG_ 1298 FLR_NMDataField 0;
BA_ "GenSigInvalidValue" SG_ 1298 FLR_NMDataField 0;
BA_ "GenSigSendType" SG_ 1298 FLR_NMDataField 1;
BA_ "GenSigStartValue" SG_ 1298 FLR_NMDataField 0;
BA_ "GenSigTimeoutValue" SG_ 1298 FLR_NMDataField 0;
BA_ "Remark" SG_ 1298 FLR_NMDataField "";
BA_ "EventCommandSignal" SG_ 1298 FLR_NMSourceAddress 0;
BA_ "GatewayedSignals" SG_ 1298 FLR_NMSourceAddress 0;
BA_ "GenSigInactiveValue" SG_ 1298 FLR_NMSourceAddress 0;
BA_ "GenSigInvalidValue" SG_ 1298 FLR_NMSourceAddress 0;
BA_ "GenSigSendType" SG_ 1298 FLR_NMSourceAddress 1;
BA_ "GenSigStartValue" SG_ 1298 FLR_NMSourceAddress 74;
BA_ "GenSigTimeoutValue" SG_ 1298 FLR_NMSourceAddress 0;
BA_ "Remark" SG_ 1298 FLR_NMSourceAddress "";
BA_ "EventCommandSignal" SG_ 1298 FLR_WakeUpPat 0;
BA_ "GatewayedSignals" SG_ 1298 FLR_WakeUpPat 0;
BA_ "GenSigInactiveValue" SG_ 1298 FLR_WakeUpPat 0;
BA_ "GenSigInvalidValue" SG_ 1298 FLR_WakeUpPat 0;
BA_ "GenSigSendType" SG_ 1298 FLR_WakeUpPat 1;
BA_ "GenSigStartValue" SG_ 1298 FLR_WakeUpPat 76;
BA_ "GenSigTimeoutValue" SG_ 1298 FLR_WakeUpPat 0;
BA_ "Remark" SG_ 1298 FLR_WakeUpPat "";
BA_ "EventCommandSignal" SG_ 1312 ADC_SOC_NMDataField 0;
BA_ "GatewayedSignals" SG_ 1312 ADC_SOC_NMDataField 0;
BA_ "GenSigInactiveValue" SG_ 1312 ADC_SOC_NMDataField 0;
BA_ "GenSigInvalidValue" SG_ 1312 ADC_SOC_NMDataField 0;
BA_ "GenSigSendType" SG_ 1312 ADC_SOC_NMDataField 1;
BA_ "GenSigStartValue" SG_ 1312 ADC_SOC_NMDataField 0;
BA_ "GenSigTimeoutValue" SG_ 1312 ADC_SOC_NMDataField 0;
BA_ "Remark" SG_ 1312 ADC_SOC_NMDataField "";
BA_ "EventCommandSignal" SG_ 1312 ADC_SOC_NMSourceAddress 0;
BA_ "GatewayedSignals" SG_ 1312 ADC_SOC_NMSourceAddress 0;
BA_ "GenSigInactiveValue" SG_ 1312 ADC_SOC_NMSourceAddress 0;
BA_ "GenSigInvalidValue" SG_ 1312 ADC_SOC_NMSourceAddress 0;
BA_ "GenSigSendType" SG_ 1312 ADC_SOC_NMSourceAddress 1;
BA_ "GenSigStartValue" SG_ 1312 ADC_SOC_NMSourceAddress 32;
BA_ "GenSigTimeoutValue" SG_ 1312 ADC_SOC_NMSourceAddress 0;
BA_ "Remark" SG_ 1312 ADC_SOC_NMSourceAddress "";
BA_ "EventCommandSignal" SG_ 1312 ADC_SOC_WakeUpPat 0;
BA_ "GatewayedSignals" SG_ 1312 ADC_SOC_WakeUpPat 0;
BA_ "GenSigInactiveValue" SG_ 1312 ADC_SOC_WakeUpPat 0;
BA_ "GenSigInvalidValue" SG_ 1312 ADC_SOC_WakeUpPat 0;
BA_ "GenSigSendType" SG_ 1312 ADC_SOC_WakeUpPat 1;
BA_ "GenSigStartValue" SG_ 1312 ADC_SOC_WakeUpPat 76;
BA_ "GenSigTimeoutValue" SG_ 1312 ADC_SOC_WakeUpPat 0;
BA_ "Remark" SG_ 1312 ADC_SOC_WakeUpPat "";
BA_ "EventCommandSignal" SG_ 1810 FLR_Diag_Request 0;
BA_ "GatewayedSignals" SG_ 1810 FLR_Diag_Request 0;
BA_ "GenSigInactiveValue" SG_ 1810 FLR_Diag_Request 0;
BA_ "GenSigInvalidValue" SG_ 1810 FLR_Diag_Request 0;
BA_ "GenSigSendType" SG_ 1810 FLR_Diag_Request 1;
BA_ "GenSigStartValue" SG_ 1810 FLR_Diag_Request 0;
BA_ "GenSigTimeoutValue" SG_ 1810 FLR_Diag_Request 0;
BA_ "Remark" SG_ 1810 FLR_Diag_Request "";
BA_ "EventCommandSignal" SG_ 1811 FRR_Diag_Request 0;
BA_ "GatewayedSignals" SG_ 1811 FRR_Diag_Request 0;
BA_ "GenSigInactiveValue" SG_ 1811 FRR_Diag_Request 0;
BA_ "GenSigInvalidValue" SG_ 1811 FRR_Diag_Request 0;
BA_ "GenSigSendType" SG_ 1811 FRR_Diag_Request 1;
BA_ "GenSigStartValue" SG_ 1811 FRR_Diag_Request 0;
BA_ "GenSigTimeoutValue" SG_ 1811 FRR_Diag_Request 0;
BA_ "Remark" SG_ 1811 FRR_Diag_Request "";
BA_ "EventCommandSignal" SG_ 1938 FLR_Diag_Response 0;
BA_ "GatewayedSignals" SG_ 1938 FLR_Diag_Response 0;
BA_ "GenSigInactiveValue" SG_ 1938 FLR_Diag_Response 0;
BA_ "GenSigInvalidValue" SG_ 1938 FLR_Diag_Response 0;
BA_ "GenSigSendType" SG_ 1938 FLR_Diag_Response 1;
BA_ "GenSigStartValue" SG_ 1938 FLR_Diag_Response 0;
BA_ "GenSigTimeoutValue" SG_ 1938 FLR_Diag_Response 0;
BA_ "Remark" SG_ 1938 FLR_Diag_Response "";
BA_ "EventCommandSignal" SG_ 1939 FRR_Diag_Response 0;
BA_ "GatewayedSignals" SG_ 1939 FRR_Diag_Response 0;
BA_ "GenSigInactiveValue" SG_ 1939 FRR_Diag_Response 0;
BA_ "GenSigInvalidValue" SG_ 1939 FRR_Diag_Response 0;
BA_ "GenSigSendType" SG_ 1939 FRR_Diag_Response 1;
BA_ "GenSigStartValue" SG_ 1939 FRR_Diag_Response 0;
BA_ "GenSigTimeoutValue" SG_ 1939 FRR_Diag_Response 0;
BA_ "Remark" SG_ 1939 FRR_Diag_Response "";
BA_ "EventCommandSignal" SG_ 2015 Func_Diag_Request 0;
BA_ "GatewayedSignals" SG_ 2015 Func_Diag_Request 0;
BA_ "GenSigInactiveValue" SG_ 2015 Func_Diag_Request 0;
BA_ "GenSigInvalidValue" SG_ 2015 Func_Diag_Request 0;
BA_ "GenSigSendType" SG_ 2015 Func_Diag_Request 1;
BA_ "GenSigStartValue" SG_ 2015 Func_Diag_Request 0;
BA_ "GenSigTimeoutValue" SG_ 2015 Func_Diag_Request 0;
BA_ "Remark" SG_ 2015 Func_Diag_Request "";
BA_ "GenMsgILSupport" BO_ 1147 0;
BA_ "GenMsgILSupport" BO_ 1148 0;
BA_ "GenMsgILSupport" BO_ 1298 0;
BA_ "GenMsgILSupport" BO_ 1810 0;
BA_ "GenMsgILSupport" BO_ 1811 0;
BA_ "GenMsgILSupport" BO_ 1938 0;
BA_ "GenMsgILSupport" BO_ 1939 0;
BA_ "GenMsgILSupport" BO_ 2015 0;
BA_ "MsgType" BO_ 1147 0;
BA_ "MsgType" BO_ 1148 0;
BA_ "MsgType" BO_ 1298 0;
BA_ "MsgType" BO_ 1312 0;
BA_ "MsgType" BO_ 1810 0;
BA_ "MsgType" BO_ 1811 0;
BA_ "MsgType" BO_ 1938 0;
BA_ "MsgType" BO_ 1939 0;
BA_ "MsgType" BO_ 2015 0;
BA_ "MsgType" BO_ 791 0;
BA_ "MsgType" BO_ 792 0;
BA_ "MsgType" BO_ 793 0;
BA_ "MsgType" BO_ 794 0;
BA_ "MsgType" BO_ 795 0;
BA_ "MsgType" BO_ 796 0;
BA_ "MsgType" BO_ 797 0;
BA_ "MsgType" BO_ 798 0;
BA_ "MsgType" BO_ 799 0;
BA_ "MsgType" BO_ 800 0;
BA_ "MsgType" BO_ 801 0;
BA_ "MsgType" BO_ 802 0;
BA_ "NmAsrMessage" BO_ 1298 1;
BA_ "NmAsrMessage" BO_ 1312 1;
BA_ "IsCrcSignal" SG_ 791 SGU22_Msg_CheckSum 1;
BA_ "IsCrcSignal" SG_ 792 SGU23_Msg_CheckSum 1;
BA_ "IsCrcSignal" SG_ 793 SGU24_Msg_CheckSum 1;
BA_ "IsCrcSignal" SG_ 794 SGU25_Msg_CheckSum 1;
BA_ "IsCrcSignal" SG_ 795 SGU26_Msg_CheckSum 1;
BA_ "IsCrcSignal" SG_ 796 SGU27_Msg_CheckSum 1;
BA_ "IsCrcSignal" SG_ 797 SGU28_Msg_CheckSum 1;
BA_ "IsCrcSignal" SG_ 798 SGU29_Msg_CheckSum 1;
BA_ "IsCrcSignal" SG_ 799 SGU30_Msg_CheckSum 1;
BA_ "IsCrcSignal" SG_ 800 SGU31_Msg_CheckSum 1;
BA_ "IsCrcSignal" SG_ 801 SGU32_Msg_CheckSum 1;
BA_ "SystemSignalLongSymbol" SG_ 802 FRR_DTC_RADAR_OVER_TEMPERATURE "FR_DTC_RADAR_OVER_TEMPERATURE_Can03";
BA_ "SystemSignalLongSymbol" SG_ 802 FRR_DTC_VARIANT_SELECTION_NOT_DONE "FR_DTC_VARIANT_SELECTION_NOT_DONE_Can03";
BA_ "IsCrcSignal" SG_ 802 FRR_RadarInfor_Checksum 1;
VAL_ 791 SGU22_Object_DetStatus 0 "deleted" 1 "new" 2 "measured" 3 "predicted" 4 "deleted for merge" 5 "new from  merge"  ;
VAL_ 791 SGU22_Object_Motion_Pattern 0 "Unknown" 1 "Stationary" 2 "Stopped" 3 "Moving"  ;
VAL_ 791 SGU22_Object_Type 0 "Unknown" 1 "4 wheeler" 2 "2 wheeler" 3 "Pedestrian"  ;
VAL_ 792 SGU23_Object_DetStatus 0 "deleted" 1 "new" 2 "measured" 3 "predicted" 4 "deleted for merge" 5 "new from  merge"  ;
VAL_ 792 SGU23_Object_Motion_Pattern 0 "Unknown" 1 "Stationary" 2 "Stopped" 3 "Moving"  ;
VAL_ 792 SGU23_Object_Type 0 "Unknown" 1 "4 wheeler" 2 "2 wheeler" 3 "Pedestrian"  ;
VAL_ 793 SGU24_Object_DetStatus 0 "deleted" 1 "new" 2 "measured" 3 "predicted" 4 "deleted for merge" 5 "new from  merge"  ;
VAL_ 793 SGU24_Object_Motion_Pattern 0 "Unknown" 1 "Stationary" 2 "Stopped" 3 "Moving"  ;
VAL_ 793 SGU24_Object_Type 0 "Unknown" 1 "4 wheeler" 2 "2 wheeler" 3 "Pedestrian"  ;
VAL_ 794 SGU25_Object_DetStatus 0 "deleted" 1 "new" 2 "measured" 3 "predicted" 4 "deleted for merge" 5 "new from  merge"  ;
VAL_ 794 SGU25_Object_Motion_Pattern 0 "Unknown" 1 "Stationary" 2 "Stopped" 3 "Moving"  ;
VAL_ 794 SGU25_Object_Type 0 "Unknown" 1 "4 wheeler" 2 "2 wheeler" 3 "Pedestrian"  ;
VAL_ 795 SGU26_Object_DetStatus 0 "deleted" 1 "new" 2 "measured" 3 "predicted" 4 "deleted for merge" 5 "new from  merge"  ;
VAL_ 795 SGU26_Object_Motion_Pattern 0 "Unknown" 1 "Stationary" 2 "Stopped" 3 "Moving"  ;
VAL_ 795 SGU26_Object_Type 0 "Unknown" 1 "4 wheeler" 2 "2 wheeler" 3 "Pedestrian"  ;
VAL_ 796 SGU27_Object_DetStatus 0 "deleted" 1 "new" 2 "measured" 3 "predicted" 4 "deleted for merge" 5 "new from  merge"  ;
VAL_ 796 SGU27_Object_Motion_Pattern 0 "Unknown" 1 "Stationary" 2 "Stopped" 3 "Moving"  ;
VAL_ 796 SGU27_Object_Type 0 "Unknown" 1 "4 wheeler" 2 "2 wheeler" 3 "Pedestrian"  ;
VAL_ 797 SGU28_Object_DetStatus 0 "deleted" 1 "new" 2 "measured" 3 "predicted" 4 "deleted for merge" 5 "new from  merge"  ;
VAL_ 797 SGU28_Object_Motion_Pattern 0 "Unknown" 1 "Stationary" 2 "Stopped" 3 "Moving"  ;
VAL_ 797 SGU28_Object_Type 0 "Unknown" 1 "4 wheeler" 2 "2 wheeler" 3 "Pedestrian"  ;
VAL_ 798 SGU29_Object_DetStatus 0 "deleted" 1 "new" 2 "measured" 3 "predicted" 4 "deleted for merge" 5 "new from  merge"  ;
VAL_ 798 SGU29_Object_Motion_Pattern 0 "Unknown" 1 "Stationary" 2 "Stopped" 3 "Moving"  ;
VAL_ 798 SGU29_Object_Type 0 "Unknown" 1 "4 wheeler" 2 "2 wheeler" 3 "Pedestrian"  ;
VAL_ 799 SGU30_Object_DetStatus 0 "deleted" 1 "new" 2 "measured" 3 "predicted" 4 "deleted for merge" 5 "new from  merge"  ;
VAL_ 799 SGU30_Object_Motion_Pattern 0 "Unknown" 1 "Stationary" 2 "Stopped" 3 "Moving"  ;
VAL_ 799 SGU30_Object_Type 0 "Unknown" 1 "4 wheeler" 2 "2 wheeler" 3 "Pedestrian"  ;
VAL_ 800 SGU31_Object_DetStatus 0 "deleted" 1 "new" 2 "measured" 3 "predicted" 4 "deleted for merge" 5 "new from  merge"  ;
VAL_ 800 SGU31_Object_Motion_Pattern 0 "Unknown" 1 "Stationary" 2 "Stopped" 3 "Moving"  ;
VAL_ 800 SGU31_Object_Type 0 "Unknown" 1 "4 wheeler" 2 "2 wheeler" 3 "Pedestrian"  ;
VAL_ 801 SGU32_Object_DetStatus 0 "deleted" 1 "new" 2 "measured" 3 "predicted" 4 "deleted for merge" 5 "new from  merge"  ;
VAL_ 801 SGU32_Object_Motion_Pattern 0 "Unknown" 1 "Stationary" 2 "Stopped" 3 "Moving"  ;
VAL_ 801 SGU32_Object_Type 0 "Unknown" 1 "4 wheeler" 2 "2 wheeler" 3 "Pedestrian"  ;
VAL_ 802 FRR_Blindness_FaultSts 0 "No Blindness" 1 "Blindness"  ;
VAL_ 802 FRR_DTC_ALIGNMENT_NOT_DONE 0 "No Fail" 1 "Fail"  ;
VAL_ 802 FRR_DTC_CORNER_RADAR_BLIND 0 "No Fail" 1 "Fail"  ;
VAL_ 802 FRR_DTC_CORNER_RADAR_MISALIGNED 0 "No Fail" 1 "Fail"  ;
VAL_ 802 FRR_DTC_DACORE_OOS 0 "No Fail" 1 "Fail"  ;
VAL_ 802 FRR_DTC_DSP_FAILURE 0 "No Fail" 1 "Fail"  ;
VAL_ 802 FRR_DTC_HARDWARE_FAILURE 0 "No Fail" 1 "Fail"  ;
VAL_ 802 FRR_DTC_INVALID_DATA_BCS 0 "No Fail" 1 "Fail"  ;
VAL_ 802 FRR_DTC_INVALID_DATA_EPS 0 "No Fail" 1 "Fail"  ;
VAL_ 802 FRR_DTC_INVALID_DATA_SOC 0 "No Fail" 1 "Fail"  ;
VAL_ 802 FRR_DTC_LOST_COMM_BCS 0 "No Fail" 1 "Fail"  ;
VAL_ 802 FRR_DTC_LOST_COMM_EPS 0 "No Fail" 1 "Fail"  ;
VAL_ 802 FRR_DTC_LOST_COMM_SOC 0 "No Fail" 1 "Fail"  ;
VAL_ 802 FRR_DTC_PUBLIC_CAN_BUSOFF 0 "No Fail" 1 "Fail"  ;
VAL_ 802 FRR_DTC_RADAR_OVER_TEMPERATURE 0 "No Fail" 1 "Fail"  ;
VAL_ 802 FRR_DTC_RADAR_SIDE_MISMATCH 0 "No Fail" 1 "Fail"  ;
VAL_ 802 FRR_DTC_SOC_Time_SYNC_FAIL 0 "No Fail" 1 "Fail"  ;
VAL_ 802 FRR_DTC_VARIANT_SELECTION_NOT_DONE 0 "No Fail" 1 "Fail"  ;
VAL_ 802 FRR_DTC_VBAT_HIGH 0 "No Fail" 1 "Fail"  ;
VAL_ 802 FRR_DTC_VBAT_LOW 0 "No Fail" 1 "Fail"  ;
VAL_ 802 FRR_EOL_CalibrationSts 0 "successfully calibrated" 1 "time out" 2 "target is missing" 3 "target distance is not correct" 4 "Horizontal bad angle" 5 "Vertical bad angle" 6 "NVM error" 7 "Cancelled by user" 255 "Not done calibration"  ;
VAL_ 802 FRR_Misalignment_FaultSts 0 "Aligned" 1 "Misaligned"  ;
VAL_ 802 FRR_ModulationSts 0 "On" 1 "Off"  ;
VAL_ 802 FRR_Radar_FaultSts 0 "No Fail" 1 "Fail" 0 "No Fail" 1 "Fail" 0 "No Fail" 1 "Fail" 0 "No Fail" 1 "Fail" 0 "No Fail" 1 "Fail"  ;
VAL_ 802 FRR_SDA_CalibrationSts 0 "successfully calibrated" 1 "calibration is processing" 2 "calibration is failed" 3 "cancelled by user" 255 "routine not started"  ;
VAL_ 802 FRR_SW_ReleaseType 0 "V(Version)" 1 "RC(Release Candidate)" 2 "LC (Local Release)"  ;
VAL_ 802 Fault_MAL_HOR_ABS_EVENT 0 "Not Fault" 1 "Fault"  ;
VAL_ 802 Fault_MAL_HOR_REL_EVENT 0 "Not Fault" 1 "Fault"  ;
VAL_ 802 Fault_MAL_VER_ABS_EVENT 0 "Not Fault" 1 "Fault"  ;
VAL_ 802 Fault_MAL_VER_REL_EVENT 0 "Not Fault" 1 "Fault"  ;
VAL_ 802 azOutOfProfileCause 0 "No Out" 1 "Out"  ;
VAL_ 802 azOutOfSpecCause 0 "No Out" 1 "Out"  ;
VAL_ 802 elOutOfProfileCause 0 "No Out" 1 "Out"  ;
VAL_ 802 elOutOfSpecCause 0 "No Out" 1 "Out"  ;
